[part 16 of 22: packages /Cluster to /NmConfig]
AUTOSAR XML (schema 4-3-0)
package /Cluster  (continued)
  9 x lin cluster, all with baudrate=19200, protocol-name=LIN, protocol-version=2.0:  (continued)
    E3V_SAM_LIN4
      lin physical channel CHNL: comm-connectors=CN_E3V_SAM_LIN4
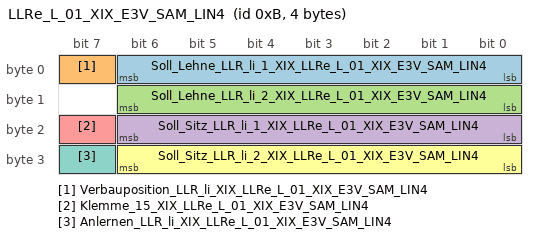
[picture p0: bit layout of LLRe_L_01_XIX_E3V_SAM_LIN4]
        frame LLRe_L_01_XIX_E3V_SAM_LIN4: id 0xB, from SAM, frame-length=4, lin-checksum=ENHANCED
          pdu LLRe_L_01_XIX_E3V_SAM_LIN4: length=4, unused-bit-pattern=0
            signal Soll_Lehne_LLR_li_1_XIX_LLRe_L_01_XIX_E3V_SAM_LIN4: start 0, 7 bit, little-endian, data-type-policy=OVERRIDE, i-signal-type=PRIMITIVE, init-value=0, base-type=BT_Soll_Lehne_LLR_li_1, compu {phys=raw for raw 0..100; unit Unit_PerCent}, range phys 0..100 Unit_PerCent, raw 0..100, unit=Unit_PerCent, transfer-property=PENDING  # Ansteuerung Sitzluefter PWM in %
            signal Verbauposition_LLR_li_XIX_LLRe_L_01_XIX_E3V_SAM_LIN4: start 7, 1 bit, little-endian, data-type-policy=OVERRIDE, i-signal-type=PRIMITIVE, base-type=BT_Verbauposition_LLR_li, compu {0=Cx0_vorne (CM_Verbauposition_LLR_li_Cx0_vorne), 1=Cx1_hinten (CM_Verbauposition_LLR_li_Cx1_hinten)}, range raw 0..1, transfer-property=PENDING  # Verbauposition vorne/hinten für eindeutige Diagnose/Identifikation. Signal für hinten ist immer 0x1, Signal für vorne ist immer 0x0.
            signal Soll_Lehne_LLR_li_2_XIX_LLRe_L_01_XIX_E3V_SAM_LIN4: start 8, 7 bit, little-endian, data-type-policy=OVERRIDE, i-signal-type=PRIMITIVE, init-value=0, base-type=BT_Soll_Lehne_LLR_li_2, compu {phys=raw for raw 0..100; unit Unit_PerCent}, range phys 0..100 Unit_PerCent, raw 0..100, unit=Unit_PerCent, transfer-property=PENDING  # Ansteuerung Sitzluefter PWM in %
            signal Soll_Sitz_LLR_li_1_XIX_LLRe_L_01_XIX_E3V_SAM_LIN4: start 16, 7 bit, little-endian, data-type-policy=OVERRIDE, i-signal-type=PRIMITIVE, init-value=0, base-type=BT_Soll_Sitz_LLR_li_1, compu {phys=raw for raw 0..100; unit Unit_PerCent}, range phys 0..100 Unit_PerCent, raw 0..100, unit=Unit_PerCent, transfer-property=PENDING  # Ansteuerung Sitzluefter PWM in %
            signal Klemme_15_XIX_LLRe_L_01_XIX_E3V_SAM_LIN4: start 23, 1 bit, little-endian, data-type-policy=OVERRIDE, i-signal-type=PRIMITIVE, init-value=0, base-type=BT_Klemme_15, compu {0=Cx0_Aus (CM_Klemme_15_Cx0_Aus), 1=Cx1_Ein (CM_Klemme_15_Cx1_Ein)}, range raw 0..1, transfer-property=PENDING
            signal Soll_Sitz_LLR_li_2_XIX_LLRe_L_01_XIX_E3V_SAM_LIN4: start 24, 7 bit, little-endian, data-type-policy=OVERRIDE, i-signal-type=PRIMITIVE, init-value=0, base-type=BT_Soll_Sitz_LLR_li_2, compu {phys=raw for raw 0..100; unit Unit_PerCent}, range phys 0..100 Unit_PerCent, raw 0..100, unit=Unit_PerCent, transfer-property=PENDING  # Ansteuerung Sitzluefter PWM in %
            signal Anlernen_LLR_li_XIX_LLRe_L_01_XIX_E3V_SAM_LIN4: start 31, 1 bit, little-endian, data-type-policy=OVERRIDE, i-signal-type=PRIMITIVE, init-value=0, base-type=BT_Anlernen_LLR_li, compu {0=Cx0_Init (CM_Anlernen_LLR_li_Cx0_Init), 1=Cx1_Adresse_lernen (CM_Anlernen_LLR_li_Cx1_Adresse_lernen)}, range raw 0..1, transfer-property=PENDING  # Triggersignale zum Anlernen der Slave SG abhängig vom CodierPin
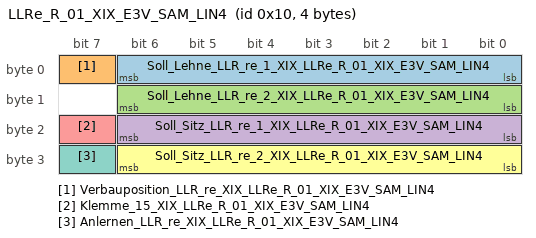
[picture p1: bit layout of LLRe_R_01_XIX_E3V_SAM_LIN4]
        frame LLRe_R_01_XIX_E3V_SAM_LIN4: id 0x10, from SAM, frame-length=4, lin-checksum=ENHANCED
          pdu LLRe_R_01_XIX_E3V_SAM_LIN4: length=4, unused-bit-pattern=0
            signal Soll_Lehne_LLR_re_1_XIX_LLRe_R_01_XIX_E3V_SAM_LIN4: start 0, 7 bit, little-endian, data-type-policy=OVERRIDE, i-signal-type=PRIMITIVE, init-value=0, base-type=BT_Soll_Lehne_LLR_re_1, compu {phys=raw for raw 0..100; unit Unit_PerCent}, range phys 0..100 Unit_PerCent, raw 0..100, unit=Unit_PerCent, transfer-property=PENDING  # Ansteuerung Sitzluefter PWM in %
            signal Verbauposition_LLR_re_XIX_LLRe_R_01_XIX_E3V_SAM_LIN4: start 7, 1 bit, little-endian, data-type-policy=OVERRIDE, i-signal-type=PRIMITIVE, base-type=BT_Verbauposition_LLR_re, compu {0=Cx0_vorne (CM_Verbauposition_LLR_re_Cx0_vorne), 1=Cx1_hinten (CM_Verbauposition_LLR_re_Cx1_hinten)}, range raw 0..1, transfer-property=PENDING  # Verbauposition vorne/hinten für eindeutige Diagnose/Identifikation. Signal für hinten ist immer 0x1, Signal für vorne ist immer 0x0.
            signal Soll_Lehne_LLR_re_2_XIX_LLRe_R_01_XIX_E3V_SAM_LIN4: start 8, 7 bit, little-endian, data-type-policy=OVERRIDE, i-signal-type=PRIMITIVE, init-value=0, base-type=BT_Soll_Lehne_LLR_re_2, compu {phys=raw for raw 0..100; unit Unit_PerCent}, range phys 0..100 Unit_PerCent, raw 0..100, unit=Unit_PerCent, transfer-property=PENDING  # Ansteuerung Sitzluefter PWM in %
            signal Soll_Sitz_LLR_re_1_XIX_LLRe_R_01_XIX_E3V_SAM_LIN4: start 16, 7 bit, little-endian, data-type-policy=OVERRIDE, i-signal-type=PRIMITIVE, init-value=0, base-type=BT_Soll_Sitz_LLR_re_1, compu {phys=raw for raw 0..100; unit Unit_PerCent}, range phys 0..100 Unit_PerCent, raw 0..100, unit=Unit_PerCent, transfer-property=PENDING  # Ansteuerung Sitzluefter PWM in %
            signal Klemme_15_XIX_LLRe_R_01_XIX_E3V_SAM_LIN4: start 23, 1 bit, little-endian, data-type-policy=OVERRIDE, i-signal-type=PRIMITIVE, init-value=0, base-type=BT_Klemme_15, compu {0=Cx0_Aus (CM_Klemme_15_Cx0_Aus), 1=Cx1_Ein (CM_Klemme_15_Cx1_Ein)}, range raw 0..1, transfer-property=PENDING
            signal Soll_Sitz_LLR_re_2_XIX_LLRe_R_01_XIX_E3V_SAM_LIN4: start 24, 7 bit, little-endian, data-type-policy=OVERRIDE, i-signal-type=PRIMITIVE, init-value=0, base-type=BT_Soll_Sitz_LLR_re_2, compu {phys=raw for raw 0..100; unit Unit_PerCent}, range phys 0..100 Unit_PerCent, raw 0..100, unit=Unit_PerCent, transfer-property=PENDING  # Ansteuerung Sitzluefter PWM in %
            signal Anlernen_LLR_re_XIX_LLRe_R_01_XIX_E3V_SAM_LIN4: start 31, 1 bit, little-endian, data-type-policy=OVERRIDE, i-signal-type=PRIMITIVE, init-value=0, base-type=BT_Anlernen_LLR_re, compu {0=Cx0_Init (CM_Anlernen_LLR_re_Cx0_Init), 1=Cx1_Adresse_lernen (CM_Anlernen_LLR_re_Cx1_Adresse_lernen)}, range raw 0..1, transfer-property=PENDING  # Triggersignale zum Anlernen der Slave SG abhängig vom CodierPin
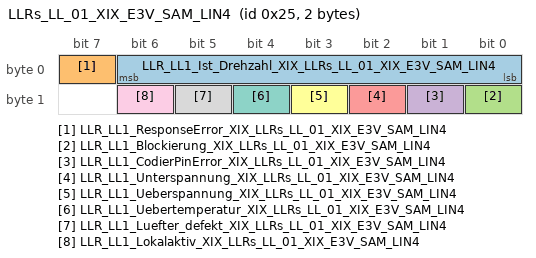
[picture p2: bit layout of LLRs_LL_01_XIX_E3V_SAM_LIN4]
        frame LLRs_LL_01_XIX_E3V_SAM_LIN4: id 0x25, to SAM, frame-length=2, lin-checksum=ENHANCED
          pdu LLRs_LL_01_XIX_E3V_SAM_LIN4: length=2, unused-bit-pattern=0
            signal LLR_LL1_Ist_Drehzahl_XIX_LLRs_LL_01_XIX_E3V_SAM_LIN4: start 0, 7 bit, little-endian, data-type-policy=OVERRIDE, i-signal-type=PRIMITIVE, init-value=0, base-type=BT_LLR_LL1_Ist_Drehzahl, compu {phys=raw for raw 0..100; unit Unit_PerCent}, range phys 0..100 Unit_PerCent, raw 0..100, unit=Unit_PerCent, transfer-property=PENDING, to SAM(timeout 3.5 s)  # Fehlende Beschreibung (Import)
            signal LLR_LL1_ResponseError_XIX_LLRs_LL_01_XIX_E3V_SAM_LIN4: start 7, 1 bit, little-endian, data-type-policy=OVERRIDE, i-signal-type=PRIMITIVE, init-value=0, base-type=BT_LLR_LL1_ResponseError, invalid-value=Invalid_LLR_LL1_ResponseError_XIX_LLRs_LL_01_XIX_E3V_SAM_LIN4:1, compu {0=Cx0_normal (CM_LLR_LL1_ResponseError_Cx0_normal), 1=Cx1_Fehler (CM_LLR_LL1_ResponseError_Cx1_Fehler)}, range raw 0..1, transfer-property=PENDING, to SAM(timeout 3.5 s)  # siehe LIN2.0-Specification (Darf nicht über ein Fehlergueltigkeitsbit abgesichtert werden!)
            signal LLR_LL1_Blockierung_XIX_LLRs_LL_01_XIX_E3V_SAM_LIN4: start 8, 1 bit, little-endian, data-type-policy=OVERRIDE, i-signal-type=PRIMITIVE, init-value=0, base-type=BT_LLR_LL1_Blockierung, compu {0=Cx0_kein_Fehler (CM_LLR_LL1_Blockierung_Cx0_kein_Fehler), 1=Cx1_Blockierung_Kompressor_Fehler (CM_LLR_LL1_Blockierung_Cx1_Blockierung_Kompressor_Fehler)}, range raw 0..1, transfer-property=PENDING, to SAM(timeout 3.5 s)  # Blockierung des Lüfters erkannt Geforderte Solldrehzahl kann nicht erreicht werden
            signal LLR_LL1_CodierPinError_XIX_LLRs_LL_01_XIX_E3V_SAM_LIN4: start 9, 1 bit, little-endian, data-type-policy=OVERRIDE, i-signal-type=PRIMITIVE, init-value=0, base-type=BT_LLR_LL1_CodierPinError, compu {0=Cx0_kein_Fehler (CM_LLR_LL1_CodierPinError_Cx0_kein_Fehler), 1=Cx1_HW_Codierung_Fehler (CM_LLR_LL1_CodierPinError_Cx1_HW_Codierung_Fehler)}, range raw 0..1, transfer-property=PENDING, to SAM(timeout 3.5 s)  # Fehlende Beschreibung (Import)
            signal LLR_LL1_Unterspannung_XIX_LLRs_LL_01_XIX_E3V_SAM_LIN4: start 10, 1 bit, little-endian, data-type-policy=OVERRIDE, i-signal-type=PRIMITIVE, init-value=0, base-type=BT_LLR_LL1_Unterspannung, invalid-value=Invalid_LLR_LL1_Unterspannung_XIX_LLRs_LL_01_XIX_E3V_SAM_LIN4:1, compu {0=Cx0_normal (CM_LLR_LL1_Unterspannung_Cx0_normal), 1=Cx1_Fehler (CM_LLR_LL1_Unterspannung_Cx1_Fehler)}, range raw 0..1, transfer-property=PENDING, to SAM(timeout 3.5 s)  # Fehlende Beschreibung (Import)
            signal LLR_LL1_Ueberspannung_XIX_LLRs_LL_01_XIX_E3V_SAM_LIN4: start 11, 1 bit, little-endian, data-type-policy=OVERRIDE, i-signal-type=PRIMITIVE, init-value=0, base-type=BT_LLR_LL1_Ueberspannung, invalid-value=Invalid_LLR_LL1_Ueberspannung_XIX_LLRs_LL_01_XIX_E3V_SAM_LIN4:1, compu {0=Cx0_normal (CM_LLR_LL1_Ueberspannung_Cx0_normal), 1=Cx1_Fehler (CM_LLR_LL1_Ueberspannung_Cx1_Fehler)}, range raw 0..1, transfer-property=PENDING, to SAM(timeout 3.5 s)  # Fehlende Beschreibung (Import)
            signal LLR_LL1_Uebertemperatur_XIX_LLRs_LL_01_XIX_E3V_SAM_LIN4: start 12, 1 bit, little-endian, data-type-policy=OVERRIDE, i-signal-type=PRIMITIVE, init-value=0, base-type=BT_LLR_LL1_Uebertemperatur, invalid-value=Invalid_LLR_LL1_Uebertemperatur_XIX_LLRs_LL_01_XIX_E3V_SAM_LIN4:1, compu {0=Cx0_normal (CM_LLR_LL1_Uebertemperatur_Cx0_normal), 1=Cx1_Fehler (CM_LLR_LL1_Uebertemperatur_Cx1_Fehler)}, range raw 0..1, transfer-property=PENDING, to SAM(timeout 3.5 s)  # Fehlende Beschreibung (Import)
            signal LLR_LL1_Luefter_defekt_XIX_LLRs_LL_01_XIX_E3V_SAM_LIN4: start 13, 1 bit, little-endian, data-type-policy=OVERRIDE, i-signal-type=PRIMITIVE, init-value=0, base-type=BT_LLR_LL1_Luefter_defekt, compu {0=Cx0_Luefter_iO (CM_LLR_LL1_Luefter_defekt_Cx0_Luefter_iO), 1=Cx1_Luefter_defekt (CM_LLR_LL1_Luefter_defekt_Cx1_Luefter_defekt)}, range raw 0..1, transfer-property=PENDING, to SAM(timeout 3.5 s)  # interner Lüfterdefekt erkannt der zu einem Tausch der BG swingt
            signal LLR_LL1_Lokalaktiv_XIX_LLRs_LL_01_XIX_E3V_SAM_LIN4: start 14, 1 bit, little-endian, data-type-policy=OVERRIDE, i-signal-type=PRIMITIVE, init-value=0, base-type=BT_LLR_LL1_Lokalaktiv, compu {0=Cx0_war_nicht_lokal_aktiv (CM_LLR_LL1_Lokalaktiv_Cx0_war_nicht_lokal_aktiv), 1=Cx1_war_lokal_aktiv (CM_LLR_LL1_Lokalaktiv_Cx1_war_lokal_aktiv)}, range raw 0..1, transfer-property=PENDING, to SAM(timeout 3.5 s)  # Lüfter war im letzten Sleepmodus lokal aktiv (Nachtlauffunktion)
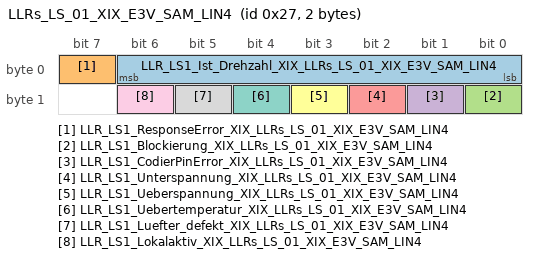
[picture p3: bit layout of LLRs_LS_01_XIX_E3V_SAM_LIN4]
        frame LLRs_LS_01_XIX_E3V_SAM_LIN4: id 0x27, to SAM, frame-length=2, lin-checksum=ENHANCED
          pdu LLRs_LS_01_XIX_E3V_SAM_LIN4: length=2, unused-bit-pattern=0
            signal LLR_LS1_Ist_Drehzahl_XIX_LLRs_LS_01_XIX_E3V_SAM_LIN4: start 0, 7 bit, little-endian, data-type-policy=OVERRIDE, i-signal-type=PRIMITIVE, init-value=0, base-type=BT_LLR_LS1_Ist_Drehzahl, compu {phys=raw for raw 0..100; unit Unit_PerCent}, range phys 0..100 Unit_PerCent, raw 0..100, unit=Unit_PerCent, transfer-property=PENDING, to SAM(timeout 3.5 s)  # Aktuelle Istdrehzahl [%] in Bezug auf Maximalwert
            signal LLR_LS1_ResponseError_XIX_LLRs_LS_01_XIX_E3V_SAM_LIN4: start 7, 1 bit, little-endian, data-type-policy=OVERRIDE, i-signal-type=PRIMITIVE, init-value=0, base-type=BT_LLR_LS1_ResponseError, invalid-value=Invalid_LLR_LS1_ResponseError_XIX_LLRs_LS_01_XIX_E3V_SAM_LIN4:1, compu {0=Cx0_normal (CM_LLR_LS1_ResponseError_Cx0_normal), 1=Cx1_Fehler (CM_LLR_LS1_ResponseError_Cx1_Fehler)}, range raw 0..1, transfer-property=PENDING, to SAM(timeout 3.5 s)  # siehe LIN2.0-Specification (Darf nicht über ein Fehlergueltigkeitsbit abgesichtert werden!)
            signal LLR_LS1_Blockierung_XIX_LLRs_LS_01_XIX_E3V_SAM_LIN4: start 8, 1 bit, little-endian, data-type-policy=OVERRIDE, i-signal-type=PRIMITIVE, init-value=0, base-type=BT_LLR_LS1_Blockierung, compu {0=Cx0_kein_Fehler (CM_LLR_LS1_Blockierung_Cx0_kein_Fehler), 1=Cx1_Blockierung_Kompressor_Fehler (CM_LLR_LS1_Blockierung_Cx1_Blockierung_Kompressor_Fehler)}, range raw 0..1, transfer-property=PENDING, to SAM(timeout 3.5 s)  # Fehlende Beschreibung (Import)
            signal LLR_LS1_CodierPinError_XIX_LLRs_LS_01_XIX_E3V_SAM_LIN4: start 9, 1 bit, little-endian, data-type-policy=OVERRIDE, i-signal-type=PRIMITIVE, init-value=0, base-type=BT_LLR_LS1_CodierPinError, compu {0=Cx0_kein_Fehler (CM_LLR_LS1_CodierPinError_Cx0_kein_Fehler), 1=Cx1_HW_Codierung_Fehler (CM_LLR_LS1_CodierPinError_Cx1_HW_Codierung_Fehler)}, range raw 0..1, transfer-property=PENDING, to SAM(timeout 3.5 s)  # Fehlende Beschreibung (Import)
            signal LLR_LS1_Unterspannung_XIX_LLRs_LS_01_XIX_E3V_SAM_LIN4: start 10, 1 bit, little-endian, data-type-policy=OVERRIDE, i-signal-type=PRIMITIVE, init-value=0, base-type=BT_LLR_LS1_Unterspannung, invalid-value=Invalid_LLR_LS1_Unterspannung_XIX_LLRs_LS_01_XIX_E3V_SAM_LIN4:1, compu {0=Cx0_normal (CM_LLR_LS1_Unterspannung_Cx0_normal), 1=Cx1_Fehler (CM_LLR_LS1_Unterspannung_Cx1_Fehler)}, range raw 0..1, transfer-property=PENDING, to SAM(timeout 3.5 s)  # lokal Unterspannung erkannt
            signal LLR_LS1_Ueberspannung_XIX_LLRs_LS_01_XIX_E3V_SAM_LIN4: start 11, 1 bit, little-endian, data-type-policy=OVERRIDE, i-signal-type=PRIMITIVE, init-value=0, base-type=BT_LLR_LS1_Ueberspannung, invalid-value=Invalid_LLR_LS1_Ueberspannung_XIX_LLRs_LS_01_XIX_E3V_SAM_LIN4:1, compu {0=Cx0_normal (CM_LLR_LS1_Ueberspannung_Cx0_normal), 1=Cx1_Fehler (CM_LLR_LS1_Ueberspannung_Cx1_Fehler)}, range raw 0..1, transfer-property=PENDING, to SAM(timeout 3.5 s)  # Fehlende Beschreibung (Import)
            signal LLR_LS1_Uebertemperatur_XIX_LLRs_LS_01_XIX_E3V_SAM_LIN4: start 12, 1 bit, little-endian, data-type-policy=OVERRIDE, i-signal-type=PRIMITIVE, init-value=0, base-type=BT_LLR_LS1_Uebertemperatur, invalid-value=Invalid_LLR_LS1_Uebertemperatur_XIX_LLRs_LS_01_XIX_E3V_SAM_LIN4:1, compu {0=Cx0_normal (CM_LLR_LS1_Uebertemperatur_Cx0_normal), 1=Cx1_Fehler (CM_LLR_LS1_Uebertemperatur_Cx1_Fehler)}, range raw 0..1, transfer-property=PENDING, to SAM(timeout 3.5 s)  # intern gemessene Baugruppentemperatur liegt ausserhalb des zulässigen Bereichs
            signal LLR_LS1_Luefter_defekt_XIX_LLRs_LS_01_XIX_E3V_SAM_LIN4: start 13, 1 bit, little-endian, data-type-policy=OVERRIDE, i-signal-type=PRIMITIVE, init-value=0, base-type=BT_LLR_LS1_Luefter_defekt, compu {0=Cx0_Luefter_iO (CM_LLR_LS1_Luefter_defekt_Cx0_Luefter_iO), 1=Cx1_Luefter_defekt (CM_LLR_LS1_Luefter_defekt_Cx1_Luefter_defekt)}, range raw 0..1, transfer-property=PENDING, to SAM(timeout 3.5 s)  # interner Lüfterdefekt erkannt der zu einem Tausch der BG swingt
            signal LLR_LS1_Lokalaktiv_XIX_LLRs_LS_01_XIX_E3V_SAM_LIN4: start 14, 1 bit, little-endian, data-type-policy=OVERRIDE, i-signal-type=PRIMITIVE, init-value=0, base-type=BT_LLR_LS1_Lokalaktiv, compu {0=Cx0_war_nicht_lokal_aktiv (CM_LLR_LS1_Lokalaktiv_Cx0_war_nicht_lokal_aktiv), 1=Cx1_war_lokal_aktiv (CM_LLR_LS1_Lokalaktiv_Cx1_war_lokal_aktiv)}, range raw 0..1, transfer-property=PENDING, to SAM(timeout 3.5 s)  # Lüfter war im letzten Sleepmodus lokal aktiv (Nachtlauffunktion)
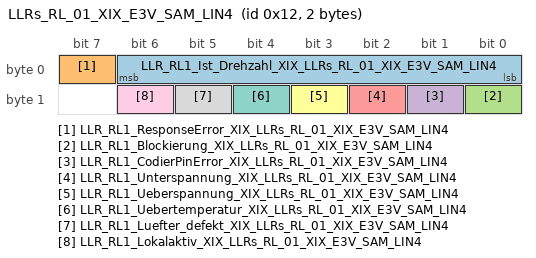
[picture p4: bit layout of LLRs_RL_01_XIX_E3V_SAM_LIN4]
        frame LLRs_RL_01_XIX_E3V_SAM_LIN4: id 0x12, to SAM, frame-length=2, lin-checksum=ENHANCED
          pdu LLRs_RL_01_XIX_E3V_SAM_LIN4: length=2, unused-bit-pattern=0
            signal LLR_RL1_Ist_Drehzahl_XIX_LLRs_RL_01_XIX_E3V_SAM_LIN4: start 0, 7 bit, little-endian, data-type-policy=OVERRIDE, i-signal-type=PRIMITIVE, init-value=0, base-type=BT_LLR_RL1_Ist_Drehzahl, compu {phys=raw for raw 0..100; unit Unit_PerCent}, range phys 0..100 Unit_PerCent, raw 0..100, unit=Unit_PerCent, transfer-property=PENDING, to SAM(timeout 3.5 s)  # Aktuelle Istdrehzahl [%] in Bezug auf Maximalwert
            signal LLR_RL1_ResponseError_XIX_LLRs_RL_01_XIX_E3V_SAM_LIN4: start 7, 1 bit, little-endian, data-type-policy=OVERRIDE, i-signal-type=PRIMITIVE, init-value=0, base-type=BT_LLR_RL1_ResponseError, invalid-value=Invalid_LLR_RL1_ResponseError_XIX_LLRs_RL_01_XIX_E3V_SAM_LIN4:1, compu {0=Cx0_normal (CM_LLR_RL1_ResponseError_Cx0_normal), 1=Cx1_Fehler (CM_LLR_RL1_ResponseError_Cx1_Fehler)}, range raw 0..1, transfer-property=PENDING, to SAM(timeout 3.5 s)  # siehe LIN2.0-Specification (Darf nicht über ein Fehlergueltigkeitsbit abgesichtert werden!)
            signal LLR_RL1_Blockierung_XIX_LLRs_RL_01_XIX_E3V_SAM_LIN4: start 8, 1 bit, little-endian, data-type-policy=OVERRIDE, i-signal-type=PRIMITIVE, init-value=0, base-type=BT_LLR_RL1_Blockierung, compu {0=Cx0_kein_Fehler (CM_LLR_RL1_Blockierung_Cx0_kein_Fehler), 1=Cx1_Blockierung_Kompressor_Fehler (CM_LLR_RL1_Blockierung_Cx1_Blockierung_Kompressor_Fehler)}, range raw 0..1, transfer-property=PENDING, to SAM(timeout 3.5 s)  # Blockierung des Lüfters erkannt Geforderte Solldrehzahl kann nicht erreicht werden
            signal LLR_RL1_CodierPinError_XIX_LLRs_RL_01_XIX_E3V_SAM_LIN4: start 9, 1 bit, little-endian, data-type-policy=OVERRIDE, i-signal-type=PRIMITIVE, init-value=0, base-type=BT_LLR_RL1_CodierPinError, compu {0=Cx0_kein_Fehler (CM_LLR_RL1_CodierPinError_Cx0_kein_Fehler), 1=Cx1_HW_Codierung_Fehler (CM_LLR_RL1_CodierPinError_Cx1_HW_Codierung_Fehler)}, range raw 0..1, transfer-property=PENDING, to SAM(timeout 3.5 s)  # Die eingelesene Leitungssatzkodierung entspricht nicht dem abgespeicherten Sollwert
            signal LLR_RL1_Unterspannung_XIX_LLRs_RL_01_XIX_E3V_SAM_LIN4: start 10, 1 bit, little-endian, data-type-policy=OVERRIDE, i-signal-type=PRIMITIVE, init-value=0, base-type=BT_LLR_RL1_Unterspannung, invalid-value=Invalid_LLR_RL1_Unterspannung_XIX_LLRs_RL_01_XIX_E3V_SAM_LIN4:1, compu {0=Cx0_normal (CM_LLR_RL1_Unterspannung_Cx0_normal), 1=Cx1_Fehler (CM_LLR_RL1_Unterspannung_Cx1_Fehler)}, range raw 0..1, transfer-property=PENDING, to SAM(timeout 3.5 s)  # Fehlende Beschreibung (Import)
            signal LLR_RL1_Ueberspannung_XIX_LLRs_RL_01_XIX_E3V_SAM_LIN4: start 11, 1 bit, little-endian, data-type-policy=OVERRIDE, i-signal-type=PRIMITIVE, init-value=0, base-type=BT_LLR_RL1_Ueberspannung, invalid-value=Invalid_LLR_RL1_Ueberspannung_XIX_LLRs_RL_01_XIX_E3V_SAM_LIN4:1, compu {0=Cx0_normal (CM_LLR_RL1_Ueberspannung_Cx0_normal), 1=Cx1_Fehler (CM_LLR_RL1_Ueberspannung_Cx1_Fehler)}, range raw 0..1, transfer-property=PENDING, to SAM(timeout 3.5 s)  # lokal Überspannung erkannt
            signal LLR_RL1_Uebertemperatur_XIX_LLRs_RL_01_XIX_E3V_SAM_LIN4: start 12, 1 bit, little-endian, data-type-policy=OVERRIDE, i-signal-type=PRIMITIVE, init-value=0, base-type=BT_LLR_RL1_Uebertemperatur, invalid-value=Invalid_LLR_RL1_Uebertemperatur_XIX_LLRs_RL_01_XIX_E3V_SAM_LIN4:1, compu {0=Cx0_normal (CM_LLR_RL1_Uebertemperatur_Cx0_normal), 1=Cx1_Fehler (CM_LLR_RL1_Uebertemperatur_Cx1_Fehler)}, range raw 0..1, transfer-property=PENDING, to SAM(timeout 3.5 s)  # intern gemessene Baugruppentemperatur liegt ausserhalb des zulässigen Bereichs
            signal LLR_RL1_Luefter_defekt_XIX_LLRs_RL_01_XIX_E3V_SAM_LIN4: start 13, 1 bit, little-endian, data-type-policy=OVERRIDE, i-signal-type=PRIMITIVE, init-value=0, base-type=BT_LLR_RL1_Luefter_defekt, compu {0=Cx0_Luefter_iO (CM_LLR_RL1_Luefter_defekt_Cx0_Luefter_iO), 1=Cx1_Luefter_defekt (CM_LLR_RL1_Luefter_defekt_Cx1_Luefter_defekt)}, range raw 0..1, transfer-property=PENDING, to SAM(timeout 3.5 s)  # interner Lüfterdefekt erkannt der zu einem Tausch der BG swingt
            signal LLR_RL1_Lokalaktiv_XIX_LLRs_RL_01_XIX_E3V_SAM_LIN4: start 14, 1 bit, little-endian, data-type-policy=OVERRIDE, i-signal-type=PRIMITIVE, init-value=0, base-type=BT_LLR_RL1_Lokalaktiv, compu {0=Cx0_war_nicht_lokal_aktiv (CM_LLR_RL1_Lokalaktiv_Cx0_war_nicht_lokal_aktiv), 1=Cx1_war_lokal_aktiv (CM_LLR_RL1_Lokalaktiv_Cx1_war_lokal_aktiv)}, range raw 0..1, transfer-property=PENDING, to SAM(timeout 3.5 s)  # Lüfter war im letzten Sleepmodus lokal aktiv (Nachtlauffunktion)
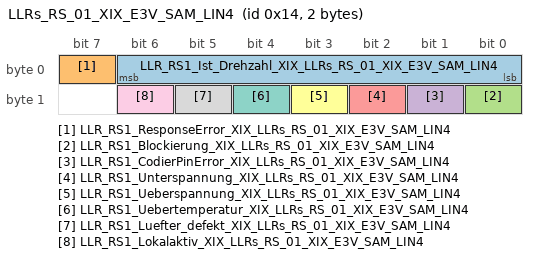
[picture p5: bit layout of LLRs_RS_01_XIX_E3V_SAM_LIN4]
        frame LLRs_RS_01_XIX_E3V_SAM_LIN4: id 0x14, to SAM, frame-length=2, lin-checksum=ENHANCED
          pdu LLRs_RS_01_XIX_E3V_SAM_LIN4: length=2, unused-bit-pattern=0
            signal LLR_RS1_Ist_Drehzahl_XIX_LLRs_RS_01_XIX_E3V_SAM_LIN4: start 0, 7 bit, little-endian, data-type-policy=OVERRIDE, i-signal-type=PRIMITIVE, init-value=0, base-type=BT_LLR_RS1_Ist_Drehzahl, compu {phys=raw for raw 0..100; unit Unit_PerCent}, range phys 0..100 Unit_PerCent, raw 0..100, unit=Unit_PerCent, transfer-property=PENDING, to SAM(timeout 3.5 s)  # Aktuelle Istdrehzahl [%] in Bezug auf Maximalwert
            signal LLR_RS1_ResponseError_XIX_LLRs_RS_01_XIX_E3V_SAM_LIN4: start 7, 1 bit, little-endian, data-type-policy=OVERRIDE, i-signal-type=PRIMITIVE, init-value=0, base-type=BT_LLR_RS1_ResponseError, invalid-value=Invalid_LLR_RS1_ResponseError_XIX_LLRs_RS_01_XIX_E3V_SAM_LIN4:1, compu {0=Cx0_normal (CM_LLR_RS1_ResponseError_Cx0_normal), 1=Cx1_Fehler (CM_LLR_RS1_ResponseError_Cx1_Fehler)}, range raw 0..1, transfer-property=PENDING, to SAM(timeout 3.5 s)  # siehe LIN2.0-Specification (Darf nicht über ein Fehlergueltigkeitsbit abgesichtert werden!)
            signal LLR_RS1_Blockierung_XIX_LLRs_RS_01_XIX_E3V_SAM_LIN4: start 8, 1 bit, little-endian, data-type-policy=OVERRIDE, i-signal-type=PRIMITIVE, init-value=0, base-type=BT_LLR_RS1_Blockierung, compu {0=Cx0_kein_Fehler (CM_LLR_RS1_Blockierung_Cx0_kein_Fehler), 1=Cx1_Blockierung_Kompressor_Fehler (CM_LLR_RS1_Blockierung_Cx1_Blockierung_Kompressor_Fehler)}, range raw 0..1, transfer-property=PENDING, to SAM(timeout 3.5 s)  # Blockierung des Lüfters erkannt Geforderte Solldrehzahl kann nicht erreicht werden
            signal LLR_RS1_CodierPinError_XIX_LLRs_RS_01_XIX_E3V_SAM_LIN4: start 9, 1 bit, little-endian, data-type-policy=OVERRIDE, i-signal-type=PRIMITIVE, init-value=0, base-type=BT_LLR_RS1_CodierPinError, compu {0=Cx0_kein_Fehler (CM_LLR_RS1_CodierPinError_Cx0_kein_Fehler), 1=Cx1_HW_Codierung_Fehler (CM_LLR_RS1_CodierPinError_Cx1_HW_Codierung_Fehler)}, range raw 0..1, transfer-property=PENDING, to SAM(timeout 3.5 s)  # Die eingelesene Leitungssatzkodierung entspricht nicht dem abgespeicherten Sollwert
            signal LLR_RS1_Unterspannung_XIX_LLRs_RS_01_XIX_E3V_SAM_LIN4: start 10, 1 bit, little-endian, data-type-policy=OVERRIDE, i-signal-type=PRIMITIVE, init-value=0, base-type=BT_LLR_RS1_Unterspannung, invalid-value=Invalid_LLR_RS1_Unterspannung_XIX_LLRs_RS_01_XIX_E3V_SAM_LIN4:1, compu {0=Cx0_normal (CM_LLR_RS1_Unterspannung_Cx0_normal), 1=Cx1_Fehler (CM_LLR_RS1_Unterspannung_Cx1_Fehler)}, range raw 0..1, transfer-property=PENDING, to SAM(timeout 3.5 s)  # lokal Unterspannung erkannt
            signal LLR_RS1_Ueberspannung_XIX_LLRs_RS_01_XIX_E3V_SAM_LIN4: start 11, 1 bit, little-endian, data-type-policy=OVERRIDE, i-signal-type=PRIMITIVE, init-value=0, base-type=BT_LLR_RS1_Ueberspannung, invalid-value=Invalid_LLR_RS1_Ueberspannung_XIX_LLRs_RS_01_XIX_E3V_SAM_LIN4:1, compu {0=Cx0_normal (CM_LLR_RS1_Ueberspannung_Cx0_normal), 1=Cx1_Fehler (CM_LLR_RS1_Ueberspannung_Cx1_Fehler)}, range raw 0..1, transfer-property=PENDING, to SAM(timeout 3.5 s)  # lokal Überspannung erkannt
            signal LLR_RS1_Uebertemperatur_XIX_LLRs_RS_01_XIX_E3V_SAM_LIN4: start 12, 1 bit, little-endian, data-type-policy=OVERRIDE, i-signal-type=PRIMITIVE, init-value=0, base-type=BT_LLR_RS1_Uebertemperatur, invalid-value=Invalid_LLR_RS1_Uebertemperatur_XIX_LLRs_RS_01_XIX_E3V_SAM_LIN4:1, compu {0=Cx0_normal (CM_LLR_RS1_Uebertemperatur_Cx0_normal), 1=Cx1_Fehler (CM_LLR_RS1_Uebertemperatur_Cx1_Fehler)}, range raw 0..1, transfer-property=PENDING, to SAM(timeout 3.5 s)  # intern gemessene Baugruppentemperatur liegt ausserhalb des zulässigen Bereichs
            signal LLR_RS1_Luefter_defekt_XIX_LLRs_RS_01_XIX_E3V_SAM_LIN4: start 13, 1 bit, little-endian, data-type-policy=OVERRIDE, i-signal-type=PRIMITIVE, init-value=0, base-type=BT_LLR_RS1_Luefter_defekt, compu {0=Cx0_Luefter_iO (CM_LLR_RS1_Luefter_defekt_Cx0_Luefter_iO), 1=Cx1_Luefter_defekt (CM_LLR_RS1_Luefter_defekt_Cx1_Luefter_defekt)}, range raw 0..1, transfer-property=PENDING, to SAM(timeout 3.5 s)  # interner Lüfterdefekt erkannt der zu einem Tausch der BG swingt
            signal LLR_RS1_Lokalaktiv_XIX_LLRs_RS_01_XIX_E3V_SAM_LIN4: start 14, 1 bit, little-endian, data-type-policy=OVERRIDE, i-signal-type=PRIMITIVE, init-value=0, base-type=BT_LLR_RS1_Lokalaktiv, compu {0=Cx0_war_nicht_lokal_aktiv (CM_LLR_RS1_Lokalaktiv_Cx0_war_nicht_lokal_aktiv), 1=Cx1_war_lokal_aktiv (CM_LLR_RS1_Lokalaktiv_Cx1_war_lokal_aktiv)}, range raw 0..1, transfer-property=PENDING, to SAM(timeout 3.5 s)  # Lüfter war im letzten Sleepmodus lokal aktiv (Nachtlauffunktion)
        frame MasterReq_XIX_E3V_SAM_LIN4: id 0x3C, from SAM, frame-length=8, lin-checksum=CLASSIC
          n pdu MasterReq_XIX_E3V_SAM_LIN4: length=8
        frame SlaveResp_XIX_E3V_SAM_LIN4: id 0x3D, to SAM, frame-length=8, lin-checksum=CLASSIC
          n pdu SlaveResp_XIX_E3V_SAM_LIN4: length=8
        frame SPRe_01_XIX_E3V_SAM_LIN4: id 0x2A, from SAM, frame-length=8, lin-checksum=ENHANCED
          pdu SPRe_01_XIX_E3V_SAM_LIN4: length=8, unused-bit-pattern=0
            signal BCM_FS_aktive_MuFu_Fkt_XIX_SPRe_01_XIX_E3V_SAM_LIN4: start 0, 2 bit, little-endian, data-type-policy=OVERRIDE, i-signal-type=PRIMITIVE, init-value=0, base-type=BT_BCM_FS_aktive_MuFu_Fkt, compu {0=Cx0_Menue_inaktiv (CM_BCM_FS_aktive_MuFu_Fkt_Cx0_Menue_inaktiv), 1=Cx1_Seitenwangen (CM_BCM_FS_aktive_MuFu_Fkt_Cx1_Seitenwangen), 2=Cx2_Lordose (CM_BCM_FS_aktive_MuFu_Fkt_Cx2_Lordose), 3=Cx3_Massage (CM_BCM_FS_aktive_MuFu_Fkt_Cx3_Massage)}, range raw 0..3, transfer-property=PENDING  # Info aktive MuFu Fkt
            signal BCM_FS_Massage_Intensitaet_XIX_SPRe_01_XIX_E3V_SAM_LIN4: start 2, 2 bit, little-endian, data-type-policy=OVERRIDE, i-signal-type=PRIMITIVE, init-value=0, base-type=BT_BCM_FS_Massage_Intensitaet, compu {0=Cx0_Aus (CM_BCM_FS_Massage_Intensitaet_Cx0_Aus), 1=Cx1_Stufe_1 (CM_BCM_FS_Massage_Intensitaet_Cx1_Stufe_1), 2=Cx2_Stufe_2 (CM_BCM_FS_Massage_Intensitaet_Cx2_Stufe_2), 3=Cx3_Stufe_3 (CM_BCM_FS_Massage_Intensitaet_Cx3_Stufe_3)}, range raw 0..3, transfer-property=PENDING  # Info Massage Intensität
            signal BCM_FS_Massage_Prg_XIX_SPRe_01_XIX_E3V_SAM_LIN4: start 4, 2 bit, little-endian, data-type-policy=OVERRIDE, i-signal-type=PRIMITIVE, init-value=0, base-type=BT_BCM_FS_Massage_Prg, compu {0=Cx0_Aus (CM_BCM_FS_Massage_Prg_Cx0_Aus), 1=Cx1_Programm1 (CM_BCM_FS_Massage_Prg_Cx1_Programm1), 2=Cx2_Programm2 (CM_BCM_FS_Massage_Prg_Cx2_Programm2), 3=Cx3_Programm3 (CM_BCM_FS_Massage_Prg_Cx3_Programm3)}, range raw 0..3, transfer-property=PENDING  # Info Massage Programm
            signal BCM_FS_Memory_Pos_XIX_SPRe_01_XIX_E3V_SAM_LIN4: start 6, 2 bit, little-endian, data-type-policy=OVERRIDE, i-signal-type=PRIMITIVE, init-value=0, base-type=BT_BCM_FS_Memory_Pos, compu {0=Cx0_Keine_Zuweisung (CM_BCM_FS_Memory_Pos_Cx0_Keine_Zuweisung), 1=Cx1_P1_Pos_Zuweisung (CM_BCM_FS_Memory_Pos_Cx1_P1_Pos_Zuweisung), 2=Cx2_P2_Pos_Zuweisung (CM_BCM_FS_Memory_Pos_Cx2_P2_Pos_Zuweisung), 3=Cx3_P3_Pos_Zuweisung (CM_BCM_FS_Memory_Pos_Cx3_P3_Pos_Zuweisung)}, range raw 0..3, transfer-property=PENDING  # Info Memory Position
            signal BCM_FS_Memory_Abbruch_XIX_SPRe_01_XIX_E3V_SAM_LIN4: start 8, 1 bit, little-endian, data-type-policy=OVERRIDE, i-signal-type=PRIMITIVE, init-value=0, base-type=BT_BCM_FS_Memory_Abbruch, compu {0=Cx0_inaktiv (CM_BCM_FS_Memory_Abbruch_Cx0_inaktiv), 1=Cx1_aktiv (CM_BCM_FS_Memory_Abbruch_Cx1_aktiv)}, range raw 0..1, transfer-property=PENDING  # Info Memory Abbruch
            signal BCM_FS_Memory_Save_Recall_XIX_SPRe_01_XIX_E3V_SAM_LIN4: start 9, 1 bit, little-endian, data-type-policy=OVERRIDE, i-signal-type=PRIMITIVE, init-value=0, base-type=BT_BCM_FS_Memory_Save_Recall, compu {0=Cx0_save (CM_BCM_FS_Memory_Save_Recall_Cx0_save), 1=Cx1_recall (CM_BCM_FS_Memory_Save_Recall_Cx1_recall)}, range raw 0..1, transfer-property=PENDING  # Info Memory Save Recall
            signal BCM_FT_geoeffnet_plaus_XIX_SPRe_01_XIX_E3V_SAM_LIN4: start 10, 1 bit, little-endian, data-type-policy=OVERRIDE, i-signal-type=PRIMITIVE, init-value=0, base-type=BT_BCM_FT_geoeffnet_plaus, compu {0=Cx0_geschlossen (CM_BCM_FT_geoeffnet_plaus_Cx0_geschlossen), 1=Cx1_offen (CM_BCM_FT_geoeffnet_plaus_Cx1_offen)}, range raw 0..1, transfer-property=PENDING  # mit Geschw. plausibilisierte Türinfo
            signal BCM_Fehlerspeicher_loeschen_XIX_SPRe_01_XIX_E3V_SAM_LIN4: start 11, 1 bit, little-endian, data-type-policy=OVERRIDE, i-signal-type=PRIMITIVE, init-value=0, base-type=BT_BCM_Fehlerspeicher_loeschen, compu {0=Cx0_inaktiv (CM_BCM_Fehlerspeicher_loeschen_Cx0_inaktiv), 1=Cx1_aktiv (CM_BCM_Fehlerspeicher_loeschen_Cx1_aktiv)}, range raw 0..1, transfer-property=PENDING  # Trigger für Fehlerspeicher löschen im SPR links und rechts
            signal BCM_Kennung_RL_Fzg_XIX_SPRe_01_XIX_E3V_SAM_LIN4: start 12, 1 bit, little-endian, data-type-policy=OVERRIDE, i-signal-type=PRIMITIVE, init-value=0, base-type=BT_BCM_Kennung_RL_Fzg, compu {0=Cx0_links (CM_BCM_Kennung_RL_Fzg_Cx0_links), 1=Cx1_rechts (CM_BCM_Kennung_RL_Fzg_Cx1_rechts)}, range raw 0..1, transfer-property=PENDING  # Information über Rechts-/Linkslenker Fzg.
            signal BCM_P_Mode_aktiv_XIX_SPRe_01_XIX_E3V_SAM_LIN4: start 13, 1 bit, little-endian, data-type-policy=OVERRIDE, i-signal-type=PRIMITIVE, init-value=0, base-type=BT_BCM_P_Mode_aktiv, compu {0=Cx0_inaktiv (CM_BCM_P_Mode_aktiv_Cx0_inaktiv), 1=Cx1_aktiv (CM_BCM_P_Mode_aktiv_Cx1_aktiv)}, range raw 0..1, transfer-property=PENDING  # Produkions Modus über Diagnose aktiviert
            signal BCM_SBE_XIX_SPRe_01_XIX_E3V_SAM_LIN4: start 14, 2 bit, little-endian, data-type-policy=OVERRIDE, i-signal-type=PRIMITIVE, base-type=BT_BCM_SBE, invalid-value=Invalid_BCM_SBE_XIX_SPRe_01_XIX_E3V_SAM_LIN4:1, compu {0=Cx0_nicht_verfuegbar (CM_BCM_SBE_Cx0_nicht_verfuegbar), 1=Cx1_Fehler (CM_BCM_SBE_Cx1_Fehler), 2=Cx2_nicht_belegt (CM_BCM_SBE_Cx2_nicht_belegt), 3=Cx3_belegt (CM_BCM_SBE_Cx3_belegt)}, range raw 0..3, transfer-property=PENDING  # Info der Beifahrer Sitzbelegung
            signal BCM_SGT_Pumpe_FS_XIX_SPRe_01_XIX_E3V_SAM_LIN4: start 16, 1 bit, little-endian, data-type-policy=OVERRIDE, i-signal-type=PRIMITIVE, init-value=0, base-type=BT_BCM_SGT_Pumpe_FS, compu {0=Cx0_inaktiv (CM_BCM_SGT_Pumpe_FS_Cx0_inaktiv), 1=Cx1_aktiv (CM_BCM_SGT_Pumpe_FS_Cx1_aktiv)}, range raw 0..1, transfer-property=PENDING  # Stellgliedtest Pumpe Fahrerseite
            signal BCM_Systemfunkionstest_FS_XIX_SPRe_01_XIX_E3V_SAM_LIN4: start 17, 1 bit, little-endian, data-type-policy=OVERRIDE, i-signal-type=PRIMITIVE, init-value=0, base-type=BT_BCM_Systemfunkionstest_FS, compu {0=Cx0_inaktiv (CM_BCM_Systemfunkionstest_FS_Cx0_inaktiv), 1=Cx1_aktiv (CM_BCM_Systemfunkionstest_FS_Cx1_aktiv)}, range raw 0..1, transfer-property=PENDING  # Systemfunktionstest SPR Fahrerseite
            signal BCM_BFS_aktive_MuFu_Fkt_XIX_SPRe_01_XIX_E3V_SAM_LIN4: start 18, 2 bit, little-endian, data-type-policy=OVERRIDE, i-signal-type=PRIMITIVE, init-value=0, base-type=BT_BCM_BFS_aktive_MuFu_Fkt, compu {0=Cx0_Menue_inaktiv (CM_BCM_BFS_aktive_MuFu_Fkt_Cx0_Menue_inaktiv), 1=Cx1_Seitenwangen (CM_BCM_BFS_aktive_MuFu_Fkt_Cx1_Seitenwangen), 2=Cx2_Lordose (CM_BCM_BFS_aktive_MuFu_Fkt_Cx2_Lordose), 3=Cx3_Massage (CM_BCM_BFS_aktive_MuFu_Fkt_Cx3_Massage)}, range raw 0..3, transfer-property=PENDING  # Info aktive MuFu Fkt
            signal BCM_BFS_Lordose_ab_XIX_SPRe_01_XIX_E3V_SAM_LIN4: start 20, 1 bit, little-endian, data-type-policy=OVERRIDE, i-signal-type=PRIMITIVE, init-value=0, base-type=BT_BCM_BFS_Lordose_ab, compu {0=Cx0_inaktiv (CM_BCM_BFS_Lordose_ab_Cx0_inaktiv), 1=Cx1_aktiv (CM_BCM_BFS_Lordose_ab_Cx1_aktiv)}, range raw 0..1, transfer-property=PENDING  # Fernsteuerung BFS Lordose ab
            signal BCM_BFS_Lordose_auf_XIX_SPRe_01_XIX_E3V_SAM_LIN4: start 21, 1 bit, little-endian, data-type-policy=OVERRIDE, i-signal-type=PRIMITIVE, init-value=0, base-type=BT_BCM_BFS_Lordose_auf, compu {0=Cx0_inaktiv (CM_BCM_BFS_Lordose_auf_Cx0_inaktiv), 1=Cx1_aktiv (CM_BCM_BFS_Lordose_auf_Cx1_aktiv)}, range raw 0..1, transfer-property=PENDING  # Fernsteuerung BFS Lordose auf
            signal BCM_BFS_Lordose_vor_XIX_SPRe_01_XIX_E3V_SAM_LIN4: start 22, 1 bit, little-endian, data-type-policy=OVERRIDE, i-signal-type=PRIMITIVE, init-value=0, base-type=BT_BCM_BFS_Lordose_vor, compu {0=Cx0_inaktiv (CM_BCM_BFS_Lordose_vor_Cx0_inaktiv), 1=Cx1_aktiv (CM_BCM_BFS_Lordose_vor_Cx1_aktiv)}, range raw 0..1, transfer-property=PENDING  # Fernsteuerung BFS Lordose vor
            signal BCM_BFS_Lordose_zurueck_XIX_SPRe_01_XIX_E3V_SAM_LIN4: start 23, 1 bit, little-endian, data-type-policy=OVERRIDE, i-signal-type=PRIMITIVE, init-value=0, base-type=BT_BCM_BFS_Lordose_zurueck, compu {0=Cx0_inaktiv (CM_BCM_BFS_Lordose_zurueck_Cx0_inaktiv), 1=Cx1_aktiv (CM_BCM_BFS_Lordose_zurueck_Cx1_aktiv)}, range raw 0..1, transfer-property=PENDING  # Fernsteuerung BFS Lordose zurück
            signal BCM_BFS_Massage_Intensitaet_XIX_SPRe_01_XIX_E3V_SAM_LIN4: start 24, 2 bit, little-endian, data-type-policy=OVERRIDE, i-signal-type=PRIMITIVE, init-value=0, base-type=BT_BCM_BFS_Massage_Intensitaet, compu {0=Cx0_Aus (CM_BCM_BFS_Massage_Intensitaet_Cx0_Aus), 1=Cx1_Stufe_1 (CM_BCM_BFS_Massage_Intensitaet_Cx1_Stufe_1), 2=Cx2_Stufe_2 (CM_BCM_BFS_Massage_Intensitaet_Cx2_Stufe_2), 3=Cx3_Stufe_3 (CM_BCM_BFS_Massage_Intensitaet_Cx3_Stufe_3)}, range raw 0..3, transfer-property=PENDING  # Info Massage Intensität
            signal BCM_BFS_Massage_Prg_XIX_SPRe_01_XIX_E3V_SAM_LIN4: start 26, 2 bit, little-endian, data-type-policy=OVERRIDE, i-signal-type=PRIMITIVE, init-value=0, base-type=BT_BCM_BFS_Massage_Prg, compu {0=Cx0_Aus (CM_BCM_BFS_Massage_Prg_Cx0_Aus), 1=Cx1_Programm1 (CM_BCM_BFS_Massage_Prg_Cx1_Programm1), 2=Cx2_Programm2 (CM_BCM_BFS_Massage_Prg_Cx2_Programm2), 3=Cx3_Programm3 (CM_BCM_BFS_Massage_Prg_Cx3_Programm3)}, range raw 0..3, transfer-property=PENDING  # Info Massage Programm
            signal BCM_BFS_Memory_Abbruch_XIX_SPRe_01_XIX_E3V_SAM_LIN4: start 28, 1 bit, little-endian, data-type-policy=OVERRIDE, i-signal-type=PRIMITIVE, init-value=0, base-type=BT_BCM_BFS_Memory_Abbruch, compu {0=Cx0_inaktiv (CM_BCM_BFS_Memory_Abbruch_Cx0_inaktiv), 1=Cx1_aktiv (CM_BCM_BFS_Memory_Abbruch_Cx1_aktiv)}, range raw 0..1, transfer-property=PENDING  # Info Memory Abbruch
            signal BCM_BFS_Memory_Pos_XIX_SPRe_01_XIX_E3V_SAM_LIN4: start 29, 2 bit, little-endian, data-type-policy=OVERRIDE, i-signal-type=PRIMITIVE, init-value=0, base-type=BT_BCM_BFS_Memory_Pos, compu {0=Cx0_Keine_Zuweisung (CM_BCM_BFS_Memory_Pos_Cx0_Keine_Zuweisung), 1=Cx1_P1_Pos_Zuweisung (CM_BCM_BFS_Memory_Pos_Cx1_P1_Pos_Zuweisung), 2=Cx2_P2_Pos_Zuweisung (CM_BCM_BFS_Memory_Pos_Cx2_P2_Pos_Zuweisung), 3=Cx3_P3_Pos_Zuweisung (CM_BCM_BFS_Memory_Pos_Cx3_P3_Pos_Zuweisung)}, range raw 0..3, transfer-property=PENDING  # Info Memory Position
            signal BCM_BFS_Memory_Save_Recall_XIX_SPRe_01_XIX_E3V_SAM_LIN4: start 31, 1 bit, little-endian, data-type-policy=OVERRIDE, i-signal-type=PRIMITIVE, init-value=0, base-type=BT_BCM_BFS_Memory_Save_Recall, compu {0=Cx0_save (CM_BCM_BFS_Memory_Save_Recall_Cx0_save), 1=Cx1_recall (CM_BCM_BFS_Memory_Save_Recall_Cx1_recall)}, range raw 0..1, transfer-property=PENDING  # Info Memory Save Recall
            signal BCM_BFS_SW_eng_XIX_SPRe_01_XIX_E3V_SAM_LIN4: start 32, 1 bit, little-endian, data-type-policy=OVERRIDE, i-signal-type=PRIMITIVE, init-value=0, base-type=BT_BCM_BFS_SW_eng, compu {0=Cx0_inaktiv (CM_BCM_BFS_SW_eng_Cx0_inaktiv), 1=Cx1_aktiv (CM_BCM_BFS_SW_eng_Cx1_aktiv)}, range raw 0..1, transfer-property=PENDING  # Fernsteuerung BFS Seitenwangen eng
            signal BCM_BFS_SW_weit_XIX_SPRe_01_XIX_E3V_SAM_LIN4: start 33, 1 bit, little-endian, data-type-policy=OVERRIDE, i-signal-type=PRIMITIVE, init-value=0, base-type=BT_BCM_BFS_SW_weit, compu {0=Cx0_inaktiv (CM_BCM_BFS_SW_weit_Cx0_inaktiv), 1=Cx1_aktiv (CM_BCM_BFS_SW_weit_Cx1_aktiv)}, range raw 0..1, transfer-property=PENDING  # Fernsteuerung BFS Seitenwangen weit
            signal BCM_BFT_geoeffnet_plaus_XIX_SPRe_01_XIX_E3V_SAM_LIN4: start 34, 1 bit, little-endian, data-type-policy=OVERRIDE, i-signal-type=PRIMITIVE, init-value=0, base-type=BT_BCM_BFT_geoeffnet_plaus, compu {0=Cx0_geschlossen (CM_BCM_BFT_geoeffnet_plaus_Cx0_geschlossen), 1=Cx1_offen (CM_BCM_BFT_geoeffnet_plaus_Cx1_offen)}, range raw 0..1, transfer-property=PENDING  # mit Geschw. plausibilisierte Türinfo
            signal BCM_SGT_Pumpe_BFS_XIX_SPRe_01_XIX_E3V_SAM_LIN4: start 35, 1 bit, little-endian, data-type-policy=OVERRIDE, i-signal-type=PRIMITIVE, init-value=0, base-type=BT_BCM_SGT_Pumpe_BFS, compu {0=Cx0_inaktiv (CM_BCM_SGT_Pumpe_BFS_Cx0_inaktiv), 1=Cx1_aktiv (CM_BCM_SGT_Pumpe_BFS_Cx1_aktiv)}, range raw 0..1, transfer-property=PENDING  # Info Memory Abbruch
            signal BCM_Systemfunkionstest_BFS_XIX_SPRe_01_XIX_E3V_SAM_LIN4: start 36, 1 bit, little-endian, data-type-policy=OVERRIDE, i-signal-type=PRIMITIVE, init-value=0, base-type=BT_BCM_Systemfunkionstest_BFS, compu {0=Cx0_inaktiv (CM_BCM_Systemfunkionstest_BFS_Cx0_inaktiv), 1=Cx1_aktiv (CM_BCM_Systemfunkionstest_BFS_Cx1_aktiv)}, range raw 0..1, transfer-property=PENDING  # Systemfunktionstest SPR Beifahrerseite
            signal BCM_BFS_Fernsteuerung_aktiv_XIX_SPRe_01_XIX_E3V_SAM_LIN4: start 37, 1 bit, little-endian, data-type-policy=OVERRIDE, i-signal-type=PRIMITIVE, init-value=0, base-type=BT_BCM_BFS_Fernsteuerung_aktiv, compu {0=Cx0_inaktiv (CM_BCM_BFS_Fernsteuerung_aktiv_Cx0_inaktiv), 1=Cx1_aktiv (CM_BCM_BFS_Fernsteuerung_aktiv_Cx1_aktiv)}, range raw 0..1, transfer-property=PENDING  # Fernsteuerung BFS aktiv
            signal BCM1_EasyEntry_Status_XIX_SPRe_01_XIX_E3V_SAM_LIN4: start 38, 1 bit, little-endian, data-type-policy=OVERRIDE, i-signal-type=PRIMITIVE, init-value=0, base-type=BT_BCM1_EasyEntry_Status, compu {0=Cx0_Aus (CM_BCM1_EasyEntry_Status_Cx0_Aus), 1=Cx1_Ein (CM_BCM1_EasyEntry_Status_Cx1_Ein)}, range raw 0..1, transfer-property=PENDING  # Status EasyEntry für Lenksäule (wird auch von IVB verwendet)
            signal BCM_RACE_Mode_aktiv_XIX_SPRe_01_XIX_E3V_SAM_LIN4: start 39, 1 bit, little-endian, data-type-policy=OVERRIDE, i-signal-type=PRIMITIVE, init-value=0, base-type=BT_BCM_RACE_Mode_aktiv, compu {0=Cx0_inaktiv (CM_BCM_RACE_Mode_aktiv_Cx0_inaktiv), 1=Cx1_aktiv (CM_BCM_RACE_Mode_aktiv_Cx1_aktiv)}, range raw 0..1, transfer-property=PENDING  # Race-Modus aktiviert
            signal Schluesselnr_Personalisierung_XIX_SPRe_01_XIX_E3V_SAM_LIN4: start 40, 4 bit, little-endian, data-type-policy=OVERRIDE, i-signal-type=PRIMITIVE, init-value=14, base-type=BT_Schluesselnr_Personalisierung, invalid-value=Invalid_Schluesselnr_Personalisierung_XIX_SPRe_01_XIX_E3V_SAM_LIN4:15, compu {1=Cx1_Schluesselnummer_eins_aktiv (CM_Schluesselnr_Personalisierung_Cx1_Schluesselnummer_eins_aktiv), 2=Cx2_Schluesselnummer_zwei_aktiv (CM_Schluesselnr_Personalisierung_Cx2_Schluesselnummer_zwei_aktiv), 3=Cx3_Schluesselnummer_drei_aktiv (CM_Schluesselnr_Personalisierung_Cx3_Schluesselnummer_drei_aktiv), 4=Cx4_Schluesselnummer_vier_aktiv (CM_Schluesselnr_Personalisierung_Cx4_Schluesselnummer_vier_aktiv), 5=Cx5_Schluesselnummer_fuenf_aktiv (CM_Schluesselnr_Personalisierung_Cx5_Schluesselnummer_fuenf_aktiv), 6=Cx6_Schluesselnummer_sechs_aktiv (CM_Schluesselnr_Personalisierung_Cx6_Schluesselnummer_sechs_aktiv), 7=Cx7_Schluesselnummer_sieben_aktiv (CM_Schluesselnr_Personalisierung_Cx7_Schluesselnummer_sieben_aktiv), 8=Cx8_Schluesselnummer_acht_aktiv (CM_Schluesselnr_Personalisierung_Cx8_Schluesselnummer_acht_aktiv), 14=Cxe_Init (CM_Schluesselnr_Personalisierung_Cxe_Init), 15=Cxf_Fehler (CM_Schluesselnr_Personalisierung_Cxf_Fehler)}, range raw 1..15, transfer-property=PENDING  # Signal gibt die jewels aktuelle Schlüsselnummer für die Personalisierung wieder
            signal SPR_Abschaltstufe_XIX_SPRe_01_XIX_E3V_SAM_LIN4: start 44, 3 bit, little-endian, data-type-policy=OVERRIDE, i-signal-type=PRIMITIVE, init-value=0, base-type=BT_SPR_Abschaltstufe, compu {0=Cx0_Stufe_0_keine_Einschraenkung (CM_SPR_Abschaltstufe_Cx0_Stufe_0_keine_Einschraenkung), 1=Cx1_Stufe_1 (CM_SPR_Abschaltstufe_Cx1_Stufe_1), 2=Cx2_Stufe_2 (CM_SPR_Abschaltstufe_Cx2_Stufe_2), 3=Cx3_Stufe_3 (CM_SPR_Abschaltstufe_Cx3_Stufe_3), 4=Cx4_Transportmodus (CM_SPR_Abschaltstufe_Cx4_Transportmodus), 7=Cx7_Ruhestrommessmodus (CM_SPR_Abschaltstufe_Cx7_Ruhestrommessmodus)}, range raw 0..7, transfer-property=PENDING  # Stufe 0 (keine Einschraenkungen) Stufe 1 Stufe 2 Stufe 3 Für den Transport- und Ruhestrommessmodus sind die Werte aus der Systeminfo-Botschaft zu verwenden.
            signal ZV_verriegelt_extern_soll_XIX_SPRe_01_XIX_E3V_SAM_LIN4: start 47, 1 bit, little-endian, data-type-policy=OVERRIDE, i-signal-type=PRIMITIVE, init-value=0, base-type=BT_ZV_verriegelt_extern_soll, compu {1=Cx1_Fahrzeug_verriegelt_extern_Sollzusstand (CM_ZV_verriegelt_extern_soll_Cx1_Fahrzeug_verriegelt_extern_Sollzusstand) (Fahrzeug verriegelt extern; Sollzusstand)}, range raw 1, transfer-property=PENDING  # Sollzustand: Verriegelung Fahrzeug aussen
            signal ZAS_Kl_15_XIX_SPRe_01_XIX_E3V_SAM_LIN4: start 48, 1 bit, little-endian, data-type-policy=OVERRIDE, i-signal-type=PRIMITIVE, init-value=0, base-type=BT_ZAS_Kl_15, compu {0=Cx0_aus (CM_ZAS_Kl_15_Cx0_aus), 1=Cx1_ein (CM_ZAS_Kl_15_Cx1_ein)}, range raw 0..1, transfer-property=PENDING  # Klemme 15: Zuendung (SW-Kl.15)
            signal ZAS_Kl_S_XIX_SPRe_01_XIX_E3V_SAM_LIN4: start 49, 1 bit, little-endian, data-type-policy=OVERRIDE, i-signal-type=PRIMITIVE, init-value=0, base-type=BT_ZAS_Kl_S, compu {0=Cx0_aus (CM_ZAS_Kl_S_Cx0_aus), 1=Cx1_S_Kontakt_ein (CM_ZAS_Kl_S_Cx1_S_Kontakt_ein)}, range raw 0..1, transfer-property=PENDING  # Klemme S: S-Kontakt (Schluessel steckt)
            signal ZAS_Kl_X_XIX_SPRe_01_XIX_E3V_SAM_LIN4: start 50, 1 bit, little-endian, data-type-policy=OVERRIDE, i-signal-type=PRIMITIVE, init-value=0, base-type=BT_ZAS_Kl_X, compu {0=Cx0_aus (CM_ZAS_Kl_X_Cx0_aus), 1=Cx1_ein (CM_ZAS_Kl_X_Cx1_ein)}, range raw 0..1, transfer-property=PENDING  # Klemme 75
            signal BCM_FS_PreCrash_XIX_SPRe_01_XIX_E3V_SAM_LIN4: start 51, 1 bit, little-endian, data-type-policy=OVERRIDE, i-signal-type=PRIMITIVE, base-type=BT_BCM_FS_PreCrash, compu {0=Cx0_inaktiv (CM_BCM_FS_PreCrash_Cx0_inaktiv), 1=Cx1_aktiv (CM_BCM_FS_PreCrash_Cx1_aktiv)}, range raw 0..1, transfer-property=PENDING  # Crash Vorwarnung an den SPR FS auf LIN
            signal BCM_BFS_PreCrash_XIX_SPRe_01_XIX_E3V_SAM_LIN4: start 52, 1 bit, little-endian, data-type-policy=OVERRIDE, i-signal-type=PRIMITIVE, base-type=BT_BCM_BFS_PreCrash, compu {0=Cx0_inaktiv (CM_BCM_BFS_PreCrash_Cx0_inaktiv), 1=Cx1_aktiv (CM_BCM_BFS_PreCrash_Cx1_aktiv)}, range raw 0..1, transfer-property=PENDING  # Crash Vorwarnung an den SPR BFS auf LIN
            signal BCM_SPR_Nachregelung_Freigabe_XIX_SPRe_01_XIX_E3V_SAM_LIN4: start 53, 1 bit, little-endian, data-type-policy=OVERRIDE, i-signal-type=PRIMITIVE, init-value=1, base-type=BT_BCM_SPR_Nachregelung_Freigabe, compu {0=Cx0_Nachregelung_gesperrt (CM_BCM_SPR_Nachregelung_Freigabe_Cx0_Nachregelung_gesperrt), 1=Cx1_Nachregelung_freigegeben (CM_BCM_SPR_Nachregelung_Freigabe_Cx1_Nachregelung_freigegeben)}, range raw 0..1, transfer-property=PENDING  # Freigabesignal für den Sitzpneumatikregler zur Nachregelung der Drücke ab einer bestimmten Geschwindigkeitsschwelle (Akkustikverbesserung im Stand/bei sehr niedrigen Geschwindigkeiten). Über 10km/h darf erst eine Regelung erfolgen.
            signal BCM_FS_Lordose_ab_XIX_SPRe_01_XIX_E3V_SAM_LIN4: start 54, 1 bit, little-endian, data-type-policy=OVERRIDE, i-signal-type=PRIMITIVE, init-value=0, base-type=BT_BCM_FS_Lordose_ab, compu {0=Cx0_inaktiv (CM_BCM_FS_Lordose_ab_Cx0_inaktiv), 1=Cx1_aktiv (CM_BCM_FS_Lordose_ab_Cx1_aktiv)}, range raw 0..1, transfer-property=PENDING  # MMI Touch-Bedienung FS Lordose ab
            signal BCM_FS_Lordose_auf_XIX_SPRe_01_XIX_E3V_SAM_LIN4: start 55, 1 bit, little-endian, data-type-policy=OVERRIDE, i-signal-type=PRIMITIVE, init-value=0, base-type=BT_BCM_FS_Lordose_auf, compu {0=Cx0_inaktiv (CM_BCM_FS_Lordose_auf_Cx0_inaktiv), 1=Cx1_aktiv (CM_BCM_FS_Lordose_auf_Cx1_aktiv)}, range raw 0..1, transfer-property=PENDING  # MMI Touch-Bedienung FS Lordose auf
            signal BCM_FS_Lordose_vor_XIX_SPRe_01_XIX_E3V_SAM_LIN4: start 56, 1 bit, little-endian, data-type-policy=OVERRIDE, i-signal-type=PRIMITIVE, init-value=0, base-type=BT_BCM_FS_Lordose_vor, compu {0=Cx0_inaktiv (CM_BCM_FS_Lordose_vor_Cx0_inaktiv), 1=Cx1_aktiv (CM_BCM_FS_Lordose_vor_Cx1_aktiv)}, range raw 0..1, transfer-property=PENDING  # MMI Touch-Bedienung FS Lordose vor
            signal BCM_FS_Lordose_zurueck_XIX_SPRe_01_XIX_E3V_SAM_LIN4: start 57, 1 bit, little-endian, data-type-policy=OVERRIDE, i-signal-type=PRIMITIVE, init-value=0, base-type=BT_BCM_FS_Lordose_zurueck, compu {0=Cx0_inaktiv (CM_BCM_FS_Lordose_zurueck_Cx0_inaktiv), 1=Cx1_aktiv (CM_BCM_FS_Lordose_zurueck_Cx1_aktiv)}, range raw 0..1, transfer-property=PENDING  # MMI Touch-Bedienung FS Lordose zurück
            signal BCM_FS_SW_eng_XIX_SPRe_01_XIX_E3V_SAM_LIN4: start 58, 1 bit, little-endian, data-type-policy=OVERRIDE, i-signal-type=PRIMITIVE, init-value=0, base-type=BT_BCM_FS_SW_eng, compu {0=Cx0_inaktiv (CM_BCM_FS_SW_eng_Cx0_inaktiv), 1=Cx1_aktiv (CM_BCM_FS_SW_eng_Cx1_aktiv)}, range raw 0..1, transfer-property=PENDING  # MMI Touch-Bedienung FS Seitenwangen eng
            signal BCM_FS_SW_weit_XIX_SPRe_01_XIX_E3V_SAM_LIN4: start 59, 1 bit, little-endian, data-type-policy=OVERRIDE, i-signal-type=PRIMITIVE, init-value=0, base-type=BT_BCM_FS_SW_weit, compu {0=Cx0_inaktiv (CM_BCM_FS_SW_weit_Cx0_inaktiv), 1=Cx1_aktiv (CM_BCM_FS_SW_weit_Cx1_aktiv)}, range raw 0..1, transfer-property=PENDING  # MMI Touch-Bedienung FS Seitenwangen weit
            signal BCM_BFS_MSG_Status_XIX_SPRe_01_XIX_E3V_SAM_LIN4: start 60, 1 bit, little-endian, data-type-policy=OVERRIDE, i-signal-type=PRIMITIVE, init-value=0, base-type=BT_BCM_BFS_MSG_Status, compu {0=Cx0_inaktiv (CM_BCM_BFS_MSG_Status_Cx0_inaktiv), 1=Cx1_aktiv (CM_BCM_BFS_MSG_Status_Cx1_aktiv)}, range raw 0..1, transfer-property=PENDING  # MMI Touch-Bedienung BFS Massagefunktion (Ein/Aus)
            signal BCM_FS_MSG_Status_XIX_SPRe_01_XIX_E3V_SAM_LIN4: start 61, 1 bit, little-endian, data-type-policy=OVERRIDE, i-signal-type=PRIMITIVE, init-value=0, base-type=BT_BCM_FS_MSG_Status, compu {0=Cx0_inaktiv (CM_BCM_FS_MSG_Status_Cx0_inaktiv), 1=Cx1_aktiv (CM_BCM_FS_MSG_Status_Cx1_aktiv)}, range raw 0..1, transfer-property=PENDING  # MMI Touch-Bedienung FS Massagefunktion (Ein/Aus)
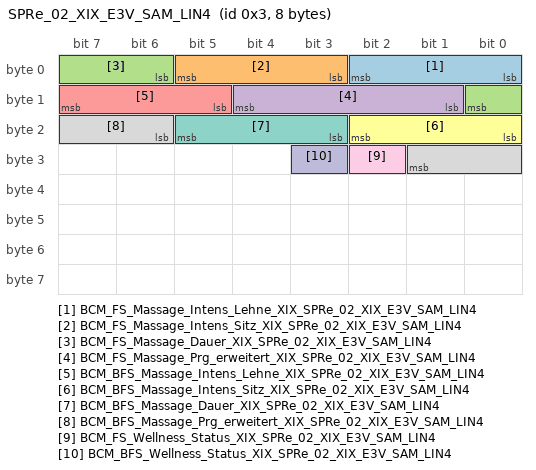
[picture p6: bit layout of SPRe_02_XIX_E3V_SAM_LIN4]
        frame SPRe_02_XIX_E3V_SAM_LIN4: id 0x3, from SAM, frame-length=8, lin-checksum=ENHANCED
          pdu SPRe_02_XIX_E3V_SAM_LIN4: length=8, unused-bit-pattern=0
            signal BCM_FS_Massage_Intens_Lehne_XIX_SPRe_02_XIX_E3V_SAM_LIN4: start 0, 3 bit, little-endian, data-type-policy=OVERRIDE, i-signal-type=PRIMITIVE, init-value=0, base-type=BT_BCM_FS_Massage_Intens_Lehne, compu {0=Cx0_Aus (CM_BCM_FS_Massage_Intens_Lehne_Cx0_Aus), 1=Cx1_Stufe_1 (CM_BCM_FS_Massage_Intens_Lehne_Cx1_Stufe_1), 2=Cx2_Stufe_2 (CM_BCM_FS_Massage_Intens_Lehne_Cx2_Stufe_2), 3=Cx3_Stufe_3 (CM_BCM_FS_Massage_Intens_Lehne_Cx3_Stufe_3), 4=Cx4_Stufe_4 (CM_BCM_FS_Massage_Intens_Lehne_Cx4_Stufe_4), 5=Cx5_Stufe_5 (CM_BCM_FS_Massage_Intens_Lehne_Cx5_Stufe_5), 6=Cx6_reserve (CM_BCM_FS_Massage_Intens_Lehne_Cx6_reserve), 7=Cx7_reserve (CM_BCM_FS_Massage_Intens_Lehne_Cx7_reserve)}, range raw 0..7, transfer-property=PENDING  # Info Massage Intensität Sitzlehne
            signal BCM_FS_Massage_Intens_Sitz_XIX_SPRe_02_XIX_E3V_SAM_LIN4: start 3, 3 bit, little-endian, data-type-policy=OVERRIDE, i-signal-type=PRIMITIVE, init-value=0, base-type=BT_BCM_FS_Massage_Intens_Sitz, compu {0=Cx0_Aus (CM_BCM_FS_Massage_Intens_Sitz_Cx0_Aus), 1=Cx1_Stufe_1 (CM_BCM_FS_Massage_Intens_Sitz_Cx1_Stufe_1), 2=Cx2_Stufe_2 (CM_BCM_FS_Massage_Intens_Sitz_Cx2_Stufe_2), 3=Cx3_Stufe_3 (CM_BCM_FS_Massage_Intens_Sitz_Cx3_Stufe_3), 4=Cx4_Stufe_4 (CM_BCM_FS_Massage_Intens_Sitz_Cx4_Stufe_4), 5=Cx5_Stufe_5 (CM_BCM_FS_Massage_Intens_Sitz_Cx5_Stufe_5), 6=Cx6_reserve (CM_BCM_FS_Massage_Intens_Sitz_Cx6_reserve), 7=Cx7_reserve (CM_BCM_FS_Massage_Intens_Sitz_Cx7_reserve)}, range raw 0..7, transfer-property=PENDING  # Info Massage Intensität Sitzkissen
            signal BCM_FS_Massage_Dauer_XIX_SPRe_02_XIX_E3V_SAM_LIN4: start 6, 3 bit, little-endian, data-type-policy=OVERRIDE, i-signal-type=PRIMITIVE, init-value=0, base-type=BT_BCM_FS_Massage_Dauer, compu {0=Cx0_Aus (CM_BCM_FS_Massage_Dauer_Cx0_Aus), 1=Cx1_Dauer_1 (CM_BCM_FS_Massage_Dauer_Cx1_Dauer_1), 2=Cx2_Dauer_2 (CM_BCM_FS_Massage_Dauer_Cx2_Dauer_2), 3=Cx3_Dauer_3 (CM_BCM_FS_Massage_Dauer_Cx3_Dauer_3), 4=Cx4_Dauer_4 (CM_BCM_FS_Massage_Dauer_Cx4_Dauer_4), 5=Cx5_Dauer_5 (CM_BCM_FS_Massage_Dauer_Cx5_Dauer_5), 6=Cx6_reserve (CM_BCM_FS_Massage_Dauer_Cx6_reserve), 7=Cx7_reserve (CM_BCM_FS_Massage_Dauer_Cx7_reserve)}, range raw 0..7, transfer-property=PENDING  # Info Massage Dauer
            signal BCM_FS_Massage_Prg_erweitert_XIX_SPRe_02_XIX_E3V_SAM_LIN4: start 9, 4 bit, little-endian, data-type-policy=OVERRIDE, i-signal-type=PRIMITIVE, init-value=0, base-type=BT_BCM_FS_Massage_Prg_erweitert, compu {0=Cx0_Aus (CM_BCM_FS_Massage_Prg_erweitert_Cx0_Aus), 1=Cx1_Programm_1 (CM_BCM_FS_Massage_Prg_erweitert_Cx1_Programm_1), 2=Cx2_Programm_2 (CM_BCM_FS_Massage_Prg_erweitert_Cx2_Programm_2), 3=Cx3_Programm_3 (CM_BCM_FS_Massage_Prg_erweitert_Cx3_Programm_3), 4=Cx4_Programm_4 (CM_BCM_FS_Massage_Prg_erweitert_Cx4_Programm_4), 5=Cx5_Programm_5 (CM_BCM_FS_Massage_Prg_erweitert_Cx5_Programm_5), 6=Cx6_Programm_6 (CM_BCM_FS_Massage_Prg_erweitert_Cx6_Programm_6), 7=Cx7_Programm_7 (CM_BCM_FS_Massage_Prg_erweitert_Cx7_Programm_7), 8=Cx8_Programm_8 (CM_BCM_FS_Massage_Prg_erweitert_Cx8_Programm_8), 9=Cx9_Programm_9 (CM_BCM_FS_Massage_Prg_erweitert_Cx9_Programm_9), 10=Cxa_Programm_10 (CM_BCM_FS_Massage_Prg_erweitert_Cxa_Programm_10), 11=Cxb_Programm_11 (CM_BCM_FS_Massage_Prg_erweitert_Cxb_Programm_11), 12=Cxc_Programm_12 (CM_BCM_FS_Massage_Prg_erweitert_Cxc_Programm_12), 13=Cxd_Programm_13 (CM_BCM_FS_Massage_Prg_erweitert_Cxd_Programm_13), 14=Cxe_Programm_14 (CM_BCM_FS_Massage_Prg_erweitert_Cxe_Programm_14), 15=Cxf_Programm_15 (CM_BCM_FS_Massage_Prg_erweitert_Cxf_Programm_15)}, range raw 0..15, transfer-property=PENDING  # Info Massage Programm erweitert
            signal BCM_BFS_Massage_Intens_Lehne_XIX_SPRe_02_XIX_E3V_SAM_LIN4: start 13, 3 bit, little-endian, data-type-policy=OVERRIDE, i-signal-type=PRIMITIVE, init-value=0, base-type=BT_BCM_BFS_Massage_Intens_Lehne, compu {0=Cx0_Aus (CM_BCM_BFS_Massage_Intens_Lehne_Cx0_Aus), 1=Cx1_Stufe_1 (CM_BCM_BFS_Massage_Intens_Lehne_Cx1_Stufe_1), 2=Cx2_Stufe_2 (CM_BCM_BFS_Massage_Intens_Lehne_Cx2_Stufe_2), 3=Cx3_Stufe_3 (CM_BCM_BFS_Massage_Intens_Lehne_Cx3_Stufe_3), 4=Cx4_Stufe_4 (CM_BCM_BFS_Massage_Intens_Lehne_Cx4_Stufe_4), 5=Cx5_Stufe_5 (CM_BCM_BFS_Massage_Intens_Lehne_Cx5_Stufe_5), 6=Cx6_reserve (CM_BCM_BFS_Massage_Intens_Lehne_Cx6_reserve), 7=Cx7_reserve (CM_BCM_BFS_Massage_Intens_Lehne_Cx7_reserve)}, range raw 0..7, transfer-property=PENDING  # Info Massage Intensität Sitzlehne
            signal BCM_BFS_Massage_Intens_Sitz_XIX_SPRe_02_XIX_E3V_SAM_LIN4: start 16, 3 bit, little-endian, data-type-policy=OVERRIDE, i-signal-type=PRIMITIVE, init-value=0, base-type=BT_BCM_BFS_Massage_Intens_Sitz, compu {0=Cx0_Aus (CM_BCM_BFS_Massage_Intens_Sitz_Cx0_Aus), 1=Cx1_Stufe_1 (CM_BCM_BFS_Massage_Intens_Sitz_Cx1_Stufe_1), 2=Cx2_Stufe_2 (CM_BCM_BFS_Massage_Intens_Sitz_Cx2_Stufe_2), 3=Cx3_Stufe_3 (CM_BCM_BFS_Massage_Intens_Sitz_Cx3_Stufe_3), 4=Cx4_Stufe_4 (CM_BCM_BFS_Massage_Intens_Sitz_Cx4_Stufe_4), 5=Cx5_Stufe_5 (CM_BCM_BFS_Massage_Intens_Sitz_Cx5_Stufe_5), 6=Cx6_reserve (CM_BCM_BFS_Massage_Intens_Sitz_Cx6_reserve), 7=Cx7_reserve (CM_BCM_BFS_Massage_Intens_Sitz_Cx7_reserve)}, range raw 0..7, transfer-property=PENDING  # Info Massage Intensität Sitzkissen
            signal BCM_BFS_Massage_Dauer_XIX_SPRe_02_XIX_E3V_SAM_LIN4: start 19, 3 bit, little-endian, data-type-policy=OVERRIDE, i-signal-type=PRIMITIVE, init-value=0, base-type=BT_BCM_BFS_Massage_Dauer, compu {0=Cx0_Aus (CM_BCM_BFS_Massage_Dauer_Cx0_Aus), 1=Cx1_Dauer_1 (CM_BCM_BFS_Massage_Dauer_Cx1_Dauer_1), 2=Cx2_Dauer_2 (CM_BCM_BFS_Massage_Dauer_Cx2_Dauer_2), 3=Cx3_Dauer_3 (CM_BCM_BFS_Massage_Dauer_Cx3_Dauer_3), 4=Cx4_Dauer_4 (CM_BCM_BFS_Massage_Dauer_Cx4_Dauer_4), 5=Cx5_Dauer_5 (CM_BCM_BFS_Massage_Dauer_Cx5_Dauer_5), 6=Cx6_reserve (CM_BCM_BFS_Massage_Dauer_Cx6_reserve), 7=Cx7_reserve (CM_BCM_BFS_Massage_Dauer_Cx7_reserve)}, range raw 0..7, transfer-property=PENDING  # Info Massage Dauer
            signal BCM_BFS_Massage_Prg_erweitert_XIX_SPRe_02_XIX_E3V_SAM_LIN4: start 22, 4 bit, little-endian, data-type-policy=OVERRIDE, i-signal-type=PRIMITIVE, init-value=0, base-type=BT_BCM_BFS_Massage_Prg_erweitert, compu {0=Cx0_Aus (CM_BCM_BFS_Massage_Prg_erweitert_Cx0_Aus), 1=Cx1_Programm_1 (CM_BCM_BFS_Massage_Prg_erweitert_Cx1_Programm_1), 2=Cx2_Programm_2 (CM_BCM_BFS_Massage_Prg_erweitert_Cx2_Programm_2), 3=Cx3_Programm_3 (CM_BCM_BFS_Massage_Prg_erweitert_Cx3_Programm_3), 4=Cx4_Programm_4 (CM_BCM_BFS_Massage_Prg_erweitert_Cx4_Programm_4), 5=Cx5_Programm_5 (CM_BCM_BFS_Massage_Prg_erweitert_Cx5_Programm_5), 6=Cx6_Programm_6 (CM_BCM_BFS_Massage_Prg_erweitert_Cx6_Programm_6), 7=Cx7_Programm_7 (CM_BCM_BFS_Massage_Prg_erweitert_Cx7_Programm_7), 8=Cx8_Programm_8 (CM_BCM_BFS_Massage_Prg_erweitert_Cx8_Programm_8), 9=Cx9_Programm_9 (CM_BCM_BFS_Massage_Prg_erweitert_Cx9_Programm_9), 10=Cxa_Programm_10 (CM_BCM_BFS_Massage_Prg_erweitert_Cxa_Programm_10), 11=Cxb_Programm_11 (CM_BCM_BFS_Massage_Prg_erweitert_Cxb_Programm_11), 12=Cxc_Programm_12 (CM_BCM_BFS_Massage_Prg_erweitert_Cxc_Programm_12), 13=Cxd_Programm_13 (CM_BCM_BFS_Massage_Prg_erweitert_Cxd_Programm_13), 14=Cxe_Programm_14 (CM_BCM_BFS_Massage_Prg_erweitert_Cxe_Programm_14), 15=Cxf_Programm_15 (CM_BCM_BFS_Massage_Prg_erweitert_Cxf_Programm_15)}, range raw 0..15, transfer-property=PENDING  # Info Massage Programm erweitert
            signal BCM_FS_Wellness_Status_XIX_SPRe_02_XIX_E3V_SAM_LIN4: start 26, 1 bit, little-endian, data-type-policy=OVERRIDE, i-signal-type=PRIMITIVE, init-value=0, base-type=BT_BCM_FS_Wellness_Status, compu {0=Cx0_inaktiv (CM_BCM_FS_Wellness_Status_Cx0_inaktiv), 1=Cx1_aktiv (CM_BCM_FS_Wellness_Status_Cx1_aktiv)}, range raw 0..1, transfer-property=PENDING  # Info Wellness Status
            signal BCM_BFS_Wellness_Status_XIX_SPRe_02_XIX_E3V_SAM_LIN4: start 27, 1 bit, little-endian, data-type-policy=OVERRIDE, i-signal-type=PRIMITIVE, init-value=0, base-type=BT_BCM_BFS_Wellness_Status, compu {0=Cx0_inaktiv (CM_BCM_BFS_Wellness_Status_Cx0_inaktiv), 1=Cx1_aktiv (CM_BCM_BFS_Wellness_Status_Cx1_aktiv)}, range raw 0..1, transfer-property=PENDING  # Info Wellness Status
        frame SPRs_BFS_01_XIX_E3V_SAM_LIN4: id 0x2C, to SAM, frame-length=6, lin-checksum=ENHANCED
          pdu SPRs_BFS_01_XIX_E3V_SAM_LIN4: length=6, unused-bit-pattern=0
            signal SPR_BFS_CodierPinError_XIX_SPRs_BFS_01_XIX_E3V_SAM_LIN4: start 0, 1 bit, little-endian, data-type-policy=OVERRIDE, i-signal-type=PRIMITIVE, init-value=0, base-type=BT_SPR_BFS_CodierPinError, invalid-value=Invalid_SPR_BFS_CodierPinError_XIX_SPRs_BFS_01_XIX_E3V_SAM_LIN4:1, compu {0=Cx0_kein_Fehler (CM_SPR_BFS_CodierPinError_Cx0_kein_Fehler), 1=Cx1_Fehler (CM_SPR_BFS_CodierPinError_Cx1_Fehler)}, range raw 0..1, transfer-property=PENDING, to SAM(timeout 3.5 s)  # Inkonsistenz der HW-Codierpins zum EEPROM-Eintrag.
            signal SPR_BFS_Kompressor_elFehler_XIX_SPRs_BFS_01_XIX_E3V_SAM_LIN4: start 1, 1 bit, little-endian, data-type-policy=OVERRIDE, i-signal-type=PRIMITIVE, init-value=0, base-type=BT_SPR_BFS_Kompressor_elFehler, invalid-value=Invalid_SPR_BFS_Kompressor_elFehler_XIX_SPRs_BFS_01_XIX_E3V_SAM_LIN4:1, compu {0=Cx0_kein_Fehler (CM_SPR_BFS_Kompressor_elFehler_Cx0_kein_Fehler), 1=Cx1_Fehler (CM_SPR_BFS_Kompressor_elFehler_Cx1_Fehler)}, range raw 0..1, transfer-property=PENDING, to SAM(timeout 3.5 s)  # elektrischer Fehler im Kompressor oder Kabelbaum
            signal SPR_BFS_Verstellung_aktiv_XIX_SPRs_BFS_01_XIX_E3V_SAM_LIN4: start 2, 1 bit, little-endian, data-type-policy=OVERRIDE, i-signal-type=PRIMITIVE, init-value=0, base-type=BT_SPR_BFS_Verstellung_aktiv, compu {0=Cx0_Aus (CM_SPR_BFS_Verstellung_aktiv_Cx0_Aus), 1=Cx1_Ein (CM_SPR_BFS_Verstellung_aktiv_Cx1_Ein)}, range raw 0..1, transfer-property=PENDING, to SAM(timeout 3.5 s)  # Version erstellt durch Datenimport.
            signal SPR_BFS_MuFu_Fkt_vor_XIX_SPRs_BFS_01_XIX_E3V_SAM_LIN4: start 3, 1 bit, little-endian, data-type-policy=OVERRIDE, i-signal-type=PRIMITIVE, init-value=0, base-type=BT_SPR_BFS_MuFu_Fkt_vor, compu {0=Cx0_inaktiv (CM_SPR_BFS_MuFu_Fkt_vor_Cx0_inaktiv), 1=Cx1_aktiv (CM_SPR_BFS_MuFu_Fkt_vor_Cx1_aktiv)}, range raw 0..1, transfer-property=PENDING, to SAM(timeout 3.5 s)  # Menueauswahl inkrementieren
            signal SPR_BFS_MuFu_Fkt_zurueck_XIX_SPRs_BFS_01_XIX_E3V_SAM_LIN4: start 4, 1 bit, little-endian, data-type-policy=OVERRIDE, i-signal-type=PRIMITIVE, init-value=0, base-type=BT_SPR_BFS_MuFu_Fkt_zurueck, compu {0=Cx0_inaktiv (CM_SPR_BFS_MuFu_Fkt_zurueck_Cx0_inaktiv), 1=Cx1_aktiv (CM_SPR_BFS_MuFu_Fkt_zurueck_Cx1_aktiv)}, range raw 0..1, transfer-property=PENDING, to SAM(timeout 3.5 s)  # Menueauswahl dekrementieren
            signal SPR_BFS_Systemtest_Status_XIX_SPRs_BFS_01_XIX_E3V_SAM_LIN4: start 6, 2 bit, little-endian, data-type-policy=OVERRIDE, i-signal-type=PRIMITIVE, init-value=0, base-type=BT_SPR_BFS_Systemtest_Status, invalid-value=Invalid_SPR_BFS_Systemtest_Status_XIX_SPRs_BFS_01_XIX_E3V_SAM_LIN4:3, compu {0=Cx0_Aus (CM_SPR_BFS_Systemtest_Status_Cx0_Aus), 1=Cx1_Aktiv (CM_SPR_BFS_Systemtest_Status_Cx1_Aktiv), 2=Cx2_Beendet (CM_SPR_BFS_Systemtest_Status_Cx2_Beendet), 3=Cx3_Fehler (CM_SPR_BFS_Systemtest_Status_Cx3_Fehler)}, range raw 0..3, transfer-property=PENDING, to SAM(timeout 3.5 s)  # Gibt den Status des Systemfunktionstest aus.
            signal SPR_BFS_Tasterfehler_Mufu_v_z_XIX_SPRs_BFS_01_XIX_E3V_SAM_LIN4: start 8, 1 bit, little-endian, data-type-policy=OVERRIDE, i-signal-type=PRIMITIVE, init-value=0, base-type=BT_SPR_BFS_Tasterfehler_Mufu_v_z, compu {0=Cx0_keine_Leckage (CM_SPR_BFS_Tasterfehler_Mufu_v_z_Cx0_keine_Leckage), 1=Cx1_Leckage_Lordosekissen_oben (CM_SPR_BFS_Tasterfehler_Mufu_v_z_Cx1_Leckage_Lordosekissen_oben)}, range raw 0..1, transfer-property=PENDING, to SAM(timeout 3.5 s)  # Tasterfehler im Mufu-Kanal vor/zurueck
            signal SPR_BFS_Tasterfehler_Mufu_auf_ab_XIX_SPRs_BFS_01_XIX_E3V_SAM_LIN4: start 12, 1 bit, little-endian, data-type-policy=OVERRIDE, i-signal-type=PRIMITIVE, init-value=0, base-type=BT_SPR_BFS_Tasterfehler_Mufu_auf_ab, compu {0=Cx0_keine_Leckage (CM_SPR_BFS_Tasterfehler_Mufu_auf_ab_Cx0_keine_Leckage), 1=Cx1_Leckage_Lordosekissen_oben (CM_SPR_BFS_Tasterfehler_Mufu_auf_ab_Cx1_Leckage_Lordosekissen_oben)}, range raw 0..1, transfer-property=PENDING, to SAM(timeout 3.5 s)  # Tasterfehler im Mufu-Kanal auf/ab
            signal SPR_BFS_Leck_erkannt_XIX_SPRs_BFS_01_XIX_E3V_SAM_LIN4: start 13, 1 bit, little-endian, data-type-policy=OVERRIDE, i-signal-type=PRIMITIVE, base-type=BT_SPR_BFS_Leck_erkannt, compu {0=Cx0_nicht_aktiv (CM_SPR_BFS_Leck_erkannt_Cx0_nicht_aktiv), 1=Cx1_aktiv (CM_SPR_BFS_Leck_erkannt_Cx1_aktiv)}, range raw 0..1, transfer-property=PENDING, to SAM(timeout 3.5 s)  # Leck im Kissen erkannt
            signal SPR_BFS_Tasterfehler_Massage_XIX_SPRs_BFS_01_XIX_E3V_SAM_LIN4: start 14, 1 bit, little-endian, data-type-policy=OVERRIDE, i-signal-type=PRIMITIVE, init-value=0, base-type=BT_SPR_BFS_Tasterfehler_Massage, compu {0=Cx0_keine_Leckage (CM_SPR_BFS_Tasterfehler_Massage_Cx0_keine_Leckage), 1=Cx1_Leckage_Lordosekissen_oben (CM_SPR_BFS_Tasterfehler_Massage_Cx1_Leckage_Lordosekissen_oben)}, range raw 0..1, transfer-property=PENDING, to SAM(timeout 3.5 s)  # Tasterfehler im Massagetaster
            signal SPR_BFS_Tasterfehler_Mufu_Ring_XIX_SPRs_BFS_01_XIX_E3V_SAM_LIN4: start 15, 1 bit, little-endian, data-type-policy=OVERRIDE, i-signal-type=PRIMITIVE, init-value=0, base-type=BT_SPR_BFS_Tasterfehler_Mufu_Ring, compu {0=Cx0_keine_Leckage (CM_SPR_BFS_Tasterfehler_Mufu_Ring_Cx0_keine_Leckage), 1=Cx1_Leckage_Lordosekissen_oben (CM_SPR_BFS_Tasterfehler_Mufu_Ring_Cx1_Leckage_Lordosekissen_oben)}, range raw 0..1, transfer-property=PENDING, to SAM(timeout 3.5 s)  # Tasterfehler im Mufu-Ring
            signal SPR_BFS_Massage_Int_XIX_SPRs_BFS_01_XIX_E3V_SAM_LIN4: start 16, 3 bit, little-endian, data-type-policy=OVERRIDE, i-signal-type=PRIMITIVE, init-value=0, base-type=BT_SPR_BFS_Massage_Int, compu {0=Cx0_Aus (CM_SPR_BFS_Massage_Int_Cx0_Aus), 1=Cx1_Stufe1 (CM_SPR_BFS_Massage_Int_Cx1_Stufe1), 2=Cx2_Stufe2 (CM_SPR_BFS_Massage_Int_Cx2_Stufe2), 3=Cx3_Stufe3 (CM_SPR_BFS_Massage_Int_Cx3_Stufe3), 4=Cx4_Stufe4 (CM_SPR_BFS_Massage_Int_Cx4_Stufe4), 5=Cx5_Stufe_5 (CM_SPR_BFS_Massage_Int_Cx5_Stufe_5)}, range raw 0..5, transfer-property=PENDING, to SAM(timeout 3.5 s)  # Das Signal gibt den zu visualisierenden Status für die Massage Intensitaet an die entsprechende ECU zurueck.
            signal SPR_BFS_Massage_Prg_XIX_SPRs_BFS_01_XIX_E3V_SAM_LIN4: start 19, 3 bit, little-endian, data-type-policy=OVERRIDE, i-signal-type=PRIMITIVE, init-value=0, base-type=BT_SPR_BFS_Massage_Prg, compu {0=Cx0_Aus (CM_SPR_BFS_Massage_Prg_Cx0_Aus), 1=Cx1_Programm1 (CM_SPR_BFS_Massage_Prg_Cx1_Programm1), 2=Cx2_Programm2 (CM_SPR_BFS_Massage_Prg_Cx2_Programm2), 3=Cx3_Programm3 (CM_SPR_BFS_Massage_Prg_Cx3_Programm3), 4=Cx4_Programm4 (CM_SPR_BFS_Massage_Prg_Cx4_Programm4), 5=Cx5_Programm5 (CM_SPR_BFS_Massage_Prg_Cx5_Programm5)}, range raw 0..5, transfer-property=PENDING, to SAM(timeout 3.5 s)  # Weiterleitung des gewünschten Massageprogramms
            signal SPR_BFS_Lordose_hoch_XIX_SPRs_BFS_01_XIX_E3V_SAM_LIN4: start 22, 1 bit, little-endian, data-type-policy=OVERRIDE, i-signal-type=PRIMITIVE, init-value=0, base-type=BT_SPR_BFS_Lordose_hoch, compu {0=Cx0_Aus (CM_SPR_BFS_Lordose_hoch_Cx0_Aus), 1=Cx1_Ein (CM_SPR_BFS_Lordose_hoch_Cx1_Ein)}, range raw 0..1, transfer-property=PENDING, to SAM(timeout 3.5 s)  # Anforderung Lordosewoelbung nach oben zu verschieben
            signal SPR_BFS_Lordose_runter_XIX_SPRs_BFS_01_XIX_E3V_SAM_LIN4: start 23, 1 bit, little-endian, data-type-policy=OVERRIDE, i-signal-type=PRIMITIVE, init-value=0, base-type=BT_SPR_BFS_Lordose_runter, compu {0=Cx0_Aus (CM_SPR_BFS_Lordose_runter_Cx0_Aus), 1=Cx1_Ein (CM_SPR_BFS_Lordose_runter_Cx1_Ein)}, range raw 0..1, transfer-property=PENDING, to SAM(timeout 3.5 s)  # Anforderung Lordosewoelbung nach unten zu verschieben
            signal SPR_BFS_Lordose_zurueck_XIX_SPRs_BFS_01_XIX_E3V_SAM_LIN4: start 24, 1 bit, little-endian, data-type-policy=OVERRIDE, i-signal-type=PRIMITIVE, init-value=0, base-type=BT_SPR_BFS_Lordose_zurueck, compu {0=Cx0_Aus (CM_SPR_BFS_Lordose_zurueck_Cx0_Aus), 1=Cx1_Ein (CM_SPR_BFS_Lordose_zurueck_Cx1_Ein)}, range raw 0..1, transfer-property=PENDING, to SAM(timeout 3.5 s)  # Anforderung Lordosenwoelbung zu verkleinern.
            signal SPR_BFS_Lordose_vor_XIX_SPRs_BFS_01_XIX_E3V_SAM_LIN4: start 25, 1 bit, little-endian, data-type-policy=OVERRIDE, i-signal-type=PRIMITIVE, init-value=0, base-type=BT_SPR_BFS_Lordose_vor, compu {0=Cx0_Aus (CM_SPR_BFS_Lordose_vor_Cx0_Aus), 1=Cx1_Ein (CM_SPR_BFS_Lordose_vor_Cx1_Ein)}, range raw 0..1, transfer-property=PENDING, to SAM(timeout 3.5 s)  # Anforderung Lordosenwoelbung pneumatisch zu vergrößern.
            signal SPR_BFS_SWL_zurueck_XIX_SPRs_BFS_01_XIX_E3V_SAM_LIN4: start 26, 1 bit, little-endian, data-type-policy=OVERRIDE, i-signal-type=PRIMITIVE, init-value=0, base-type=BT_SPR_BFS_SWL_zurueck, compu {0=Cx0_Aus (CM_SPR_BFS_SWL_zurueck_Cx0_Aus), 1=Cx1_Ein (CM_SPR_BFS_SWL_zurueck_Cx1_Ein)}, range raw 0..1, transfer-property=PENDING, to SAM(timeout 3.5 s)  # Anforderung Seitenwangen Lehne zu verkleinern.
            signal SPR_BFS_SWL_vor_XIX_SPRs_BFS_01_XIX_E3V_SAM_LIN4: start 27, 1 bit, little-endian, data-type-policy=OVERRIDE, i-signal-type=PRIMITIVE, init-value=0, base-type=BT_SPR_BFS_SWL_vor, compu {0=Cx0_Aus (CM_SPR_BFS_SWL_vor_Cx0_Aus), 1=Cx1_Ein (CM_SPR_BFS_SWL_vor_Cx1_Ein)}, range raw 0..1, transfer-property=PENDING, to SAM(timeout 3.5 s)  # Anforderung Seitenwangen Lehne zu vergrößern.
            signal SPR_BFS_Unterspannung_XIX_SPRs_BFS_01_XIX_E3V_SAM_LIN4: start 28, 1 bit, little-endian, data-type-policy=OVERRIDE, i-signal-type=PRIMITIVE, init-value=0, base-type=BT_SPR_BFS_Unterspannung, invalid-value=Invalid_SPR_BFS_Unterspannung_XIX_SPRs_BFS_01_XIX_E3V_SAM_LIN4:1, compu {0=Cx0_normal (CM_SPR_BFS_Unterspannung_Cx0_normal), 1=Cx1_Fehler (CM_SPR_BFS_Unterspannung_Cx1_Fehler)}, range raw 0..1, transfer-property=PENDING, to SAM(timeout 3.5 s)  # Je ein Nibble für Speicher-Lesen über LIN-Applikationsbotschaft
            signal SPR_BFS_Ueberspannung_XIX_SPRs_BFS_01_XIX_E3V_SAM_LIN4: start 29, 1 bit, little-endian, data-type-policy=OVERRIDE, i-signal-type=PRIMITIVE, init-value=0, base-type=BT_SPR_BFS_Ueberspannung, invalid-value=Invalid_SPR_BFS_Ueberspannung_XIX_SPRs_BFS_01_XIX_E3V_SAM_LIN4:1, compu {0=Cx0_normal (CM_SPR_BFS_Ueberspannung_Cx0_normal), 1=Cx1_Fehler (CM_SPR_BFS_Ueberspannung_Cx1_Fehler)}, range raw 0..1, transfer-property=PENDING, to SAM(timeout 3.5 s)  # Je ein Nibble für Speicher-Lesen über LIN-Applikationsbotschaft
            signal SPR_BFS_SG_defekt_XIX_SPRs_BFS_01_XIX_E3V_SAM_LIN4: start 30, 1 bit, little-endian, data-type-policy=OVERRIDE, i-signal-type=PRIMITIVE, init-value=0, base-type=BT_SPR_BFS_SG_defekt, invalid-value=Invalid_SPR_BFS_SG_defekt_XIX_SPRs_BFS_01_XIX_E3V_SAM_LIN4:1, compu {0=Cx0_normal (CM_SPR_BFS_SG_defekt_Cx0_normal), 1=Cx1_Fehler (CM_SPR_BFS_SG_defekt_Cx1_Fehler)}, range raw 0..1, transfer-property=PENDING, to SAM(timeout 3.5 s)  # Je ein Nibble für Speicher-Lesen über LIN-Applikationsbotschaft
            signal SPR_BFS_Lokal_aktiv_XIX_SPRs_BFS_01_XIX_E3V_SAM_LIN4: start 31, 1 bit, little-endian, data-type-policy=OVERRIDE, i-signal-type=PRIMITIVE, init-value=0, base-type=BT_SPR_BFS_Lokal_aktiv, compu {0=Cx0_war_nicht_lokal_aktiv (CM_SPR_BFS_Lokal_aktiv_Cx0_war_nicht_lokal_aktiv), 1=Cx1_war_lokal_aktiv (CM_SPR_BFS_Lokal_aktiv_Cx1_war_lokal_aktiv)}, range raw 0..1, transfer-property=PENDING, to SAM(timeout 3.5 s)  # Steuergerät war lokal aktiv
            signal SPR_BFS_ResponseError_XIX_SPRs_BFS_01_XIX_E3V_SAM_LIN4: start 32, 1 bit, little-endian, data-type-policy=OVERRIDE, i-signal-type=PRIMITIVE, init-value=0, base-type=BT_SPR_BFS_ResponseError, invalid-value=Invalid_SPR_BFS_ResponseError_XIX_SPRs_BFS_01_XIX_E3V_SAM_LIN4:1, compu {0=Cx0_normal (CM_SPR_BFS_ResponseError_Cx0_normal), 1=Cx1_Fehler (CM_SPR_BFS_ResponseError_Cx1_Fehler)}, range raw 0..1, transfer-property=PENDING, to SAM(timeout 3.5 s)  # siehe LIN2.0-Specification (Darf nicht über ein Fehlergueltigkeitsbit abgesichtert werden!)
            signal SPR_BFS_PopUp_Request_XIX_SPRs_BFS_01_XIX_E3V_SAM_LIN4: start 40, 1 bit, little-endian, data-type-policy=OVERRIDE, i-signal-type=PRIMITIVE, base-type=BT_SPR_BFS_PopUp_Request, compu {0=Cx0_keine_Anforderung (CM_SPR_BFS_PopUp_Request_Cx0_keine_Anforderung), 1=Cx1_Anforderung_MMI_Popup_Massage (CM_SPR_BFS_PopUp_Request_Cx1_Anforderung_MMI_Popup_Massage)}, range raw 0..1, transfer-property=PENDING, to SAM(timeout 3.5 s)  # Anforderung MMI Popup für Massage
            signal SPR_BFS_Massagetaster_inv_XIX_SPRs_BFS_01_XIX_E3V_SAM_LIN4: start 41, 1 bit, little-endian, data-type-policy=OVERRIDE, i-signal-type=PRIMITIVE, init-value=1, base-type=BT_SPR_BFS_Massagetaster_inv, compu {0=Cx0_betaetigt (CM_SPR_BFS_Massagetaster_inv_Cx0_betaetigt), 1=Cx1_unbetaetigt (CM_SPR_BFS_Massagetaster_inv_Cx1_unbetaetigt)}, range raw 0..1, transfer-property=PENDING, to SAM(timeout 3.5 s)  # Signal für Panikabbruch bei Automatikfahrten des Sitzes und der Pneumatikkomponenten mit Memory. Signal invertiert für Rückwärtskompatibilität.
            signal SPR_BFS_Teller_inv_XIX_SPRs_BFS_01_XIX_E3V_SAM_LIN4: start 42, 1 bit, little-endian, data-type-policy=OVERRIDE, i-signal-type=PRIMITIVE, init-value=1, base-type=BT_SPR_BFS_Teller_inv, compu {0=Cx0_betaetigt (CM_SPR_BFS_Teller_inv_Cx0_betaetigt), 1=Cx1_unbetaetigt (CM_SPR_BFS_Teller_inv_Cx1_unbetaetigt)}, range raw 0..1, transfer-property=PENDING, to SAM(timeout 3.5 s)  # Signal für Panikabbruch bei Automatikfahrten des Sitzes und der Pneumatikkomponenten mit Memory. Signal invertiert für Rückwärtskompatibilität.
            signal SPR_BFS_Wippe_inv_XIX_SPRs_BFS_01_XIX_E3V_SAM_LIN4: start 43, 1 bit, little-endian, data-type-policy=OVERRIDE, i-signal-type=PRIMITIVE, init-value=1, base-type=BT_SPR_BFS_Wippe_inv, compu {0=Cx0_betaetigt (CM_SPR_BFS_Wippe_inv_Cx0_betaetigt), 1=Cx1_unbetaetigt (CM_SPR_BFS_Wippe_inv_Cx1_unbetaetigt)}, range raw 0..1, transfer-property=PENDING, to SAM(timeout 3.5 s)  # Signal für Panikabbruch bei Automatikfahrten des Sitzes und der Pneumatikkomponenten mit Memory. Signal invertiert für Rückwärtskompatibilität.
            signal SPR_BFS_MassageStatus_XIX_SPRs_BFS_01_XIX_E3V_SAM_LIN4: start 44, 1 bit, little-endian, data-type-policy=OVERRIDE, i-signal-type=PRIMITIVE, init-value=0, base-type=BT_SPR_BFS_MassageStatus, compu {0=Cx0_Aus (CM_SPR_BFS_MassageStatus_Cx0_Aus), 1=Cx1_Ein (CM_SPR_BFS_MassageStatus_Cx1_Ein)}, range raw 0..1, transfer-property=PENDING, to SAM(timeout 3.5 s)  # MMI Touch-Bedienung BFS Massagefunktion (Ein/Aus)
            signal SPR_BFS_Wellness_Status_XIX_SPRs_BFS_01_XIX_E3V_SAM_LIN4: start 45, 1 bit, little-endian, data-type-policy=OVERRIDE, i-signal-type=PRIMITIVE, init-value=0, base-type=BT_SPR_BFS_Wellness_Status, compu {0=Cx0_inaktiv (CM_SPR_BFS_Wellness_Status_Cx0_inaktiv), 1=Cx1_aktiv (CM_SPR_BFS_Wellness_Status_Cx1_aktiv)}, range raw 0..1, transfer-property=PENDING, to SAM(timeout 3.5 s)  # Info Wellness Status
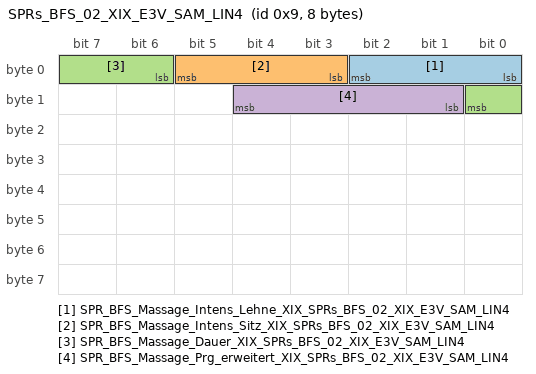
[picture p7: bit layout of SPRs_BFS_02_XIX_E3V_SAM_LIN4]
        frame SPRs_BFS_02_XIX_E3V_SAM_LIN4: id 0x9, to SAM, frame-length=8, lin-checksum=ENHANCED
          pdu SPRs_BFS_02_XIX_E3V_SAM_LIN4: length=8, unused-bit-pattern=0
            signal SPR_BFS_Massage_Intens_Lehne_XIX_SPRs_BFS_02_XIX_E3V_SAM_LIN4: start 0, 3 bit, little-endian, data-type-policy=OVERRIDE, i-signal-type=PRIMITIVE, init-value=0, base-type=BT_SPR_BFS_Massage_Intens_Lehne, compu {0=Cx0_Aus (CM_SPR_BFS_Massage_Intens_Lehne_Cx0_Aus), 1=Cx1_Stufe_1 (CM_SPR_BFS_Massage_Intens_Lehne_Cx1_Stufe_1), 2=Cx2_Stufe_2 (CM_SPR_BFS_Massage_Intens_Lehne_Cx2_Stufe_2), 3=Cx3_Stufe_3 (CM_SPR_BFS_Massage_Intens_Lehne_Cx3_Stufe_3), 4=Cx4_Stufe_4 (CM_SPR_BFS_Massage_Intens_Lehne_Cx4_Stufe_4), 5=Cx5_Stufe_5 (CM_SPR_BFS_Massage_Intens_Lehne_Cx5_Stufe_5), 6=Cx6_reserve (CM_SPR_BFS_Massage_Intens_Lehne_Cx6_reserve), 7=Cx7_reserve (CM_SPR_BFS_Massage_Intens_Lehne_Cx7_reserve)}, range raw 0..7, transfer-property=PENDING, to SAM(timeout 3.5 s)  # Info Massage Intensität Sitzlehne
            signal SPR_BFS_Massage_Intens_Sitz_XIX_SPRs_BFS_02_XIX_E3V_SAM_LIN4: start 3, 3 bit, little-endian, data-type-policy=OVERRIDE, i-signal-type=PRIMITIVE, init-value=0, base-type=BT_SPR_BFS_Massage_Intens_Sitz, compu {0=Cx0_Aus (CM_SPR_BFS_Massage_Intens_Sitz_Cx0_Aus), 1=Cx1_Stufe_1 (CM_SPR_BFS_Massage_Intens_Sitz_Cx1_Stufe_1), 2=Cx2_Stufe_2 (CM_SPR_BFS_Massage_Intens_Sitz_Cx2_Stufe_2), 3=Cx3_Stufe_3 (CM_SPR_BFS_Massage_Intens_Sitz_Cx3_Stufe_3), 4=Cx4_Stufe_4 (CM_SPR_BFS_Massage_Intens_Sitz_Cx4_Stufe_4), 5=Cx5_Stufe_5 (CM_SPR_BFS_Massage_Intens_Sitz_Cx5_Stufe_5), 6=Cx6_reserve (CM_SPR_BFS_Massage_Intens_Sitz_Cx6_reserve), 7=Cx7_reserve (CM_SPR_BFS_Massage_Intens_Sitz_Cx7_reserve)}, range raw 0..7, transfer-property=PENDING, to SAM(timeout 3.5 s)  # Info Massage Intensität Sitzkissen
            signal SPR_BFS_Massage_Dauer_XIX_SPRs_BFS_02_XIX_E3V_SAM_LIN4: start 6, 3 bit, little-endian, data-type-policy=OVERRIDE, i-signal-type=PRIMITIVE, init-value=0, base-type=BT_SPR_BFS_Massage_Dauer, compu {0=Cx0_Aus (CM_SPR_BFS_Massage_Dauer_Cx0_Aus), 1=Cx1_Dauer_1 (CM_SPR_BFS_Massage_Dauer_Cx1_Dauer_1), 2=Cx2_Dauer_2 (CM_SPR_BFS_Massage_Dauer_Cx2_Dauer_2), 3=Cx3_Dauer_3 (CM_SPR_BFS_Massage_Dauer_Cx3_Dauer_3), 4=Cx4_Dauer_4 (CM_SPR_BFS_Massage_Dauer_Cx4_Dauer_4), 5=Cx5_Dauer_5 (CM_SPR_BFS_Massage_Dauer_Cx5_Dauer_5), 6=Cx6_reserve (CM_SPR_BFS_Massage_Dauer_Cx6_reserve), 7=Cx7_reserve (CM_SPR_BFS_Massage_Dauer_Cx7_reserve)}, range raw 0..7, transfer-property=PENDING, to SAM(timeout 3.5 s)  # Info Massage Dauer
            signal SPR_BFS_Massage_Prg_erweitert_XIX_SPRs_BFS_02_XIX_E3V_SAM_LIN4: start 9, 4 bit, little-endian, data-type-policy=OVERRIDE, i-signal-type=PRIMITIVE, init-value=0, base-type=BT_SPR_BFS_Massage_Prg_erweitert, compu {0=Cx0_Aus (CM_SPR_BFS_Massage_Prg_erweitert_Cx0_Aus), 1=Cx1_Programm_1 (CM_SPR_BFS_Massage_Prg_erweitert_Cx1_Programm_1), 2=Cx2_Programm_2 (CM_SPR_BFS_Massage_Prg_erweitert_Cx2_Programm_2), 3=Cx3_Programm_3 (CM_SPR_BFS_Massage_Prg_erweitert_Cx3_Programm_3), 4=Cx4_Programm_4 (CM_SPR_BFS_Massage_Prg_erweitert_Cx4_Programm_4), 5=Cx5_Programm_5 (CM_SPR_BFS_Massage_Prg_erweitert_Cx5_Programm_5), 6=Cx6_Programm_6 (CM_SPR_BFS_Massage_Prg_erweitert_Cx6_Programm_6), 7=Cx7_Programm_7 (CM_SPR_BFS_Massage_Prg_erweitert_Cx7_Programm_7), 8=Cx8_Programm_8 (CM_SPR_BFS_Massage_Prg_erweitert_Cx8_Programm_8), 9=Cx9_Programm_9 (CM_SPR_BFS_Massage_Prg_erweitert_Cx9_Programm_9), 10=Cxa_Programm_10 (CM_SPR_BFS_Massage_Prg_erweitert_Cxa_Programm_10), 11=Cxb_Programm_11 (CM_SPR_BFS_Massage_Prg_erweitert_Cxb_Programm_11), 12=Cxc_Programm_12 (CM_SPR_BFS_Massage_Prg_erweitert_Cxc_Programm_12), 13=Cxd_Programm_13 (CM_SPR_BFS_Massage_Prg_erweitert_Cxd_Programm_13), 14=Cxe_Programm_14 (CM_SPR_BFS_Massage_Prg_erweitert_Cxe_Programm_14), 15=Cxf_Programm_15 (CM_SPR_BFS_Massage_Prg_erweitert_Cxf_Programm_15)}, range raw 0..15, transfer-property=PENDING, to SAM(timeout 3.5 s)  # Info Massage Programm erweitert
        frame SPRs_FS_01_XIX_E3V_SAM_LIN4: id 0x2B, to SAM, frame-length=6, lin-checksum=ENHANCED
          pdu SPRs_FS_01_XIX_E3V_SAM_LIN4: length=6, unused-bit-pattern=0
            signal SPR_FS_CodierPinError_XIX_SPRs_FS_01_XIX_E3V_SAM_LIN4: start 0, 1 bit, little-endian, data-type-policy=OVERRIDE, i-signal-type=PRIMITIVE, init-value=0, base-type=BT_SPR_FS_CodierPinError, invalid-value=Invalid_SPR_FS_CodierPinError_XIX_SPRs_FS_01_XIX_E3V_SAM_LIN4:1, compu {0=Cx0_kein_Fehler (CM_SPR_FS_CodierPinError_Cx0_kein_Fehler), 1=Cx1_Fehler (CM_SPR_FS_CodierPinError_Cx1_Fehler)}, range raw 0..1, transfer-property=PENDING, to SAM(timeout 3.5 s)  # Inkonsistenz der HW-Codierpins zum EEPROM-Eintrag.
            signal SPR_FS_Kompressor_elFehler_XIX_SPRs_FS_01_XIX_E3V_SAM_LIN4: start 1, 1 bit, little-endian, data-type-policy=OVERRIDE, i-signal-type=PRIMITIVE, init-value=0, base-type=BT_SPR_FS_Kompressor_elFehler, invalid-value=Invalid_SPR_FS_Kompressor_elFehler_XIX_SPRs_FS_01_XIX_E3V_SAM_LIN4:1, compu {0=Cx0_kein_Fehler (CM_SPR_FS_Kompressor_elFehler_Cx0_kein_Fehler), 1=Cx1_Fehler (CM_SPR_FS_Kompressor_elFehler_Cx1_Fehler)}, range raw 0..1, transfer-property=PENDING, to SAM(timeout 3.5 s)  # elektrischer Fehler im Kompressor oder Kabelbaum
            signal SPR_FS_Verstellung_aktiv_XIX_SPRs_FS_01_XIX_E3V_SAM_LIN4: start 2, 1 bit, little-endian, data-type-policy=OVERRIDE, i-signal-type=PRIMITIVE, init-value=0, base-type=BT_SPR_FS_Verstellung_aktiv, compu {0=Cx0_Aus (CM_SPR_FS_Verstellung_aktiv_Cx0_Aus), 1=Cx1_Ein (CM_SPR_FS_Verstellung_aktiv_Cx1_Ein)}, range raw 0..1, transfer-property=PENDING, to SAM(timeout 3.5 s)  # Version erstellt durch Datenimport.
            signal SPR_FS_MuFu_Fkt_vor_XIX_SPRs_FS_01_XIX_E3V_SAM_LIN4: start 3, 1 bit, little-endian, data-type-policy=OVERRIDE, i-signal-type=PRIMITIVE, init-value=0, base-type=BT_SPR_FS_MuFu_Fkt_vor, compu {0=Cx0_inaktiv (CM_SPR_FS_MuFu_Fkt_vor_Cx0_inaktiv), 1=Cx1_aktiv (CM_SPR_FS_MuFu_Fkt_vor_Cx1_aktiv)}, range raw 0..1, transfer-property=PENDING, to SAM(timeout 3.5 s)  # Menueauswahl inkrementieren
            signal SPR_FS_MuFu_Fkt_zurueck_XIX_SPRs_FS_01_XIX_E3V_SAM_LIN4: start 4, 1 bit, little-endian, data-type-policy=OVERRIDE, i-signal-type=PRIMITIVE, init-value=0, base-type=BT_SPR_FS_MuFu_Fkt_zurueck, compu {0=Cx0_inaktiv (CM_SPR_FS_MuFu_Fkt_zurueck_Cx0_inaktiv), 1=Cx1_aktiv (CM_SPR_FS_MuFu_Fkt_zurueck_Cx1_aktiv)}, range raw 0..1, transfer-property=PENDING, to SAM(timeout 3.5 s)  # Menueauswahl dekrementieren
            signal SPR_FS_Systemtest_Status_XIX_SPRs_FS_01_XIX_E3V_SAM_LIN4: start 6, 2 bit, little-endian, data-type-policy=OVERRIDE, i-signal-type=PRIMITIVE, init-value=0, base-type=BT_SPR_FS_Systemtest_Status, invalid-value=Invalid_SPR_FS_Systemtest_Status_XIX_SPRs_FS_01_XIX_E3V_SAM_LIN4:3, compu {0=Cx0_Aus (CM_SPR_FS_Systemtest_Status_Cx0_Aus), 1=Cx1_Aktiv (CM_SPR_FS_Systemtest_Status_Cx1_Aktiv), 2=Cx2_Beendet (CM_SPR_FS_Systemtest_Status_Cx2_Beendet), 3=Cx3_Fehler (CM_SPR_FS_Systemtest_Status_Cx3_Fehler)}, range raw 0..3, transfer-property=PENDING, to SAM(timeout 3.5 s)  # Gibt den Status des Systemfunktionstest aus.
            signal SPR_FS_Tasterfehler_Mufu_v_z_XIX_SPRs_FS_01_XIX_E3V_SAM_LIN4: start 8, 1 bit, little-endian, data-type-policy=OVERRIDE, i-signal-type=PRIMITIVE, base-type=BT_SPR_FS_Tasterfehler_Mufu_v_z, compu {0=Cx0_nicht_aktiv (CM_SPR_FS_Tasterfehler_Mufu_v_z_Cx0_nicht_aktiv), 1=Cx1_aktiv (CM_SPR_FS_Tasterfehler_Mufu_v_z_Cx1_aktiv)}, range raw 0..1, transfer-property=PENDING, to SAM(timeout 3.5 s)  # Tasterfehler am MuFu-Kanal vor/zurueck erkannt
            signal SPR_FS_Tasterfehler_Mufu_auf_ab_XIX_SPRs_FS_01_XIX_E3V_SAM_LIN4: start 12, 1 bit, little-endian, data-type-policy=OVERRIDE, i-signal-type=PRIMITIVE, base-type=BT_SPR_FS_Tasterfehler_Mufu_auf_ab, compu {0=Cx0_nicht_aktiv (CM_SPR_FS_Tasterfehler_Mufu_auf_ab_Cx0_nicht_aktiv), 1=Cx1_aktiv (CM_SPR_FS_Tasterfehler_Mufu_auf_ab_Cx1_aktiv)}, range raw 0..1, transfer-property=PENDING, to SAM(timeout 3.5 s)  # Tasterfehler am MuFu-Kanal auf/ab erkannt
            signal SPR_FS_Leck_erkannt_XIX_SPRs_FS_01_XIX_E3V_SAM_LIN4: start 13, 1 bit, little-endian, data-type-policy=OVERRIDE, i-signal-type=PRIMITIVE, base-type=BT_SPR_FS_Leck_erkannt, compu {0=Cx0_nicht_aktiv (CM_SPR_FS_Leck_erkannt_Cx0_nicht_aktiv), 1=Cx1_aktiv (CM_SPR_FS_Leck_erkannt_Cx1_aktiv)}, range raw 0..1, transfer-property=PENDING, to SAM(timeout 3.5 s)  # Leck im Kissen erkannt
            signal SPR_FS_Tasterfehler_Massage_XIX_SPRs_FS_01_XIX_E3V_SAM_LIN4: start 14, 1 bit, little-endian, data-type-policy=OVERRIDE, i-signal-type=PRIMITIVE, base-type=BT_SPR_FS_Tasterfehler_Massage, compu {0=Cx0_nicht_aktiv (CM_SPR_FS_Tasterfehler_Massage_Cx0_nicht_aktiv), 1=Cx1_aktiv (CM_SPR_FS_Tasterfehler_Massage_Cx1_aktiv)}, range raw 0..1, transfer-property=PENDING, to SAM(timeout 3.5 s)  # Tasterfehler am Massagetaster
            signal SPR_FS_Tasterfehler_Mufu_Ring_XIX_SPRs_FS_01_XIX_E3V_SAM_LIN4: start 15, 1 bit, little-endian, data-type-policy=OVERRIDE, i-signal-type=PRIMITIVE, base-type=BT_SPR_FS_Tasterfehler_Mufu_Ring, compu {0=Cx0_nicht_aktiv (CM_SPR_FS_Tasterfehler_Mufu_Ring_Cx0_nicht_aktiv), 1=Cx1_aktiv (CM_SPR_FS_Tasterfehler_Mufu_Ring_Cx1_aktiv)}, range raw 0..1, transfer-property=PENDING, to SAM(timeout 3.5 s)  # Tasterfehler am MuFu-Kanal Ring erkannt
            signal SPR_FS_Massage_Int_XIX_SPRs_FS_01_XIX_E3V_SAM_LIN4: start 16, 3 bit, little-endian, data-type-policy=OVERRIDE, i-signal-type=PRIMITIVE, init-value=0, base-type=BT_SPR_FS_Massage_Int, compu {0=Cx0_Aus (CM_SPR_FS_Massage_Int_Cx0_Aus), 1=Cx1_Stufe1 (CM_SPR_FS_Massage_Int_Cx1_Stufe1), 2=Cx2_Stufe2 (CM_SPR_FS_Massage_Int_Cx2_Stufe2), 3=Cx3_Stufe3 (CM_SPR_FS_Massage_Int_Cx3_Stufe3), 4=Cx4_Stufe4 (CM_SPR_FS_Massage_Int_Cx4_Stufe4), 5=Cx5_Stufe_5 (CM_SPR_FS_Massage_Int_Cx5_Stufe_5)}, range raw 0..5, transfer-property=PENDING, to SAM(timeout 3.5 s)  # Das Signal gibt den zu visualisierenden Status für die Massage Intensitaet an die entsprechende ECU zurueck.
            signal SPR_FS_Massage_Prg_XIX_SPRs_FS_01_XIX_E3V_SAM_LIN4: start 19, 3 bit, little-endian, data-type-policy=OVERRIDE, i-signal-type=PRIMITIVE, init-value=0, base-type=BT_SPR_FS_Massage_Prg, compu {0=Cx0_Aus (CM_SPR_FS_Massage_Prg_Cx0_Aus), 1=Cx1_Programm1 (CM_SPR_FS_Massage_Prg_Cx1_Programm1), 2=Cx2_Programm2 (CM_SPR_FS_Massage_Prg_Cx2_Programm2), 3=Cx3_Programm3 (CM_SPR_FS_Massage_Prg_Cx3_Programm3), 4=Cx4_Programm4 (CM_SPR_FS_Massage_Prg_Cx4_Programm4), 5=Cx5_Programm5 (CM_SPR_FS_Massage_Prg_Cx5_Programm5)}, range raw 0..5, transfer-property=PENDING, to SAM(timeout 3.5 s)  # Weiterleitung des gewünschten Massageprogramms
            signal SPR_FS_Lordose_hoch_XIX_SPRs_FS_01_XIX_E3V_SAM_LIN4: start 22, 1 bit, little-endian, data-type-policy=OVERRIDE, i-signal-type=PRIMITIVE, init-value=0, base-type=BT_SPR_FS_Lordose_hoch, compu {0=Cx0_Aus (CM_SPR_FS_Lordose_hoch_Cx0_Aus), 1=Cx1_Ein (CM_SPR_FS_Lordose_hoch_Cx1_Ein)}, range raw 0..1, transfer-property=PENDING, to SAM(timeout 3.5 s)  # Anforderung Lordosewoelbung nach oben zu verschieben
            signal SPR_FS_Lordose_runter_XIX_SPRs_FS_01_XIX_E3V_SAM_LIN4: start 23, 1 bit, little-endian, data-type-policy=OVERRIDE, i-signal-type=PRIMITIVE, init-value=0, base-type=BT_SPR_FS_Lordose_runter, compu {0=Cx0_Aus (CM_SPR_FS_Lordose_runter_Cx0_Aus), 1=Cx1_Ein (CM_SPR_FS_Lordose_runter_Cx1_Ein)}, range raw 0..1, transfer-property=PENDING, to SAM(timeout 3.5 s)  # Anforderung Lordosewoelbung nach unten zu verschieben
            signal SPR_FS_Lordose_zurueck_XIX_SPRs_FS_01_XIX_E3V_SAM_LIN4: start 24, 1 bit, little-endian, data-type-policy=OVERRIDE, i-signal-type=PRIMITIVE, init-value=0, base-type=BT_SPR_FS_Lordose_zurueck, compu {0=Cx0_Aus (CM_SPR_FS_Lordose_zurueck_Cx0_Aus), 1=Cx1_Ein (CM_SPR_FS_Lordose_zurueck_Cx1_Ein)}, range raw 0..1, transfer-property=PENDING, to SAM(timeout 3.5 s)  # Anforderung Lordosenwoelbung zu verkleinern.
            signal SPR_FS_Lordose_vor_XIX_SPRs_FS_01_XIX_E3V_SAM_LIN4: start 25, 1 bit, little-endian, data-type-policy=OVERRIDE, i-signal-type=PRIMITIVE, init-value=0, base-type=BT_SPR_FS_Lordose_vor, compu {0=Cx0_Aus (CM_SPR_FS_Lordose_vor_Cx0_Aus), 1=Cx1_Ein (CM_SPR_FS_Lordose_vor_Cx1_Ein)}, range raw 0..1, transfer-property=PENDING, to SAM(timeout 3.5 s)  # Anforderung Lordosenwoelbung pneumatisch zu vergrößern.
            signal SPR_FS_SWL_zurueck_XIX_SPRs_FS_01_XIX_E3V_SAM_LIN4: start 26, 1 bit, little-endian, data-type-policy=OVERRIDE, i-signal-type=PRIMITIVE, init-value=0, base-type=BT_SPR_FS_SWL_zurueck, compu {0=Cx0_Aus (CM_SPR_FS_SWL_zurueck_Cx0_Aus), 1=Cx1_Ein (CM_SPR_FS_SWL_zurueck_Cx1_Ein)}, range raw 0..1, transfer-property=PENDING, to SAM(timeout 3.5 s)  # Anforderung Seitenwangen Lehne zu verkleinern.
            signal SPR_FS_SWL_vor_XIX_SPRs_FS_01_XIX_E3V_SAM_LIN4: start 27, 1 bit, little-endian, data-type-policy=OVERRIDE, i-signal-type=PRIMITIVE, init-value=0, base-type=BT_SPR_FS_SWL_vor, compu {0=Cx0_Aus (CM_SPR_FS_SWL_vor_Cx0_Aus), 1=Cx1_Ein (CM_SPR_FS_SWL_vor_Cx1_Ein)}, range raw 0..1, transfer-property=PENDING, to SAM(timeout 3.5 s)  # Anforderung Seitenwangen Lehne zu vergrößern.
            signal SPR_FS_Unterspannung_XIX_SPRs_FS_01_XIX_E3V_SAM_LIN4: start 28, 1 bit, little-endian, data-type-policy=OVERRIDE, i-signal-type=PRIMITIVE, init-value=0, base-type=BT_SPR_FS_Unterspannung, invalid-value=Invalid_SPR_FS_Unterspannung_XIX_SPRs_FS_01_XIX_E3V_SAM_LIN4:1, compu {0=Cx0_normal (CM_SPR_FS_Unterspannung_Cx0_normal), 1=Cx1_Fehler (CM_SPR_FS_Unterspannung_Cx1_Fehler)}, range raw 0..1, transfer-property=PENDING, to SAM(timeout 3.5 s)  # Je ein Nibble für Speicher-Lesen über LIN-Applikationsbotschaft
            signal SPR_FS_Ueberspannung_XIX_SPRs_FS_01_XIX_E3V_SAM_LIN4: start 29, 1 bit, little-endian, data-type-policy=OVERRIDE, i-signal-type=PRIMITIVE, init-value=0, base-type=BT_SPR_FS_Ueberspannung, invalid-value=Invalid_SPR_FS_Ueberspannung_XIX_SPRs_FS_01_XIX_E3V_SAM_LIN4:1, compu {0=Cx0_normal (CM_SPR_FS_Ueberspannung_Cx0_normal), 1=Cx1_Fehler (CM_SPR_FS_Ueberspannung_Cx1_Fehler)}, range raw 0..1, transfer-property=PENDING, to SAM(timeout 3.5 s)  # Je ein Nibble für Speicher-Lesen über LIN-Applikationsbotschaft
            signal SPR_FS_SG_defekt_XIX_SPRs_FS_01_XIX_E3V_SAM_LIN4: start 30, 1 bit, little-endian, data-type-policy=OVERRIDE, i-signal-type=PRIMITIVE, init-value=0, base-type=BT_SPR_FS_SG_defekt, invalid-value=Invalid_SPR_FS_SG_defekt_XIX_SPRs_FS_01_XIX_E3V_SAM_LIN4:1, compu {0=Cx0_normal (CM_SPR_FS_SG_defekt_Cx0_normal), 1=Cx1_Fehler (CM_SPR_FS_SG_defekt_Cx1_Fehler)}, range raw 0..1, transfer-property=PENDING, to SAM(timeout 3.5 s)  # Je ein Nibble für Speicher-Lesen über LIN-Applikationsbotschaft
            signal SPR_FS_Lokal_aktiv_XIX_SPRs_FS_01_XIX_E3V_SAM_LIN4: start 31, 1 bit, little-endian, data-type-policy=OVERRIDE, i-signal-type=PRIMITIVE, init-value=0, base-type=BT_SPR_FS_Lokal_aktiv, compu {0=Cx0_war_nicht_lokal_aktiv (CM_SPR_FS_Lokal_aktiv_Cx0_war_nicht_lokal_aktiv), 1=Cx1_war_lokal_aktiv (CM_SPR_FS_Lokal_aktiv_Cx1_war_lokal_aktiv)}, range raw 0..1, transfer-property=PENDING, to SAM(timeout 3.5 s)  # Steuergerät war lokal aktiv
            signal SPR_FS_ResponseError_XIX_SPRs_FS_01_XIX_E3V_SAM_LIN4: start 32, 1 bit, little-endian, data-type-policy=OVERRIDE, i-signal-type=PRIMITIVE, init-value=0, base-type=BT_SPR_FS_ResponseError, invalid-value=Invalid_SPR_FS_ResponseError_XIX_SPRs_FS_01_XIX_E3V_SAM_LIN4:1, compu {0=Cx0_normal (CM_SPR_FS_ResponseError_Cx0_normal), 1=Cx1_Fehler (CM_SPR_FS_ResponseError_Cx1_Fehler)}, range raw 0..1, transfer-property=PENDING, to SAM(timeout 3.5 s)  # siehe LIN2.0-Specification (Darf nicht über ein Fehlergueltigkeitsbit abgesichtert werden!)
            signal SPR_FS_PopUp_Request_XIX_SPRs_FS_01_XIX_E3V_SAM_LIN4: start 40, 1 bit, little-endian, data-type-policy=OVERRIDE, i-signal-type=PRIMITIVE, init-value=0, base-type=BT_SPR_FS_PopUp_Request, compu {0=Cx0_keine_Anforderung (CM_SPR_FS_PopUp_Request_Cx0_keine_Anforderung), 1=Cx1_Anforderung_MMI_Popup_Massage (CM_SPR_FS_PopUp_Request_Cx1_Anforderung_MMI_Popup_Massage) (Anforderung_MMI Popup Massage)}, range raw 0..1, transfer-property=PENDING, to SAM(timeout 3.5 s)  # Anforderung MMI Popup für Massage
            signal SPR_FS_Massagetaster_inv_XIX_SPRs_FS_01_XIX_E3V_SAM_LIN4: start 41, 1 bit, little-endian, data-type-policy=OVERRIDE, i-signal-type=PRIMITIVE, init-value=1, base-type=BT_SPR_FS_Massagetaster_inv, compu {0=Cx0_betaetigt (CM_SPR_FS_Massagetaster_inv_Cx0_betaetigt), 1=Cx1_unbetaetigt (CM_SPR_FS_Massagetaster_inv_Cx1_unbetaetigt)}, range raw 0..1, transfer-property=PENDING, to SAM(timeout 3.5 s)  # Signal für Panikabbruch bei Automatikfahrten des Sitzes und der Pneumatikkomponenten mit Memory. Signal invertiert für Rückwärtskompatibilität.
            signal SPR_FS_Teller_inv_XIX_SPRs_FS_01_XIX_E3V_SAM_LIN4: start 42, 1 bit, little-endian, data-type-policy=OVERRIDE, i-signal-type=PRIMITIVE, init-value=1, base-type=BT_SPR_FS_Teller_inv, compu {0=Cx0_betaetigt (CM_SPR_FS_Teller_inv_Cx0_betaetigt), 1=Cx1_unbetaetigt (CM_SPR_FS_Teller_inv_Cx1_unbetaetigt)}, range raw 0..1, transfer-property=PENDING, to SAM(timeout 3.5 s)  # Signal für Panikabbruch bei Automatikfahrten des Sitzes und der Pneumatikkomponenten mit Memory. Signal invertiert für Rückwärtskompatibilität.
            signal SPR_FS_Wippe_inv_XIX_SPRs_FS_01_XIX_E3V_SAM_LIN4: start 43, 1 bit, little-endian, data-type-policy=OVERRIDE, i-signal-type=PRIMITIVE, init-value=1, base-type=BT_SPR_FS_Wippe_inv, compu {0=Cx0_betaetigt (CM_SPR_FS_Wippe_inv_Cx0_betaetigt), 1=Cx1_unbetaetigt (CM_SPR_FS_Wippe_inv_Cx1_unbetaetigt)}, range raw 0..1, transfer-property=PENDING, to SAM(timeout 3.5 s)  # Signal für Panikabbruch bei Automatikfahrten des Sitzes und der Pneumatikkomponenten mit Memory. Signal invertiert für Rückwärtskompatibilität.
            signal SPR_FS_MassageStatus_XIX_SPRs_FS_01_XIX_E3V_SAM_LIN4: start 44, 1 bit, little-endian, data-type-policy=OVERRIDE, i-signal-type=PRIMITIVE, init-value=0, base-type=BT_SPR_FS_MassageStatus, compu {0=Cx0_Aus (CM_SPR_FS_MassageStatus_Cx0_Aus), 1=Cx1_Ein (CM_SPR_FS_MassageStatus_Cx1_Ein)}, range raw 0..1, transfer-property=PENDING, to SAM(timeout 3.5 s)  # MMI Touch-Bedienung FS Massagefunktion (Ein/Aus)
            signal SPR_FS_Wellness_Status_XIX_SPRs_FS_01_XIX_E3V_SAM_LIN4: start 45, 1 bit, little-endian, data-type-policy=OVERRIDE, i-signal-type=PRIMITIVE, init-value=0, base-type=BT_SPR_FS_Wellness_Status, compu {0=Cx0_inaktiv (CM_SPR_FS_Wellness_Status_Cx0_inaktiv), 1=Cx1_aktiv (CM_SPR_FS_Wellness_Status_Cx1_aktiv)}, range raw 0..1, transfer-property=PENDING, to SAM(timeout 3.5 s)  # Info Wellness Status
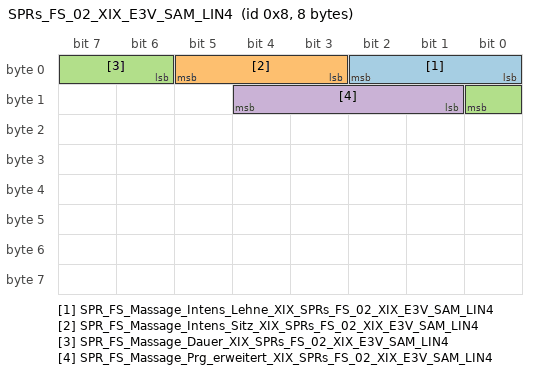
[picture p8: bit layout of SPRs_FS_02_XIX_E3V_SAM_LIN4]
        frame SPRs_FS_02_XIX_E3V_SAM_LIN4: id 0x8, to SAM, frame-length=8, lin-checksum=ENHANCED
          pdu SPRs_FS_02_XIX_E3V_SAM_LIN4: length=8, unused-bit-pattern=0
            signal SPR_FS_Massage_Intens_Lehne_XIX_SPRs_FS_02_XIX_E3V_SAM_LIN4: start 0, 3 bit, little-endian, data-type-policy=OVERRIDE, i-signal-type=PRIMITIVE, init-value=0, base-type=BT_SPR_FS_Massage_Intens_Lehne, compu {0=Cx0_Aus (CM_SPR_FS_Massage_Intens_Lehne_Cx0_Aus), 1=Cx1_Stufe_1 (CM_SPR_FS_Massage_Intens_Lehne_Cx1_Stufe_1), 2=Cx2_Stufe_2 (CM_SPR_FS_Massage_Intens_Lehne_Cx2_Stufe_2), 3=Cx3_Stufe_3 (CM_SPR_FS_Massage_Intens_Lehne_Cx3_Stufe_3), 4=Cx4_Stufe_4 (CM_SPR_FS_Massage_Intens_Lehne_Cx4_Stufe_4), 5=Cx5_Stufe_5 (CM_SPR_FS_Massage_Intens_Lehne_Cx5_Stufe_5), 6=Cx6_reserve (CM_SPR_FS_Massage_Intens_Lehne_Cx6_reserve), 7=Cx7_reserve (CM_SPR_FS_Massage_Intens_Lehne_Cx7_reserve)}, range raw 0..7, transfer-property=PENDING, to SAM(timeout 3.5 s)  # Info Massage Intensität Sitzlehne
            signal SPR_FS_Massage_Intens_Sitz_XIX_SPRs_FS_02_XIX_E3V_SAM_LIN4: start 3, 3 bit, little-endian, data-type-policy=OVERRIDE, i-signal-type=PRIMITIVE, init-value=0, base-type=BT_SPR_FS_Massage_Intens_Sitz, compu {0=Cx0_Aus (CM_SPR_FS_Massage_Intens_Sitz_Cx0_Aus), 1=Cx1_Stufe_1 (CM_SPR_FS_Massage_Intens_Sitz_Cx1_Stufe_1), 2=Cx2_Stufe_2 (CM_SPR_FS_Massage_Intens_Sitz_Cx2_Stufe_2), 3=Cx3_Stufe_3 (CM_SPR_FS_Massage_Intens_Sitz_Cx3_Stufe_3), 4=Cx4_Stufe_4 (CM_SPR_FS_Massage_Intens_Sitz_Cx4_Stufe_4), 5=Cx5_Stufe_5 (CM_SPR_FS_Massage_Intens_Sitz_Cx5_Stufe_5), 6=Cx6_reserve (CM_SPR_FS_Massage_Intens_Sitz_Cx6_reserve), 7=Cx7_reserve (CM_SPR_FS_Massage_Intens_Sitz_Cx7_reserve)}, range raw 0..7, transfer-property=PENDING, to SAM(timeout 3.5 s)  # Info Massage Intensität Sitzkissen
            signal SPR_FS_Massage_Dauer_XIX_SPRs_FS_02_XIX_E3V_SAM_LIN4: start 6, 3 bit, little-endian, data-type-policy=OVERRIDE, i-signal-type=PRIMITIVE, init-value=0, base-type=BT_SPR_FS_Massage_Dauer, compu {0=Cx0_Aus (CM_SPR_FS_Massage_Dauer_Cx0_Aus), 1=Cx1_Dauer_1 (CM_SPR_FS_Massage_Dauer_Cx1_Dauer_1), 2=Cx2_Dauer_2 (CM_SPR_FS_Massage_Dauer_Cx2_Dauer_2), 3=Cx3_Dauer_3 (CM_SPR_FS_Massage_Dauer_Cx3_Dauer_3), 4=Cx4_Dauer_4 (CM_SPR_FS_Massage_Dauer_Cx4_Dauer_4), 5=Cx5_Dauer_5 (CM_SPR_FS_Massage_Dauer_Cx5_Dauer_5), 6=Cx6_reserve (CM_SPR_FS_Massage_Dauer_Cx6_reserve), 7=Cx7_reserve (CM_SPR_FS_Massage_Dauer_Cx7_reserve)}, range raw 0..7, transfer-property=PENDING, to SAM(timeout 3.5 s)  # Info Massage Dauer
            signal SPR_FS_Massage_Prg_erweitert_XIX_SPRs_FS_02_XIX_E3V_SAM_LIN4: start 9, 4 bit, little-endian, data-type-policy=OVERRIDE, i-signal-type=PRIMITIVE, init-value=0, base-type=BT_SPR_FS_Massage_Prg_erweitert, compu {0=Cx0_Aus (CM_SPR_FS_Massage_Prg_erweitert_Cx0_Aus), 1=Cx1_Programm_1 (CM_SPR_FS_Massage_Prg_erweitert_Cx1_Programm_1), 2=Cx2_Programm_2 (CM_SPR_FS_Massage_Prg_erweitert_Cx2_Programm_2), 3=Cx3_Programm_3 (CM_SPR_FS_Massage_Prg_erweitert_Cx3_Programm_3), 4=Cx4_Programm_4 (CM_SPR_FS_Massage_Prg_erweitert_Cx4_Programm_4), 5=Cx5_Programm_5 (CM_SPR_FS_Massage_Prg_erweitert_Cx5_Programm_5), 6=Cx6_Programm_6 (CM_SPR_FS_Massage_Prg_erweitert_Cx6_Programm_6), 7=Cx7_Programm_7 (CM_SPR_FS_Massage_Prg_erweitert_Cx7_Programm_7), 8=Cx8_Programm_8 (CM_SPR_FS_Massage_Prg_erweitert_Cx8_Programm_8), 9=Cx9_Programm_9 (CM_SPR_FS_Massage_Prg_erweitert_Cx9_Programm_9), 10=Cxa_Programm_10 (CM_SPR_FS_Massage_Prg_erweitert_Cxa_Programm_10), 11=Cxb_Programm_11 (CM_SPR_FS_Massage_Prg_erweitert_Cxb_Programm_11), 12=Cxc_Programm_12 (CM_SPR_FS_Massage_Prg_erweitert_Cxc_Programm_12), 13=Cxd_Programm_13 (CM_SPR_FS_Massage_Prg_erweitert_Cxd_Programm_13), 14=Cxe_Programm_14 (CM_SPR_FS_Massage_Prg_erweitert_Cxe_Programm_14), 15=Cxf_Programm_15 (CM_SPR_FS_Massage_Prg_erweitert_Cxf_Programm_15)}, range raw 0..15, transfer-property=PENDING, to SAM(timeout 3.5 s)  # Info Massage Programm erweitert
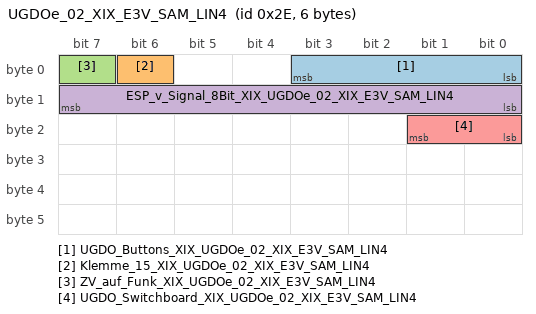
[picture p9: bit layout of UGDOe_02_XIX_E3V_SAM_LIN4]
        frame UGDOe_02_XIX_E3V_SAM_LIN4: id 0x2E, from SAM, frame-length=6, lin-checksum=ENHANCED  # Für BAP-Erweiterung des UGDO-Senders.
          pdu UGDOe_02_XIX_E3V_SAM_LIN4: length=6, unused-bit-pattern=0  # Für BAP-Erweiterung des UGDO-Senders.
            signal UGDO_Buttons_XIX_UGDOe_02_XIX_E3V_SAM_LIN4: start 0, 4 bit, little-endian, data-type-policy=OVERRIDE, i-signal-type=PRIMITIVE, base-type=BT_UGDO_Buttons, compu {0=Cx0_All_buttons_released (CM_UGDO_Buttons_Cx0_All_buttons_released), 1=Cx1_Button_1_Status (CM_UGDO_Buttons_Cx1_Button_1_Status), 2=Cx2_Button_2_Status (CM_UGDO_Buttons_Cx2_Button_2_Status), 3=Cx3_Button_1_2_Status_on (CM_UGDO_Buttons_Cx3_Button_1_2_Status_on), 4=Cx4_Button_3_Status (CM_UGDO_Buttons_Cx4_Button_3_Status), 5=Cx5_Button_1_3_Status_on (CM_UGDO_Buttons_Cx5_Button_1_3_Status_on), 6=Cx6_Button_2_3_Status_on (CM_UGDO_Buttons_Cx6_Button_2_3_Status_on), 7=Cx7_Button_1_2_3_Status_on (CM_UGDO_Buttons_Cx7_Button_1_2_3_Status_on), 8=Cx8_Button_X_Status (CM_UGDO_Buttons_Cx8_Button_X_Status)}, range raw 0..8, transfer-property=PENDING  # Status vom Bedienfeld,Schalterzustände (wird 1:1 vom BCM1 geroutet zum UGDO Sender. Ursprünglicher Sender ist UGDO Bedienteil)
            signal Klemme_15_XIX_UGDOe_02_XIX_E3V_SAM_LIN4: start 6, 1 bit, little-endian, data-type-policy=OVERRIDE, i-signal-type=PRIMITIVE, init-value=0, base-type=BT_Klemme_15, compu {0=Cx0_Aus (CM_Klemme_15_Cx0_Aus), 1=Cx1_Ein (CM_Klemme_15_Cx1_Ein)}, range raw 0..1, transfer-property=PENDING
            signal ZV_auf_Funk_XIX_UGDOe_02_XIX_E3V_SAM_LIN4: start 7, 1 bit, little-endian, data-type-policy=OVERRIDE, i-signal-type=PRIMITIVE, init-value=0, base-type=BT_ZV_auf_Funk, compu {0=Cx0_nicht_betaetigt (CM_ZV_auf_Funk_Cx0_nicht_betaetigt), 1=Cx1_betaetigt (CM_ZV_auf_Funk_Cx1_betaetigt)}, range raw 0..1, transfer-property=PENDING  # ZV Schliessstelle
            signal ESP_v_Signal_8Bit_XIX_UGDOe_02_XIX_E3V_SAM_LIN4: start 8, 8 bit, little-endian, data-type-policy=OVERRIDE, i-signal-type=PRIMITIVE, init-value=254, base-type=BT_ESP_v_Signal_8Bit, compu {phys=raw*2.56 for raw 0..253, 254=Cxfe_Init (CM_ESP_v_Signal_8Bit_Cxfe_Init), 255=Cxff_Fehler (CM_ESP_v_Signal_8Bit_Cxff_Fehler); unit Unit_KiloMeterPerHour}, range phys 0..647.68 Unit_KiloMeterPerHour, raw 0..255, unit=Unit_KiloMeterPerHour, transfer-property=PENDING
            signal UGDO_Switchboard_XIX_UGDOe_02_XIX_E3V_SAM_LIN4: start 16, 2 bit, little-endian, data-type-policy=OVERRIDE, i-signal-type=PRIMITIVE, base-type=BT_UGDO_Switchboard, compu {0=Cx0_Button_function (CM_UGDO_Switchboard_Cx0_Button_function) (Button function), 1=Cx1_Switchboard_failure (CM_UGDO_Switchboard_Cx1_Switchboard_failure) (Switchboard failure)}, range raw 0..1, transfer-property=PENDING  # Status vom Bedienfeld (wird 1:1 vom BCM1 geroutet zum UGDO Sender. Ursprünglicher Sender ist das UGDO Bedienteil)
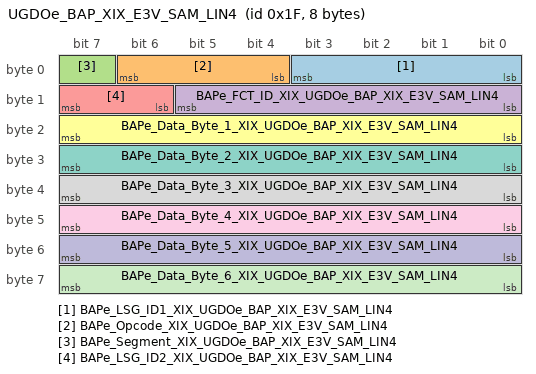
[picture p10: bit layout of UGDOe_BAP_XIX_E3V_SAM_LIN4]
        frame UGDOe_BAP_XIX_E3V_SAM_LIN4: id 0x1F, from SAM, frame-length=8, lin-checksum=ENHANCED
          pdu UGDOe_BAP_XIX_E3V_SAM_LIN4: length=8, unused-bit-pattern=0
            signal BAPe_LSG_ID1_XIX_UGDOe_BAP_XIX_E3V_SAM_LIN4: start 0, 4 bit, little-endian, data-type-policy=OVERRIDE, i-signal-type=PRIMITIVE, init-value=0, base-type=BT_BAPe_LSG_ID1, compu {0=Cx0_Init (CM_BAPe_LSG_ID1_Cx0_Init)}, range raw 0, transfer-property=PENDING  # LSG_ID1 BAP-Botschaft zum UGDO-Sender
            signal BAPe_Opcode_XIX_UGDOe_BAP_XIX_E3V_SAM_LIN4: start 4, 3 bit, little-endian, data-type-policy=OVERRIDE, i-signal-type=PRIMITIVE, init-value=0, base-type=BT_BAPe_Opcode, compu {0=Cx0_Init (CM_BAPe_Opcode_Cx0_Init)}, range raw 0, transfer-property=PENDING  # Opcode BAP-Botschaft zum UGDO-Sender
            signal BAPe_Segment_XIX_UGDOe_BAP_XIX_E3V_SAM_LIN4: start 7, 1 bit, little-endian, data-type-policy=OVERRIDE, i-signal-type=PRIMITIVE, init-value=0, base-type=BT_BAPe_Segment, compu {0=Cx0_Init (CM_BAPe_Segment_Cx0_Init)}, range raw 0, transfer-property=PENDING  # Segment BAP-Botschaft zum UGDO-Sender
            signal BAPe_FCT_ID_XIX_UGDOe_BAP_XIX_E3V_SAM_LIN4: start 8, 6 bit, little-endian, data-type-policy=OVERRIDE, i-signal-type=PRIMITIVE, init-value=0, base-type=BT_BAPe_FCT_ID, compu {0=Cx0_Init (CM_BAPe_FCT_ID_Cx0_Init)}, range raw 0, transfer-property=PENDING  # Fct_ID BAP-Botschaft zum UGDO-Sender
            signal BAPe_LSG_ID2_XIX_UGDOe_BAP_XIX_E3V_SAM_LIN4: start 14, 2 bit, little-endian, data-type-policy=OVERRIDE, i-signal-type=PRIMITIVE, init-value=0, base-type=BT_BAPe_LSG_ID2, compu {0=Cx0_Init (CM_BAPe_LSG_ID2_Cx0_Init)}, range raw 0, transfer-property=PENDING  # LSG_ID2 BAP-Botschaft zum UGDO-Sender
            signal BAPe_Data_Byte_1_XIX_UGDOe_BAP_XIX_E3V_SAM_LIN4: start 16, 8 bit, little-endian, data-type-policy=OVERRIDE, i-signal-type=PRIMITIVE, init-value=0, base-type=BT_BAPe_Data_Byte_1, compu {0=Cx0_Init (CM_BAPe_Data_Byte_1_Cx0_Init)}, range raw 0, transfer-property=PENDING  # Dateninhalt Byte 1 BAP-Botschaft zum UGDO-Sender.
            signal BAPe_Data_Byte_2_XIX_UGDOe_BAP_XIX_E3V_SAM_LIN4: start 24, 8 bit, little-endian, data-type-policy=OVERRIDE, i-signal-type=PRIMITIVE, init-value=0, base-type=BT_BAPe_Data_Byte_2, compu {0=Cx0_Init (CM_BAPe_Data_Byte_2_Cx0_Init)}, range raw 0, transfer-property=PENDING  # Dateninhalt Byte 2 BAP-Botschaft zum UGDO-Sender.
            signal BAPe_Data_Byte_3_XIX_UGDOe_BAP_XIX_E3V_SAM_LIN4: start 32, 8 bit, little-endian, data-type-policy=OVERRIDE, i-signal-type=PRIMITIVE, init-value=0, base-type=BT_BAPe_Data_Byte_3, compu {0=Cx0_Init (CM_BAPe_Data_Byte_3_Cx0_Init)}, range raw 0, transfer-property=PENDING  # Dateninhalt Byte 3 BAP-Botschaft zum UGDO-Sender.
            signal BAPe_Data_Byte_4_XIX_UGDOe_BAP_XIX_E3V_SAM_LIN4: start 40, 8 bit, little-endian, data-type-policy=OVERRIDE, i-signal-type=PRIMITIVE, init-value=0, base-type=BT_BAPe_Data_Byte_4, compu {0=Cx0_Init (CM_BAPe_Data_Byte_4_Cx0_Init)}, range raw 0, transfer-property=PENDING  # Dateninhalt Byte 4 BAP-Botschaft zum UGDO-Sender.
            signal BAPe_Data_Byte_5_XIX_UGDOe_BAP_XIX_E3V_SAM_LIN4: start 48, 8 bit, little-endian, data-type-policy=OVERRIDE, i-signal-type=PRIMITIVE, init-value=0, base-type=BT_BAPe_Data_Byte_5, compu {0=Cx0_Init (CM_BAPe_Data_Byte_5_Cx0_Init)}, range raw 0, transfer-property=PENDING  # Dateninhalt Byte 5 BAP-Botschaft zum UGDO-Sender.
            signal BAPe_Data_Byte_6_XIX_UGDOe_BAP_XIX_E3V_SAM_LIN4: start 56, 8 bit, little-endian, data-type-policy=OVERRIDE, i-signal-type=PRIMITIVE, init-value=0, base-type=BT_BAPe_Data_Byte_6, compu {0=Cx0_Init (CM_BAPe_Data_Byte_6_Cx0_Init)}, range raw 0, transfer-property=PENDING  # Dateninhalt Byte 6 BAP-Botschaft zum UGDO-Sender.
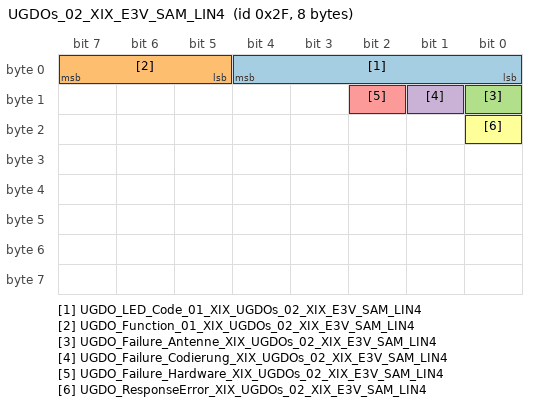
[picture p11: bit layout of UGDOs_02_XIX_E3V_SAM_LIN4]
        frame UGDOs_02_XIX_E3V_SAM_LIN4: id 0x2F, to SAM, frame-length=8, lin-checksum=ENHANCED  # Für BAP-Erweiterung des UGDO-Senders.
          pdu UGDOs_02_XIX_E3V_SAM_LIN4: length=8, unused-bit-pattern=0  # Für BAP-Erweiterung des UGDO-Senders.
            signal UGDO_LED_Code_01_XIX_UGDOs_02_XIX_E3V_SAM_LIN4: start 0, 5 bit, little-endian, data-type-policy=OVERRIDE, i-signal-type=PRIMITIVE, init-value=0, base-type=BT_UGDO_LED_Code_01, compu {0=Cx0_Init (CM_UGDO_LED_Code_01_Cx0_Init), 1=Cx1_LED_green_on (CM_UGDO_LED_Code_01_Cx1_LED_green_on), 2=Cx2_LED_yellow_on (CM_UGDO_LED_Code_01_Cx2_LED_yellow_on), 3=Cx3_LED_red_on (CM_UGDO_LED_Code_01_Cx3_LED_red_on), 4=Cx4_LED_green_flashing_with_10_Hz (CM_UGDO_LED_Code_01_Cx4_LED_green_flashing_with_10_Hz), 5=Cx5_LED_yellow_flashing_with_1_Hz (CM_UGDO_LED_Code_01_Cx5_LED_yellow_flashing_with_1_Hz), 16=Cx10_LED_flashing_off (CM_UGDO_LED_Code_01_Cx10_LED_flashing_off), 17=Cx11_LED_green_flashing_1_x_1_Hz (CM_UGDO_LED_Code_01_Cx11_LED_green_flashing_1_x_1_Hz), 18=Cx12_LED_green_flashing_2_x_1_Hz (CM_UGDO_LED_Code_01_Cx12_LED_green_flashing_2_x_1_Hz), 19=Cx13_LED_green_flashing_3_x_1_Hz (CM_UGDO_LED_Code_01_Cx13_LED_green_flashing_3_x_1_Hz), 20=Cx14_LED_green_flashing_4_x_1_Hz (CM_UGDO_LED_Code_01_Cx14_LED_green_flashing_4_x_1_Hz), 21=Cx15_LED_green_flashing_5_x_1_Hz (CM_UGDO_LED_Code_01_Cx15_LED_green_flashing_5_x_1_Hz), 22=Cx16_LED_green_flashing_6_x_1_Hz (CM_UGDO_LED_Code_01_Cx16_LED_green_flashing_6_x_1_Hz), 23=Cx17_LED_green_flashing_7_x_1_Hz (CM_UGDO_LED_Code_01_Cx17_LED_green_flashing_7_x_1_Hz), 24=Cx18_LED_green_flashing_8_x_1_Hz (CM_UGDO_LED_Code_01_Cx18_LED_green_flashing_8_x_1_Hz), 25=Cx19_LED_green_flashing_9_x_1_Hz (CM_UGDO_LED_Code_01_Cx19_LED_green_flashing_9_x_1_Hz), 26=Cx1a_LED_green_flashing_10_x_1_Hz (CM_UGDO_LED_Code_01_Cx1a_LED_green_flashing_10_x_1_Hz), 27=Cx1b_LED_green_flashing_11_x_1_Hz (CM_UGDO_LED_Code_01_Cx1b_LED_green_flashing_11_x_1_Hz), 28=Cx1c_LED_green_flashing_12_x_1_Hz (CM_UGDO_LED_Code_01_Cx1c_LED_green_flashing_12_x_1_Hz), 29=Cx1d_LED_green_flashing_13_x_1_Hz (CM_UGDO_LED_Code_01_Cx1d_LED_green_flashing_13_x_1_Hz), 30=Cx1e_LED_green_flashing_14_x_1_Hz (CM_UGDO_LED_Code_01_Cx1e_LED_green_flashing_14_x_1_Hz)}, range raw 0..30, transfer-property=PENDING, to SAM(timeout 3.5 s)  # UGDO_Sender = LIN-Slave BCM1 Signal wird bei Kl.15 AUS mit dem letzten empfangenen Wert gesendet
            signal UGDO_Function_01_XIX_UGDOs_02_XIX_E3V_SAM_LIN4: start 5, 3 bit, little-endian, data-type-policy=OVERRIDE, i-signal-type=PRIMITIVE, init-value=0, base-type=BT_UGDO_Function_01, invalid-value=Invalid_UGDO_Function_01_XIX_UGDOs_02_XIX_E3V_SAM_LIN4:7, compu {0=Cx0_LED_Function (CM_UGDO_Function_01_Cx0_LED_Function) (LED Function), 1=Cx1_Transceiver_locked (CM_UGDO_Function_01_Cx1_Transceiver_locked) (Transceiver locked), 2=Cx2_reserviert (CM_UGDO_Function_01_Cx2_reserviert), 3=Cx3_reserviert (CM_UGDO_Function_01_Cx3_reserviert), 4=Cx4_Successful_learned (CM_UGDO_Function_01_Cx4_Successful_learned) (Successful learned), 5=Cx5_reserviert (CM_UGDO_Function_01_Cx5_reserviert), 6=Cx6_Timeout_learning (CM_UGDO_Function_01_Cx6_Timeout_learning) (Timeout learning), 7=Cx7_Fehler (CM_UGDO_Function_01_Cx7_Fehler)}, range raw 0..7, transfer-property=PENDING, to SAM(timeout 3.5 s)  # UGDO_Sender = LIN-Slave BCM1 bei Kl.15 AUS wird für 4s noch der letzte Wert gesendet, danach wird der Wert 7 (= Fehler gesendet)
            signal UGDO_Failure_Antenne_XIX_UGDOs_02_XIX_E3V_SAM_LIN4: start 8, 1 bit, little-endian, data-type-policy=OVERRIDE, i-signal-type=PRIMITIVE, init-value=0, base-type=BT_UGDO_Failure_Antenne, invalid-value=Invalid_UGDO_Failure_Antenne_XIX_UGDOs_02_XIX_E3V_SAM_LIN4:1, compu {0=Cx0_normal (CM_UGDO_Failure_Antenne_Cx0_normal), 1=Cx1_Fehler (CM_UGDO_Failure_Antenne_Cx1_Fehler)}, range raw 0..1, transfer-property=PENDING, to SAM(timeout 3.5 s)  # UGDO = LIN-Slave am BCM1. UGDO-Sender meldet Fehlerstatus ans BCM1.
            signal UGDO_Failure_Codierung_XIX_UGDOs_02_XIX_E3V_SAM_LIN4: start 9, 1 bit, little-endian, data-type-policy=OVERRIDE, i-signal-type=PRIMITIVE, init-value=0, base-type=BT_UGDO_Failure_Codierung, invalid-value=Invalid_UGDO_Failure_Codierung_XIX_UGDOs_02_XIX_E3V_SAM_LIN4:1, compu {0=Cx0_normal (CM_UGDO_Failure_Codierung_Cx0_normal), 1=Cx1_Fehler (CM_UGDO_Failure_Codierung_Cx1_Fehler)}, range raw 0..1, transfer-property=PENDING, to SAM(timeout 3.5 s)  # UGDO = LIN-Slave am BCM1. UGDO-Sender meldet Fehlerstatus ans BCM1.
            signal UGDO_Failure_Hardware_XIX_UGDOs_02_XIX_E3V_SAM_LIN4: start 10, 1 bit, little-endian, data-type-policy=OVERRIDE, i-signal-type=PRIMITIVE, init-value=0, base-type=BT_UGDO_Failure_Hardware, invalid-value=Invalid_UGDO_Failure_Hardware_XIX_UGDOs_02_XIX_E3V_SAM_LIN4:1, compu {0=Cx0_normal (CM_UGDO_Failure_Hardware_Cx0_normal), 1=Cx1_Fehler (CM_UGDO_Failure_Hardware_Cx1_Fehler)}, range raw 0..1, transfer-property=PENDING, to SAM(timeout 3.5 s)  # UGDO = LIN-Slave am BCM1. UGDO-Sender meldet Fehlerstatus ans BCM1.
            signal UGDO_ResponseError_XIX_UGDOs_02_XIX_E3V_SAM_LIN4: start 16, 1 bit, little-endian, data-type-policy=OVERRIDE, i-signal-type=PRIMITIVE, init-value=0, base-type=BT_UGDO_ResponseError, invalid-value=Invalid_UGDO_ResponseError_XIX_UGDOs_02_XIX_E3V_SAM_LIN4:1, compu {0=Cx0_normal (CM_UGDO_ResponseError_Cx0_normal), 1=Cx1_Fehler (CM_UGDO_ResponseError_Cx1_Fehler)}, range raw 0..1, transfer-property=PENDING, to SAM(timeout 3.5 s)  # siehe LIN2.0-Specification (Darf nicht über ein Fehlergueltigkeitsbit abgesichtert werden!)
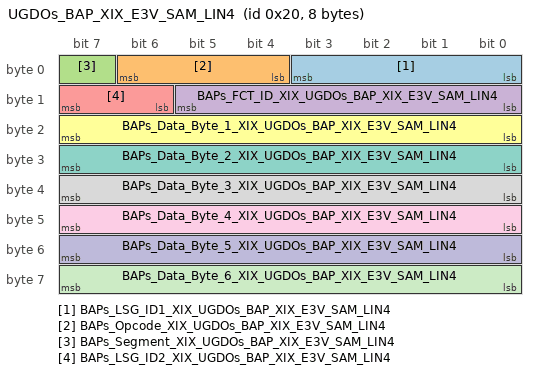
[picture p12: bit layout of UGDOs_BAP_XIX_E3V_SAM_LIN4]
        frame UGDOs_BAP_XIX_E3V_SAM_LIN4: id 0x20, to SAM, frame-length=8, lin-checksum=ENHANCED
          pdu UGDOs_BAP_XIX_E3V_SAM_LIN4: length=8, unused-bit-pattern=0
            signal BAPs_LSG_ID1_XIX_UGDOs_BAP_XIX_E3V_SAM_LIN4: start 0, 4 bit, little-endian, data-type-policy=OVERRIDE, i-signal-type=PRIMITIVE, init-value=0, base-type=BT_BAPs_LSG_ID1, compu {0=Cx0_Init (CM_BAPs_LSG_ID1_Cx0_Init)}, range raw 0, transfer-property=PENDING, to SAM(timeout 3.5 s)  # BAP-Botschaft vom UGDO-Sender
            signal BAPs_Opcode_XIX_UGDOs_BAP_XIX_E3V_SAM_LIN4: start 4, 3 bit, little-endian, data-type-policy=OVERRIDE, i-signal-type=PRIMITIVE, init-value=0, base-type=BT_BAPs_Opcode, compu {0=Cx0_Init (CM_BAPs_Opcode_Cx0_Init)}, range raw 0, transfer-property=PENDING, to SAM(timeout 3.5 s)  # BAP-Botschaft vom UGDO-Sender.
            signal BAPs_Segment_XIX_UGDOs_BAP_XIX_E3V_SAM_LIN4: start 7, 1 bit, little-endian, data-type-policy=OVERRIDE, i-signal-type=PRIMITIVE, init-value=0, base-type=BT_BAPs_Segment, compu {0=Cx0_Init (CM_BAPs_Segment_Cx0_Init)}, range raw 0, transfer-property=PENDING, to SAM(timeout 3.5 s)  # BAP-Botschaft vom UGDO-Sender.
            signal BAPs_FCT_ID_XIX_UGDOs_BAP_XIX_E3V_SAM_LIN4: start 8, 6 bit, little-endian, data-type-policy=OVERRIDE, i-signal-type=PRIMITIVE, init-value=0, base-type=BT_BAPs_FCT_ID, compu {0=Cx0_Init (CM_BAPs_FCT_ID_Cx0_Init)}, range raw 0, transfer-property=PENDING, to SAM(timeout 3.5 s)  # BAP-Botschaft vom UGDO-Sender
            signal BAPs_LSG_ID2_XIX_UGDOs_BAP_XIX_E3V_SAM_LIN4: start 14, 2 bit, little-endian, data-type-policy=OVERRIDE, i-signal-type=PRIMITIVE, init-value=0, base-type=BT_BAPs_LSG_ID2, compu {0=Cx0_Init (CM_BAPs_LSG_ID2_Cx0_Init)}, range raw 0, transfer-property=PENDING, to SAM(timeout 3.5 s)  # BAP-Botschaft vom UGDO-Sender.
            signal BAPs_Data_Byte_1_XIX_UGDOs_BAP_XIX_E3V_SAM_LIN4: start 16, 8 bit, little-endian, data-type-policy=OVERRIDE, i-signal-type=PRIMITIVE, init-value=0, base-type=BT_BAPs_Data_Byte_1, compu {0=Cx0_Init (CM_BAPs_Data_Byte_1_Cx0_Init)}, range raw 0, transfer-property=PENDING, to SAM(timeout 3.5 s)  # Dateninhalt Byte 1 BAP-Botschaft vom UGDO-Sender.
            signal BAPs_Data_Byte_2_XIX_UGDOs_BAP_XIX_E3V_SAM_LIN4: start 24, 8 bit, little-endian, data-type-policy=OVERRIDE, i-signal-type=PRIMITIVE, init-value=0, base-type=BT_BAPs_Data_Byte_2, compu {0=Cx0_Init (CM_BAPs_Data_Byte_2_Cx0_Init)}, range raw 0, transfer-property=PENDING, to SAM(timeout 3.5 s)  # Dateninhalt Byte 2 BAP-Botschaft vom UGDO-Sender.
            signal BAPs_Data_Byte_3_XIX_UGDOs_BAP_XIX_E3V_SAM_LIN4: start 32, 8 bit, little-endian, data-type-policy=OVERRIDE, i-signal-type=PRIMITIVE, init-value=0, base-type=BT_BAPs_Data_Byte_3, compu {0=Cx0_Init (CM_BAPs_Data_Byte_3_Cx0_Init)}, range raw 0, transfer-property=PENDING, to SAM(timeout 3.5 s)  # Dateninhalt Byte 3 BAP-Botschaft vom UGDO-Sender.
            signal BAPs_Data_Byte_4_XIX_UGDOs_BAP_XIX_E3V_SAM_LIN4: start 40, 8 bit, little-endian, data-type-policy=OVERRIDE, i-signal-type=PRIMITIVE, init-value=0, base-type=BT_BAPs_Data_Byte_4, compu {0=Cx0_Init (CM_BAPs_Data_Byte_4_Cx0_Init)}, range raw 0, transfer-property=PENDING, to SAM(timeout 3.5 s)  # Dateninhalt Byte 4 BAP-Botschaft vom UGDO-Sender.
            signal BAPs_Data_Byte_5_XIX_UGDOs_BAP_XIX_E3V_SAM_LIN4: start 48, 8 bit, little-endian, data-type-policy=OVERRIDE, i-signal-type=PRIMITIVE, init-value=0, base-type=BT_BAPs_Data_Byte_5, compu {0=Cx0_Init (CM_BAPs_Data_Byte_5_Cx0_Init)}, range raw 0, transfer-property=PENDING, to SAM(timeout 3.5 s)  # Dateninhalt Byte 5 BAP-Botschaft vom UGDO-Sender.
            signal BAPs_Data_Byte_6_XIX_UGDOs_BAP_XIX_E3V_SAM_LIN4: start 56, 8 bit, little-endian, data-type-policy=OVERRIDE, i-signal-type=PRIMITIVE, init-value=0, base-type=BT_BAPs_Data_Byte_6, compu {0=Cx0_Init (CM_BAPs_Data_Byte_6_Cx0_Init)}, range raw 0, transfer-property=PENDING, to SAM(timeout 3.5 s)  # Dateninhalt Byte 6 BAP-Botschaft vom UGDO-Sender.
        pdu triggering PT_E3V_SAM_LIN4_XIX_TPCHType_LIN_Diagnose_XIX_0x0_XIX_0x15_XIX_Physical: pdu=DCM_E3V_SAM_LIN4_XIX_TPCHType_LIN_Diagnose_XIX_0x0_XIX_0x15_XIX_Physical, from SAM
        pdu triggering PT_E3V_SAM_LIN4_XIX_TPCHType_LIN_Diagnose_XIX_0x0_XIX_0x17_XIX_Physical: pdu=DCM_E3V_SAM_LIN4_XIX_TPCHType_LIN_Diagnose_XIX_0x0_XIX_0x17_XIX_Physical, from SAM
        pdu triggering PT_E3V_SAM_LIN4_XIX_TPCHType_LIN_Diagnose_XIX_0x0_XIX_0x1_XIX_Physical: pdu=DCM_E3V_SAM_LIN4_XIX_TPCHType_LIN_Diagnose_XIX_0x0_XIX_0x1_XIX_Physical, from SAM
        pdu triggering PT_E3V_SAM_LIN4_XIX_TPCHType_LIN_Diagnose_XIX_0x0_XIX_0x40_XIX_Physical: pdu=DCM_E3V_SAM_LIN4_XIX_TPCHType_LIN_Diagnose_XIX_0x0_XIX_0x40_XIX_Physical, from SAM
        pdu triggering PT_E3V_SAM_LIN4_XIX_TPCHType_LIN_Diagnose_XIX_0x0_XIX_0x41_XIX_Physical: pdu=DCM_E3V_SAM_LIN4_XIX_TPCHType_LIN_Diagnose_XIX_0x0_XIX_0x41_XIX_Physical, from SAM
        pdu triggering PT_E3V_SAM_LIN4_XIX_TPCHType_LIN_Diagnose_XIX_0x0_XIX_0xD_XIX_Physical: pdu=DCM_E3V_SAM_LIN4_XIX_TPCHType_LIN_Diagnose_XIX_0x0_XIX_0xD_XIX_Physical, from SAM
        pdu triggering PT_E3V_SAM_LIN4_XIX_TPCHType_LIN_Diagnose_XIX_0x0_XIX_0xF_XIX_Physical: pdu=DCM_E3V_SAM_LIN4_XIX_TPCHType_LIN_Diagnose_XIX_0x0_XIX_0xF_XIX_Physical, from SAM
        pdu triggering PT_E3V_SAM_LIN4_XIX_TPCHType_LIN_Diagnose_XIX_0x15_XIX_0x0_XIX_Physical: pdu=DCM_E3V_SAM_LIN4_XIX_TPCHType_LIN_Diagnose_XIX_0x15_XIX_0x0_XIX_Physical, to SAM
        pdu triggering PT_E3V_SAM_LIN4_XIX_TPCHType_LIN_Diagnose_XIX_0x17_XIX_0x0_XIX_Physical: pdu=DCM_E3V_SAM_LIN4_XIX_TPCHType_LIN_Diagnose_XIX_0x17_XIX_0x0_XIX_Physical, to SAM
        pdu triggering PT_E3V_SAM_LIN4_XIX_TPCHType_LIN_Diagnose_XIX_0x1_XIX_0x0_XIX_Physical: pdu=DCM_E3V_SAM_LIN4_XIX_TPCHType_LIN_Diagnose_XIX_0x1_XIX_0x0_XIX_Physical, to SAM
        pdu triggering PT_E3V_SAM_LIN4_XIX_TPCHType_LIN_Diagnose_XIX_0x40_XIX_0x0_XIX_Physical: pdu=DCM_E3V_SAM_LIN4_XIX_TPCHType_LIN_Diagnose_XIX_0x40_XIX_0x0_XIX_Physical, to SAM
        pdu triggering PT_E3V_SAM_LIN4_XIX_TPCHType_LIN_Diagnose_XIX_0x41_XIX_0x0_XIX_Physical: pdu=DCM_E3V_SAM_LIN4_XIX_TPCHType_LIN_Diagnose_XIX_0x41_XIX_0x0_XIX_Physical, to SAM
        pdu triggering PT_E3V_SAM_LIN4_XIX_TPCHType_LIN_Diagnose_XIX_0xD_XIX_0x0_XIX_Physical: pdu=DCM_E3V_SAM_LIN4_XIX_TPCHType_LIN_Diagnose_XIX_0xD_XIX_0x0_XIX_Physical, to SAM
        pdu triggering PT_E3V_SAM_LIN4_XIX_TPCHType_LIN_Diagnose_XIX_0xF_XIX_0x0_XIX_Physical: pdu=DCM_E3V_SAM_LIN4_XIX_TPCHType_LIN_Diagnose_XIX_0xF_XIX_0x0_XIX_Physical, to SAM
        lin schedule table DiagRequest: resume-position=CONTINUE-AT-IT-POSITION, run-mode=RUN-ONCE, application-entry{delay=0.01, position-in-table=0, frame-triggering=CHNL/FT_MasterReq}
        lin schedule table DiagResponse: resume-position=CONTINUE-AT-IT-POSITION, run-mode=RUN-ONCE, application-entry{delay=0.01, position-in-table=0, frame-triggering=CHNL/FT_SlaveResp}
        lin schedule table st_main: resume-position=CONTINUE-AT-IT-POSITION, run-mode=RUN-CONTINUOUS
          table-entrys:
            delay=0.01, position-in-table=0, frame-triggering=FT_LLRe_L_01
            delay=0.01, position-in-table=1, frame-triggering=FT_SPRe_02
            delay=0.01, position-in-table=2, frame-triggering=FT_UGDOe_BAP
            delay=0.01, position-in-table=3, frame-triggering=FT_UGDOe_02
            delay=0.01, position-in-table=4, frame-triggering=FT_SPRe_01
            delay=0.01, position-in-table=5, frame-triggering=FT_LLRs_LL_01
            delay=0.01, position-in-table=6, frame-triggering=FT_UGDOs_BAP
            delay=0.01, position-in-table=7, frame-triggering=FT_LLRs_LS_01
            delay=0.01, position-in-table=8, frame-triggering=FT_SPRs_FS_02
            delay=0.01, position-in-table=9, frame-triggering=FT_SPRs_BFS_02
            delay=0.02, position-in-table=10, frame-triggering=FT_UGDOe_BAP
            delay=0.01, position-in-table=11, frame-triggering=FT_LLRe_R_01
            delay=0.01, position-in-table=12, frame-triggering=FT_UGDOs_02
            delay=0.01, position-in-table=13, frame-triggering=FT_UGDOs_BAP
            delay=0.01, position-in-table=14, frame-triggering=FT_SPRs_FS_01
            delay=0.02, position-in-table=15, frame-triggering=FT_SPRs_BFS_01
            delay=0.01, position-in-table=16, frame-triggering=FT_UGDOe_BAP
            delay=0.01, position-in-table=17, frame-triggering=FT_LLRs_RL_01
            delay=0.02, position-in-table=18, frame-triggering=FT_LLRs_RS_01
            delay=0.02, position-in-table=19, frame-triggering=FT_UGDOs_BAP
    E3V_SAM_LIN12
      lin physical channel CHNL: comm-connectors=CN_E3V_SAM_LIN12
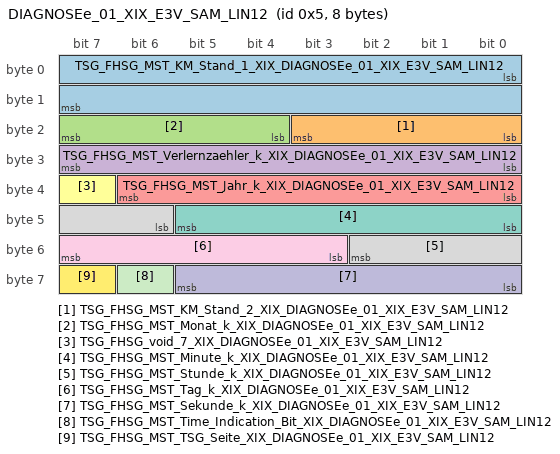
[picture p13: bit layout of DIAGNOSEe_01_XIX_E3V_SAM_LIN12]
        frame DIAGNOSEe_01_XIX_E3V_SAM_LIN12: id 0x5, from SAM, frame-length=8, lin-checksum=ENHANCED
          pdu DIAGNOSEe_01_XIX_E3V_SAM_LIN12: length=8, unused-bit-pattern=0
            signal TSG_FHSG_MST_KM_Stand_1_XIX_DIAGNOSEe_01_XIX_E3V_SAM_LIN12: start 0, 16 bit, little-endian, data-type-policy=OVERRIDE, i-signal-type=PRIMITIVE, init-value=0, base-type=BT_TSG_FHSG_MST_KM_Stand_1, transfer-property=PENDING  # Umweltdaten Kilometerstand
            signal TSG_FHSG_MST_KM_Stand_2_XIX_DIAGNOSEe_01_XIX_E3V_SAM_LIN12: start 16, 4 bit, little-endian, data-type-policy=OVERRIDE, i-signal-type=PRIMITIVE, init-value=0, base-type=BT_TSG_FHSG_MST_KM_Stand_2, transfer-property=PENDING  # Umweltdaten Kilometerstand
            signal TSG_FHSG_MST_Monat_k_XIX_DIAGNOSEe_01_XIX_E3V_SAM_LIN12: start 20, 4 bit, little-endian, data-type-policy=OVERRIDE, i-signal-type=PRIMITIVE, init-value=0, base-type=BT_TSG_FHSG_MST_Monat_k, compu {0=Cx0_Init (CM_TSG_FHSG_MST_Monat_k_Cx0_Init), phys=raw for raw 1..12; unit Unit_Month}, range phys 1..12 Unit_Month, raw 0..12, unit=Unit_Month, transfer-property=PENDING  # Fehlende Beschreibung (Import)
            signal TSG_FHSG_MST_Verlernzaehler_k_XIX_DIAGNOSEe_01_XIX_E3V_SAM_LIN12: start 24, 8 bit, little-endian, data-type-policy=OVERRIDE, i-signal-type=PRIMITIVE, init-value=0, base-type=BT_TSG_FHSG_MST_Verlernzaehler_k, compu {phys=raw for raw 0..254, 255=Cxff_ungueltiger_Zaehlerstand_oder_kein_gueltiger_Fahrzyklus (CM_TSG_FHSG_MST_Verlernzaehler_k_Cxff_ungueltiger_Zaehlerstand_oder_kein_gueltiger_Fahrzyklus)}, range phys 0..254, raw 0..255, transfer-property=PENDING
            signal TSG_FHSG_MST_Jahr_k_XIX_DIAGNOSEe_01_XIX_E3V_SAM_LIN12: start 32, 7 bit, little-endian, data-type-policy=OVERRIDE, i-signal-type=PRIMITIVE, init-value=0, base-type=BT_TSG_FHSG_MST_Jahr_k, compu {phys=raw+2000 for raw 0..127; unit Unit_Year}, range phys 2000..2127 Unit_Year, raw 0..127, unit=Unit_Year, transfer-property=PENDING  # Umweltdaten für Ereignisspeicher
            signal TSG_FHSG_void_7_XIX_DIAGNOSEe_01_XIX_E3V_SAM_LIN12: start 39, 1 bit, little-endian, data-type-policy=OVERRIDE, i-signal-type=PRIMITIVE, init-value=0, base-type=BT_TSG_FHSG_void_7, transfer-property=PENDING  # reserviert
            signal TSG_FHSG_MST_Minute_k_XIX_DIAGNOSEe_01_XIX_E3V_SAM_LIN12: start 40, 6 bit, little-endian, data-type-policy=OVERRIDE, i-signal-type=PRIMITIVE, init-value=0, base-type=BT_TSG_FHSG_MST_Minute_k, compu {phys=raw for raw 0..59; unit Unit_Minut}, range phys 0..59 Unit_Minut, raw 0..59, unit=Unit_Minut, transfer-property=PENDING  # Umweltdaten für Ereignisspeicher
            signal TSG_FHSG_MST_Stunde_k_XIX_DIAGNOSEe_01_XIX_E3V_SAM_LIN12: start 46, 5 bit, little-endian, data-type-policy=OVERRIDE, i-signal-type=PRIMITIVE, init-value=0, base-type=BT_TSG_FHSG_MST_Stunde_k, compu {phys=raw for raw 0..23; unit Unit_Hours}, range phys 0..23 Unit_Hours, raw 0..23, unit=Unit_Hours, transfer-property=PENDING  # Umweltdaten für Ereignisspeicher
            signal TSG_FHSG_MST_Tag_k_XIX_DIAGNOSEe_01_XIX_E3V_SAM_LIN12: start 51, 5 bit, little-endian, data-type-policy=OVERRIDE, i-signal-type=PRIMITIVE, init-value=0, base-type=BT_TSG_FHSG_MST_Tag_k, compu {phys=raw for raw 1..31; unit Unit_Day}, range phys 1..31 Unit_Day, raw 1..31, unit=Unit_Day, transfer-property=PENDING  # Umweltdaten für Ereignisspeicher
            signal TSG_FHSG_MST_Sekunde_k_XIX_DIAGNOSEe_01_XIX_E3V_SAM_LIN12: start 56, 6 bit, little-endian, data-type-policy=OVERRIDE, i-signal-type=PRIMITIVE, init-value=0, base-type=BT_TSG_FHSG_MST_Sekunde_k, compu {phys=raw for raw 0..59; unit Unit_Secon}, range phys 0..59 Unit_Secon, raw 0..59, unit=Unit_Secon, transfer-property=PENDING  # Umweltdaten für Ereignisspeicher
            signal TSG_FHSG_MST_Time_Indication_Bit_XIX_DIAGNOSEe_01_XIX_E3V_SAM_LIN12: start 62, 1 bit, little-endian, data-type-policy=OVERRIDE, i-signal-type=PRIMITIVE, init-value=0, base-type=BT_TSG_FHSG_MST_Time_Indication_Bit, transfer-property=PENDING  # Umweltdaten für Ereignisspeicher
            signal TSG_FHSG_MST_TSG_Seite_XIX_DIAGNOSEe_01_XIX_E3V_SAM_LIN12: start 63, 1 bit, little-endian, data-type-policy=OVERRIDE, i-signal-type=PRIMITIVE, init-value=0, base-type=BT_TSG_FHSG_MST_TSG_Seite, compu {0=Cx0_Hinten_Beifahrer_Kreuzverbau (CM_TSG_FHSG_MST_TSG_Seite_Cx0_Hinten_Beifahrer_Kreuzverbau) (Hinten_Beifahrer__Kreuzverbau), 1=Cx1_Hinten_Fahrer_Normalverbau (CM_TSG_FHSG_MST_TSG_Seite_Cx1_Hinten_Fahrer_Normalverbau) (Hinten_Fahrer__Normalverbau)}, range raw 0..1, transfer-property=PENDING  # Information für die hinteren FHSG über die Verbaulage (Normal-/Kreuzverbau).
        frame FHSG_HBFSs01_XIX_E3V_SAM_LIN12: id 0x18, to SAM, frame-length=8, lin-checksum=ENHANCED
          pdu FHSG_HBFSs01_XIX_E3V_SAM_LIN12: length=8, unused-bit-pattern=0
            signal HBFS_FH_S_ManHoch_XIX_FHSG_HBFSs01_XIX_E3V_SAM_LIN12: start 0, 1 bit, little-endian, data-type-policy=OVERRIDE, i-signal-type=PRIMITIVE, init-value=0, base-type=BT_HBFS_FH_S_ManHoch, compu {0=Cx0_nicht_betaetigt (CM_HBFS_FH_S_ManHoch_Cx0_nicht_betaetigt), 1=Cx1_betaetigt (CM_HBFS_FH_S_ManHoch_Cx1_betaetigt)}, range raw 0..1, transfer-property=PENDING, to SAM(timeout 3.5 s)  # Betaetigung FH Schalter man hoch
            signal HBFS_FH_S_AutoHoch_XIX_FHSG_HBFSs01_XIX_E3V_SAM_LIN12: start 1, 1 bit, little-endian, data-type-policy=OVERRIDE, i-signal-type=PRIMITIVE, init-value=0, base-type=BT_HBFS_FH_S_AutoHoch, compu {0=Cx0_nicht_betaetigt (CM_HBFS_FH_S_AutoHoch_Cx0_nicht_betaetigt), 1=Cx1_betaetigt (CM_HBFS_FH_S_AutoHoch_Cx1_betaetigt)}, range raw 0..1, transfer-property=PENDING, to SAM(timeout 3.5 s)  # Betaetigung FH Schalter auto tief
            signal HBFS_FH_S_ManTief_XIX_FHSG_HBFSs01_XIX_E3V_SAM_LIN12: start 2, 1 bit, little-endian, data-type-policy=OVERRIDE, i-signal-type=PRIMITIVE, init-value=0, base-type=BT_HBFS_FH_S_ManTief, compu {0=Cx0_nicht_betaetigt (CM_HBFS_FH_S_ManTief_Cx0_nicht_betaetigt), 1=Cx1_betaetigt (CM_HBFS_FH_S_ManTief_Cx1_betaetigt)}, range raw 0..1, transfer-property=PENDING, to SAM(timeout 3.5 s)  # Betaetigung FH Schalter man tief
            signal HBFS_FH_S_AutoTief_XIX_FHSG_HBFSs01_XIX_E3V_SAM_LIN12: start 3, 1 bit, little-endian, data-type-policy=OVERRIDE, i-signal-type=PRIMITIVE, init-value=0, base-type=BT_HBFS_FH_S_AutoTief, compu {0=Cx0_nicht_betaetigt (CM_HBFS_FH_S_AutoTief_Cx0_nicht_betaetigt), 1=Cx1_betaetigt (CM_HBFS_FH_S_AutoTief_Cx1_betaetigt)}, range raw 0..1, transfer-property=PENDING, to SAM(timeout 3.5 s)  # Betaetigung FH Schalter auto hoch
            signal HBFS_Status_Routine_XIX_FHSG_HBFSs01_XIX_E3V_SAM_LIN12: start 4, 2 bit, little-endian, data-type-policy=OVERRIDE, i-signal-type=PRIMITIVE, init-value=0, base-type=BT_HBFS_Status_Routine, compu {0=Cx0_nicht_gestartet (CM_HBFS_Status_Routine_Cx0_nicht_gestartet), 1=Cx1_mind_eine_Routine_laueft (CM_HBFS_Status_Routine_Cx1_mind_eine_Routine_laueft), 2=Cx2_Abbruch (CM_HBFS_Status_Routine_Cx2_Abbruch), 3=Cx3_kann_nicht_beendet_werden (CM_HBFS_Status_Routine_Cx3_kann_nicht_beendet_werden)}, range raw 0..3, transfer-property=PENDING, to SAM(timeout 3.5 s)  # Rückmeldung des Status der SG Routinen
            signal HBFS_Status_Stellgliedtest_XIX_FHSG_HBFSs01_XIX_E3V_SAM_LIN12: start 6, 2 bit, little-endian, data-type-policy=OVERRIDE, i-signal-type=PRIMITIVE, init-value=0, base-type=BT_HBFS_Status_Stellgliedtest, compu {0=Cx0_nicht_gestartet (CM_HBFS_Status_Stellgliedtest_Cx0_nicht_gestartet), 1=Cx1_mind_ein_SGT_laueft (CM_HBFS_Status_Stellgliedtest_Cx1_mind_ein_SGT_laueft), 2=Cx2_Abbruch_wg_Zeit (CM_HBFS_Status_Stellgliedtest_Cx2_Abbruch_wg_Zeit), 3=Cx3_Abbruch_wg_Sicherheit (CM_HBFS_Status_Stellgliedtest_Cx3_Abbruch_wg_Sicherheit)}, range raw 0..3, transfer-property=PENDING, to SAM(timeout 3.5 s)  # Rückmeldung des Status vom Stellgliedtest
            signal HBFS_FH_void_2_XIX_FHSG_HBFSs01_XIX_E3V_SAM_LIN12: start 8, 8 bit, little-endian, data-type-policy=OVERRIDE, i-signal-type=PRIMITIVE, init-value=0, base-type=BT_HBFS_FH_void_2, transfer-property=PENDING  # reserviert
            signal HBFS_TIG_betaetigt_XIX_FHSG_HBFSs01_XIX_E3V_SAM_LIN12: start 16, 1 bit, little-endian, data-type-policy=OVERRIDE, i-signal-type=PRIMITIVE, init-value=0, base-type=BT_HBFS_TIG_betaetigt, compu {0=Cx0_nicht_betaetigt (CM_HBFS_TIG_betaetigt_Cx0_nicht_betaetigt), 1=Cx1_betaetigt (CM_HBFS_TIG_betaetigt_Cx1_betaetigt)}, range raw 0..1, transfer-property=PENDING  # Betaetigung Tuerinnengriff
            signal HBFS_TAG_betaetigt_XIX_FHSG_HBFSs01_XIX_E3V_SAM_LIN12: start 17, 1 bit, little-endian, data-type-policy=OVERRIDE, i-signal-type=PRIMITIVE, init-value=0, base-type=BT_HBFS_TAG_betaetigt, compu {0=Cx0_nicht_betaetigt (CM_HBFS_TAG_betaetigt_Cx0_nicht_betaetigt), 1=Cx1_betaetigt (CM_HBFS_TAG_betaetigt_Cx1_betaetigt)}, range raw 0..1, transfer-property=PENDING  # Betaetigung Türaussengriff
            signal HBFS_FH_void_3_XIX_FHSG_HBFSs01_XIX_E3V_SAM_LIN12: start 18, 6 bit, little-endian, data-type-policy=OVERRIDE, i-signal-type=PRIMITIVE, init-value=0, base-type=BT_HBFS_FH_void_3, transfer-property=PENDING  # reserviert
            signal HBFS_FH_Oeffnung_XIX_FHSG_HBFSs01_XIX_E3V_SAM_LIN12: start 24, 8 bit, little-endian, data-type-policy=OVERRIDE, i-signal-type=PRIMITIVE, init-value=0, base-type=BT_HBFS_FH_Oeffnung, compu {phys=raw*0.5 for raw 0..200; unit Unit_PerCent}, range phys 0..100 Unit_PerCent, raw 0..200, unit=Unit_PerCent, transfer-property=PENDING, to SAM(timeout 3.5 s)  # Gibt den Fensteröffnungswert in % an.
            signal HBFS_FH_Bew_hoch_XIX_FHSG_HBFSs01_XIX_E3V_SAM_LIN12: start 32, 1 bit, little-endian, data-type-policy=OVERRIDE, i-signal-type=PRIMITIVE, init-value=0, base-type=BT_HBFS_FH_Bew_hoch, compu {0=Cx0_inaktiv (CM_HBFS_FH_Bew_hoch_Cx0_inaktiv), 1=Cx1_aktiv (CM_HBFS_FH_Bew_hoch_Cx1_aktiv)}, range raw 0..1, transfer-property=PENDING, to SAM(timeout 3.5 s)  # HBFS Fenster bewegt sich in Richtung hoch
            signal HBFS_FH_Bew_tief_XIX_FHSG_HBFSs01_XIX_E3V_SAM_LIN12: start 33, 1 bit, little-endian, data-type-policy=OVERRIDE, i-signal-type=PRIMITIVE, init-value=0, base-type=BT_HBFS_FH_Bew_tief, compu {0=Cx0_inaktiv (CM_HBFS_FH_Bew_tief_Cx0_inaktiv), 1=Cx1_aktiv (CM_HBFS_FH_Bew_tief_Cx1_aktiv)}, range raw 0..1, transfer-property=PENDING, to SAM(timeout 3.5 s)  # HBFS Fenster bewegt sich in Richtung tief
            signal HBFS_Oben_Block_erw_XIX_FHSG_HBFSs01_XIX_E3V_SAM_LIN12: start 34, 1 bit, little-endian, data-type-policy=OVERRIDE, i-signal-type=PRIMITIVE, init-value=0, base-type=BT_HBFS_Oben_Block_erw, compu {0=Cx0_Fensterheber_nicht_in_Blockerwar (CM_HBFS_Oben_Block_erw_Cx0_Fensterheber_nicht_in_Blockerwar), 1=Cx1_Fensterheber_in_Blockerwartung_o (CM_HBFS_Oben_Block_erw_Cx1_Fensterheber_in_Blockerwartung_o)}, range raw 0..1, transfer-property=PENDING, to SAM(timeout 3.5 s)  # Fensterheber in Blockerwartung oben
            signal HBFS_Unten_Block_erw_XIX_FHSG_HBFSs01_XIX_E3V_SAM_LIN12: start 35, 1 bit, little-endian, data-type-policy=OVERRIDE, i-signal-type=PRIMITIVE, init-value=0, base-type=BT_HBFS_Unten_Block_erw, compu {0=Cx0_Fensterheber_nicht_in_Blockerwar (CM_HBFS_Unten_Block_erw_Cx0_Fensterheber_nicht_in_Blockerwar), 1=Cx1_Fensterheber_in_Blockerwartung_u (CM_HBFS_Unten_Block_erw_Cx1_Fensterheber_in_Blockerwartung_u)}, range raw 0..1, transfer-property=PENDING, to SAM(timeout 3.5 s)  # Fensterheber in Blockerwartung unten
            signal HBFS_FH_Block_XIX_FHSG_HBFSs01_XIX_E3V_SAM_LIN12: start 36, 1 bit, little-endian, data-type-policy=OVERRIDE, i-signal-type=PRIMITIVE, init-value=0, base-type=BT_HBFS_FH_Block, compu {0=Cx0_inaktiv (CM_HBFS_FH_Block_Cx0_inaktiv), 1=Cx1_aktiv (CM_HBFS_FH_Block_Cx1_aktiv)}, range raw 0..1, transfer-property=PENDING, to SAM(timeout 3.5 s)  # Fensterscheibe befindet sich im mechanischen Block (oben oder unten)
            signal HBFS_FH_Fang_XIX_FHSG_HBFSs01_XIX_E3V_SAM_LIN12: start 37, 1 bit, little-endian, data-type-policy=OVERRIDE, i-signal-type=PRIMITIVE, init-value=0, base-type=BT_HBFS_FH_Fang, compu {0=Cx0_ausserhalb_Fangbereich (CM_HBFS_FH_Fang_Cx0_ausserhalb_Fangbereich), 1=Cx1_innerhalb_Fangbereich (CM_HBFS_FH_Fang_Cx1_innerhalb_Fangbereich)}, range raw 0..1, transfer-property=PENDING, to SAM(timeout 3.5 s)  # Fangbereich ist 4mm von oberer Lippendichtung
            signal HBFS_UEKB_aktiviert_XIX_FHSG_HBFSs01_XIX_E3V_SAM_LIN12: start 38, 1 bit, little-endian, data-type-policy=OVERRIDE, i-signal-type=PRIMITIVE, init-value=0, base-type=BT_HBFS_UEKB_aktiviert, compu {0=Cx0_inaktiv (CM_HBFS_UEKB_aktiviert_Cx0_inaktiv), 1=Cx1_aktiv (CM_HBFS_UEKB_aktiviert_Cx1_aktiv)}, range raw 0..1, transfer-property=PENDING, to SAM(timeout 3.5 s)  # Überschutzbegrenzungskraft bei Reversieren
            signal HBFS_Fehler_FH_Normierung_XIX_FHSG_HBFSs01_XIX_E3V_SAM_LIN12: start 39, 1 bit, little-endian, data-type-policy=OVERRIDE, i-signal-type=PRIMITIVE, init-value=0, base-type=BT_HBFS_Fehler_FH_Normierung, invalid-value=Invalid_HBFS_Fehler_FH_Normierung_XIX_FHSG_HBFSs01_XIX_E3V_SAM_LIN12:1, compu {0=Cx0_kein_Fehler (CM_HBFS_Fehler_FH_Normierung_Cx0_kein_Fehler), 1=Cx1_Fehler (CM_HBFS_Fehler_FH_Normierung_Cx1_Fehler)}, range raw 0..1, transfer-property=PENDING, to SAM(timeout 3.5 s)  # Normierung Fensterheber hinten Beifahrerseite fehlgeschlagen.
            signal HBFS_Status_KiSi_XIX_FHSG_HBFSs01_XIX_E3V_SAM_LIN12: start 40, 1 bit, little-endian, data-type-policy=OVERRIDE, i-signal-type=PRIMITIVE, init-value=0, base-type=BT_HBFS_Status_KiSi, compu {0=Cx0_inaktiv (CM_HBFS_Status_KiSi_Cx0_inaktiv), 1=Cx1_aktiv (CM_HBFS_Status_KiSi_Cx1_aktiv)}, range raw 0..1, transfer-property=PENDING, to SAM(timeout 3.5 s)  # Status Kindersicherung HBFS
            signal HBFS_SleepIndication_XIX_FHSG_HBFSs01_XIX_E3V_SAM_LIN12: start 41, 1 bit, little-endian, data-type-policy=OVERRIDE, i-signal-type=PRIMITIVE, init-value=1, base-type=BT_HBFS_SleepIndication, compu {0=Cx0_keine_Busruhe (CM_HBFS_SleepIndication_Cx0_keine_Busruhe), 1=Cx1_bereit_fuer_Busruhe (CM_HBFS_SleepIndication_Cx1_bereit_fuer_Busruhe)}, range raw 0..1, transfer-property=PENDING, to SAM(timeout 3.5 s)  # Sleep Indication nach Master WakeUp. Default Wert "1".
            signal HBFS_RelaisFehler_XIX_FHSG_HBFSs01_XIX_E3V_SAM_LIN12: start 42, 1 bit, little-endian, data-type-policy=OVERRIDE, i-signal-type=PRIMITIVE, init-value=0, base-type=BT_HBFS_RelaisFehler, compu {0=Cx0_kein_Fehler (CM_HBFS_RelaisFehler_Cx0_kein_Fehler), 1=Cx1_Fehler (CM_HBFS_RelaisFehler_Cx1_Fehler)}, range raw 0..1, transfer-property=PENDING, to SAM(timeout 3.5 s)
            signal HBFS_FH_void_6_XIX_FHSG_HBFSs01_XIX_E3V_SAM_LIN12: start 43, 1 bit, little-endian, data-type-policy=OVERRIDE, i-signal-type=PRIMITIVE, init-value=0, base-type=BT_HBFS_FH_void_6, transfer-property=PENDING  # reserviert
            signal HBFS_FH_void_4_XIX_FHSG_HBFSs01_XIX_E3V_SAM_LIN12: start 44, 4 bit, little-endian, data-type-policy=OVERRIDE, i-signal-type=PRIMITIVE, init-value=0, base-type=BT_HBFS_FH_void_4, transfer-property=PENDING  # reserviert
            signal HBFS_FH_normiert_XIX_FHSG_HBFSs01_XIX_E3V_SAM_LIN12: start 48, 1 bit, little-endian, data-type-policy=OVERRIDE, i-signal-type=PRIMITIVE, init-value=0, base-type=BT_HBFS_FH_normiert, compu {0=Cx0_inaktiv (CM_HBFS_FH_normiert_Cx0_inaktiv), 1=Cx1_aktiv (CM_HBFS_FH_normiert_Cx1_aktiv)}, range raw 0..1, transfer-property=PENDING, to SAM(timeout 3.5 s)  # Die Position der Fensterheberscheibe ist bekannt.
            signal HBFS_FH_Thermo_XIX_FHSG_HBFSs01_XIX_E3V_SAM_LIN12: start 49, 1 bit, little-endian, data-type-policy=OVERRIDE, i-signal-type=PRIMITIVE, init-value=0, base-type=BT_HBFS_FH_Thermo, compu {0=Cx0_inaktiv (CM_HBFS_FH_Thermo_Cx0_inaktiv), 1=Cx1_aktiv (CM_HBFS_FH_Thermo_Cx1_aktiv)}, range raw 0..1, transfer-property=PENDING, to SAM(timeout 3.5 s)  # gibt an ob Fensterheber im Thermoschutz ist
            signal HBFS_FH_Unterspannung_XIX_FHSG_HBFSs01_XIX_E3V_SAM_LIN12: start 50, 1 bit, little-endian, data-type-policy=OVERRIDE, i-signal-type=PRIMITIVE, init-value=0, base-type=BT_HBFS_FH_Unterspannung, invalid-value=Invalid_HBFS_FH_Unterspannung_XIX_FHSG_HBFSs01_XIX_E3V_SAM_LIN12:1, compu {0=Cx0_normal (CM_HBFS_FH_Unterspannung_Cx0_normal), 1=Cx1_Fehler (CM_HBFS_FH_Unterspannung_Cx1_Fehler)}, range raw 0..1, transfer-property=PENDING, to SAM(timeout 3.5 s)
            signal HBFS_FH_Ueberspannung_XIX_FHSG_HBFSs01_XIX_E3V_SAM_LIN12: start 51, 1 bit, little-endian, data-type-policy=OVERRIDE, i-signal-type=PRIMITIVE, init-value=0, base-type=BT_HBFS_FH_Ueberspannung, invalid-value=Invalid_HBFS_FH_Ueberspannung_XIX_FHSG_HBFSs01_XIX_E3V_SAM_LIN12:1, compu {0=Cx0_normal (CM_HBFS_FH_Ueberspannung_Cx0_normal), 1=Cx1_Fehler (CM_HBFS_FH_Ueberspannung_Cx1_Fehler)}, range raw 0..1, transfer-property=PENDING, to SAM(timeout 3.5 s)
            signal HBFS_FH_void_5_XIX_FHSG_HBFSs01_XIX_E3V_SAM_LIN12: start 52, 4 bit, little-endian, data-type-policy=OVERRIDE, i-signal-type=PRIMITIVE, init-value=0, base-type=BT_HBFS_FH_void_5, transfer-property=PENDING  # reserviert
            signal HBFS_Fehler_FH_Schalter_XIX_FHSG_HBFSs01_XIX_E3V_SAM_LIN12: start 56, 1 bit, little-endian, data-type-policy=OVERRIDE, i-signal-type=PRIMITIVE, init-value=0, base-type=BT_HBFS_Fehler_FH_Schalter, invalid-value=Invalid_HBFS_Fehler_FH_Schalter_XIX_FHSG_HBFSs01_XIX_E3V_SAM_LIN12:1, compu {0=Cx0_normal (CM_HBFS_Fehler_FH_Schalter_Cx0_normal), 1=Cx1_Fehler (CM_HBFS_Fehler_FH_Schalter_Cx1_Fehler)}, range raw 0..1, transfer-property=PENDING, to SAM(timeout 3.5 s)
            signal HBFS_Fehler_TIG_TAG_XIX_FHSG_HBFSs01_XIX_E3V_SAM_LIN12: start 57, 1 bit, little-endian, data-type-policy=OVERRIDE, i-signal-type=PRIMITIVE, init-value=0, base-type=BT_HBFS_Fehler_TIG_TAG, invalid-value=Invalid_HBFS_Fehler_TIG_TAG_XIX_FHSG_HBFSs01_XIX_E3V_SAM_LIN12:1, compu {0=Cx0_normal (CM_HBFS_Fehler_TIG_TAG_Cx0_normal), 1=Cx1_Fehler (CM_HBFS_Fehler_TIG_TAG_Cx1_Fehler)}, range raw 0..1, transfer-property=PENDING
            signal HBFS_Fehler_Beleuchtung_XIX_FHSG_HBFSs01_XIX_E3V_SAM_LIN12: start 58, 1 bit, little-endian, data-type-policy=OVERRIDE, i-signal-type=PRIMITIVE, init-value=0, base-type=BT_HBFS_Fehler_Beleuchtung, invalid-value=Invalid_HBFS_Fehler_Beleuchtung_XIX_FHSG_HBFSs01_XIX_E3V_SAM_LIN12:1, compu {0=Cx0_normal (CM_HBFS_Fehler_Beleuchtung_Cx0_normal), 1=Cx1_Fehler (CM_HBFS_Fehler_Beleuchtung_Cx1_Fehler)}, range raw 0..1, transfer-property=PENDING, to SAM(timeout 3.5 s)  # Fehler Schalter-Suchbeleuchtung hinten Beifahrerseite (Klemme 58xs)
            signal HBFS_Fehler_SG_XIX_FHSG_HBFSs01_XIX_E3V_SAM_LIN12: start 59, 1 bit, little-endian, data-type-policy=OVERRIDE, i-signal-type=PRIMITIVE, init-value=0, base-type=BT_HBFS_Fehler_SG, invalid-value=Invalid_HBFS_Fehler_SG_XIX_FHSG_HBFSs01_XIX_E3V_SAM_LIN12:1, compu {0=Cx0_normal (CM_HBFS_Fehler_SG_Cx0_normal), 1=Cx1_Fehler (CM_HBFS_Fehler_SG_Cx1_Fehler)}, range raw 0..1, transfer-property=PENDING, to SAM(timeout 3.5 s)
            signal HBFS_Fehler_Parameter_XIX_FHSG_HBFSs01_XIX_E3V_SAM_LIN12: start 60, 1 bit, little-endian, data-type-policy=OVERRIDE, i-signal-type=PRIMITIVE, init-value=0, base-type=BT_HBFS_Fehler_Parameter, invalid-value=Invalid_HBFS_Fehler_Parameter_XIX_FHSG_HBFSs01_XIX_E3V_SAM_LIN12:1, compu {0=Cx0_normal (CM_HBFS_Fehler_Parameter_Cx0_normal), 1=Cx1_Fehler (CM_HBFS_Fehler_Parameter_Cx1_Fehler)}, range raw 0..1, transfer-property=PENDING, to SAM(timeout 3.5 s)
            signal HBFS_Fehler_Kodierdaten_XIX_FHSG_HBFSs01_XIX_E3V_SAM_LIN12: start 61, 1 bit, little-endian, data-type-policy=OVERRIDE, i-signal-type=PRIMITIVE, init-value=0, base-type=BT_HBFS_Fehler_Kodierdaten, invalid-value=Invalid_HBFS_Fehler_Kodierdaten_XIX_FHSG_HBFSs01_XIX_E3V_SAM_LIN12:1, compu {0=Cx0_normal (CM_HBFS_Fehler_Kodierdaten_Cx0_normal), 1=Cx1_Fehler (CM_HBFS_Fehler_Kodierdaten_Cx1_Fehler)}, range raw 0..1, transfer-property=PENDING, to SAM(timeout 3.5 s)
            signal HBFS_Fehler_Hallsensor_XIX_FHSG_HBFSs01_XIX_E3V_SAM_LIN12: start 62, 1 bit, little-endian, data-type-policy=OVERRIDE, i-signal-type=PRIMITIVE, init-value=0, base-type=BT_HBFS_Fehler_Hallsensor, invalid-value=Invalid_HBFS_Fehler_Hallsensor_XIX_FHSG_HBFSs01_XIX_E3V_SAM_LIN12:1, compu {0=Cx0_normal (CM_HBFS_Fehler_Hallsensor_Cx0_normal), 1=Cx1_Fehler (CM_HBFS_Fehler_Hallsensor_Cx1_Fehler)}, range raw 0..1, transfer-property=PENDING, to SAM(timeout 3.5 s)
            signal HBFS_ResponseError_XIX_FHSG_HBFSs01_XIX_E3V_SAM_LIN12: start 63, 1 bit, little-endian, data-type-policy=OVERRIDE, i-signal-type=PRIMITIVE, init-value=0, base-type=BT_HBFS_ResponseError, invalid-value=Invalid_HBFS_ResponseError_XIX_FHSG_HBFSs01_XIX_E3V_SAM_LIN12:1, compu {0=Cx0_normal (CM_HBFS_ResponseError_Cx0_normal), 1=Cx1_Fehler (CM_HBFS_ResponseError_Cx1_Fehler)}, range raw 0..1, transfer-property=PENDING, to SAM(timeout 3.5 s)  # siehe LIN2.0-Specification (Darf nicht über ein Fehlergueltigkeitsbit abgesichtert werden!)
        frame FHSG_HFSs01_XIX_E3V_SAM_LIN12: id 0x17, to SAM, frame-length=8, lin-checksum=ENHANCED
          pdu FHSG_HFSs01_XIX_E3V_SAM_LIN12: length=8, unused-bit-pattern=0
            signal HFS_FH_S_ManHoch_XIX_FHSG_HFSs01_XIX_E3V_SAM_LIN12: start 0, 1 bit, little-endian, data-type-policy=OVERRIDE, i-signal-type=PRIMITIVE, init-value=0, base-type=BT_HFS_FH_S_ManHoch, compu {0=Cx0_nicht_betaetigt (CM_HFS_FH_S_ManHoch_Cx0_nicht_betaetigt), 1=Cx1_betaetigt (CM_HFS_FH_S_ManHoch_Cx1_betaetigt)}, range raw 0..1, transfer-property=PENDING, to SAM(timeout 3.5 s)  # Betaetigung FH Schalter man hoch
            signal HFS_FH_S_AutoHoch_XIX_FHSG_HFSs01_XIX_E3V_SAM_LIN12: start 1, 1 bit, little-endian, data-type-policy=OVERRIDE, i-signal-type=PRIMITIVE, init-value=0, base-type=BT_HFS_FH_S_AutoHoch, compu {0=Cx0_nicht_betaetigt (CM_HFS_FH_S_AutoHoch_Cx0_nicht_betaetigt), 1=Cx1_betaetigt (CM_HFS_FH_S_AutoHoch_Cx1_betaetigt)}, range raw 0..1, transfer-property=PENDING, to SAM(timeout 3.5 s)  # Betaetigung FH Schalter auto hoch
            signal HFS_FH_S_ManTief_XIX_FHSG_HFSs01_XIX_E3V_SAM_LIN12: start 2, 1 bit, little-endian, data-type-policy=OVERRIDE, i-signal-type=PRIMITIVE, init-value=0, base-type=BT_HFS_FH_S_ManTief, compu {0=Cx0_nicht_betaetigt (CM_HFS_FH_S_ManTief_Cx0_nicht_betaetigt), 1=Cx1_betaetigt (CM_HFS_FH_S_ManTief_Cx1_betaetigt)}, range raw 0..1, transfer-property=PENDING, to SAM(timeout 3.5 s)  # Betaetigung FH Schalter man tief
            signal HFS_FH_S_AutoTief_XIX_FHSG_HFSs01_XIX_E3V_SAM_LIN12: start 3, 1 bit, little-endian, data-type-policy=OVERRIDE, i-signal-type=PRIMITIVE, init-value=0, base-type=BT_HFS_FH_S_AutoTief, compu {0=Cx0_nicht_betaetigt (CM_HFS_FH_S_AutoTief_Cx0_nicht_betaetigt), 1=Cx1_betaetigt (CM_HFS_FH_S_AutoTief_Cx1_betaetigt)}, range raw 0..1, transfer-property=PENDING, to SAM(timeout 3.5 s)  # Betaetigung FH Schalter auto tief
            signal HFS_Status_Routine_XIX_FHSG_HFSs01_XIX_E3V_SAM_LIN12: start 4, 2 bit, little-endian, data-type-policy=OVERRIDE, i-signal-type=PRIMITIVE, init-value=0, base-type=BT_HFS_Status_Routine, compu {0=Cx0_nicht_gestartet (CM_HFS_Status_Routine_Cx0_nicht_gestartet), 1=Cx1_mind_eine_Routine_laueft (CM_HFS_Status_Routine_Cx1_mind_eine_Routine_laueft), 2=Cx2_Abbruch (CM_HFS_Status_Routine_Cx2_Abbruch), 3=Cx3_kann_nicht_beendet_werden (CM_HFS_Status_Routine_Cx3_kann_nicht_beendet_werden)}, range raw 0..3, transfer-property=PENDING, to SAM(timeout 3.5 s)  # Rückmeldung des Status der SG Routinen
            signal HFS_Status_Stellgliedtest_XIX_FHSG_HFSs01_XIX_E3V_SAM_LIN12: start 6, 2 bit, little-endian, data-type-policy=OVERRIDE, i-signal-type=PRIMITIVE, init-value=0, base-type=BT_HFS_Status_Stellgliedtest, compu {0=Cx0_nicht_gestartet (CM_HFS_Status_Stellgliedtest_Cx0_nicht_gestartet), 1=Cx1_mind_ein_SGT_laueft (CM_HFS_Status_Stellgliedtest_Cx1_mind_ein_SGT_laueft), 2=Cx2_Abbruch_wg_Zeit (CM_HFS_Status_Stellgliedtest_Cx2_Abbruch_wg_Zeit), 3=Cx3_Abbruch_wg_Sicherheit (CM_HFS_Status_Stellgliedtest_Cx3_Abbruch_wg_Sicherheit)}, range raw 0..3, transfer-property=PENDING, to SAM(timeout 3.5 s)  # Rückmeldung des Status vom Stellgliedtest
            signal HFS_FH_void_2_XIX_FHSG_HFSs01_XIX_E3V_SAM_LIN12: start 8, 8 bit, little-endian, data-type-policy=OVERRIDE, i-signal-type=PRIMITIVE, init-value=0, base-type=BT_HFS_FH_void_2, transfer-property=PENDING  # reserviert
            signal HFS_TIG_betaetigt_XIX_FHSG_HFSs01_XIX_E3V_SAM_LIN12: start 16, 1 bit, little-endian, data-type-policy=OVERRIDE, i-signal-type=PRIMITIVE, init-value=0, base-type=BT_HFS_TIG_betaetigt, compu {0=Cx0_nicht_betaetigt (CM_HFS_TIG_betaetigt_Cx0_nicht_betaetigt), 1=Cx1_betaetigt (CM_HFS_TIG_betaetigt_Cx1_betaetigt)}, range raw 0..1, transfer-property=PENDING  # Betaetigung Türinnengriff
            signal HFS_TAG_betaetigt_XIX_FHSG_HFSs01_XIX_E3V_SAM_LIN12: start 17, 1 bit, little-endian, data-type-policy=OVERRIDE, i-signal-type=PRIMITIVE, init-value=0, base-type=BT_HFS_TAG_betaetigt, compu {0=Cx0_nicht_betaetigt (CM_HFS_TAG_betaetigt_Cx0_nicht_betaetigt), 1=Cx1_betaetigt (CM_HFS_TAG_betaetigt_Cx1_betaetigt)}, range raw 0..1, transfer-property=PENDING  # Betaetigung Türaussengriff
            signal HFS_FH_void_3_XIX_FHSG_HFSs01_XIX_E3V_SAM_LIN12: start 18, 6 bit, little-endian, data-type-policy=OVERRIDE, i-signal-type=PRIMITIVE, init-value=0, base-type=BT_HFS_FH_void_3, transfer-property=PENDING  # reserviert
            signal HFS_FH_Oeffnung_XIX_FHSG_HFSs01_XIX_E3V_SAM_LIN12: start 24, 8 bit, little-endian, data-type-policy=OVERRIDE, i-signal-type=PRIMITIVE, init-value=0, base-type=BT_HFS_FH_Oeffnung, compu {phys=raw*0.5 for raw 0..200; unit Unit_PerCent}, range phys 0..100 Unit_PerCent, raw 0..200, unit=Unit_PerCent, transfer-property=PENDING, to SAM(timeout 3.5 s)  # Gibt den Fensteröffnungswert in % an.
            signal HFS_FH_Bew_hoch_XIX_FHSG_HFSs01_XIX_E3V_SAM_LIN12: start 32, 1 bit, little-endian, data-type-policy=OVERRIDE, i-signal-type=PRIMITIVE, init-value=0, base-type=BT_HFS_FH_Bew_hoch, compu {0=Cx0_inaktiv (CM_HFS_FH_Bew_hoch_Cx0_inaktiv), 1=Cx1_aktiv (CM_HFS_FH_Bew_hoch_Cx1_aktiv)}, range raw 0..1, transfer-property=PENDING, to SAM(timeout 3.5 s)  # HFS Fenster bewegt sich in Richtung hoch
            signal HFS_FH_Bew_tief_XIX_FHSG_HFSs01_XIX_E3V_SAM_LIN12: start 33, 1 bit, little-endian, data-type-policy=OVERRIDE, i-signal-type=PRIMITIVE, init-value=0, base-type=BT_HFS_FH_Bew_tief, compu {0=Cx0_inaktiv (CM_HFS_FH_Bew_tief_Cx0_inaktiv), 1=Cx1_aktiv (CM_HFS_FH_Bew_tief_Cx1_aktiv)}, range raw 0..1, transfer-property=PENDING, to SAM(timeout 3.5 s)  # HFS Fenster bewegt sich in Richtung tief
            signal HFS_Oben_Block_erw_XIX_FHSG_HFSs01_XIX_E3V_SAM_LIN12: start 34, 1 bit, little-endian, data-type-policy=OVERRIDE, i-signal-type=PRIMITIVE, init-value=0, base-type=BT_HFS_Oben_Block_erw, compu {0=Cx0_Fensterheber_nicht_in_Blockerwar (CM_HFS_Oben_Block_erw_Cx0_Fensterheber_nicht_in_Blockerwar), 1=Cx1_Fensterheber_in_Blockerwartung_o (CM_HFS_Oben_Block_erw_Cx1_Fensterheber_in_Blockerwartung_o)}, range raw 0..1, transfer-property=PENDING, to SAM(timeout 3.5 s)  # Fensterheber in Blockerwartung oben
            signal HFS_Unten_Block_erw_XIX_FHSG_HFSs01_XIX_E3V_SAM_LIN12: start 35, 1 bit, little-endian, data-type-policy=OVERRIDE, i-signal-type=PRIMITIVE, init-value=0, base-type=BT_HFS_Unten_Block_erw, compu {0=Cx0_Fensterheber_nicht_in_Blockerwar (CM_HFS_Unten_Block_erw_Cx0_Fensterheber_nicht_in_Blockerwar), 1=Cx1_Fensterheber_in_Blockerwartung_u (CM_HFS_Unten_Block_erw_Cx1_Fensterheber_in_Blockerwartung_u)}, range raw 0..1, transfer-property=PENDING, to SAM(timeout 3.5 s)  # Fensterheber in Blockerwartung unten
            signal HFS_FH_Block_XIX_FHSG_HFSs01_XIX_E3V_SAM_LIN12: start 36, 1 bit, little-endian, data-type-policy=OVERRIDE, i-signal-type=PRIMITIVE, init-value=0, base-type=BT_HFS_FH_Block, compu {0=Cx0_inaktiv (CM_HFS_FH_Block_Cx0_inaktiv), 1=Cx1_aktiv (CM_HFS_FH_Block_Cx1_aktiv)}, range raw 0..1, transfer-property=PENDING, to SAM(timeout 3.5 s)  # Fensterscheibe befindet sich im mechanischen Block (oben oder unten)
            signal HFS_FH_Fang_XIX_FHSG_HFSs01_XIX_E3V_SAM_LIN12: start 37, 1 bit, little-endian, data-type-policy=OVERRIDE, i-signal-type=PRIMITIVE, init-value=0, base-type=BT_HFS_FH_Fang, compu {0=Cx0_ausserhalb_Fangbereich (CM_HFS_FH_Fang_Cx0_ausserhalb_Fangbereich), 1=Cx1_innerhalb_Fangbereich (CM_HFS_FH_Fang_Cx1_innerhalb_Fangbereich)}, range raw 0..1, transfer-property=PENDING, to SAM(timeout 3.5 s)  # Fangbereich ist 4mm von oberer Lippendichtung
            signal HFS_UEKB_aktiviert_XIX_FHSG_HFSs01_XIX_E3V_SAM_LIN12: start 38, 1 bit, little-endian, data-type-policy=OVERRIDE, i-signal-type=PRIMITIVE, init-value=0, base-type=BT_HFS_UEKB_aktiviert, compu {0=Cx0_inaktiv (CM_HFS_UEKB_aktiviert_Cx0_inaktiv), 1=Cx1_aktiv (CM_HFS_UEKB_aktiviert_Cx1_aktiv)}, range raw 0..1, transfer-property=PENDING, to SAM(timeout 3.5 s)  # Überschutzbegrenzungskraft bei Reversieren
            signal HFS_Fehler_FH_Normierung_XIX_FHSG_HFSs01_XIX_E3V_SAM_LIN12: start 39, 1 bit, little-endian, data-type-policy=OVERRIDE, i-signal-type=PRIMITIVE, init-value=0, base-type=BT_HFS_Fehler_FH_Normierung, invalid-value=Invalid_HFS_Fehler_FH_Normierung_XIX_FHSG_HFSs01_XIX_E3V_SAM_LIN12:1, compu {0=Cx0_kein_Fehler (CM_HFS_Fehler_FH_Normierung_Cx0_kein_Fehler), 1=Cx1_Fehler (CM_HFS_Fehler_FH_Normierung_Cx1_Fehler)}, range raw 0..1, transfer-property=PENDING, to SAM(timeout 3.5 s)  # Normierung Fensterheber hinten Fahrerseite fehlgeschlagen.
            signal HFS_Status_KiSi_XIX_FHSG_HFSs01_XIX_E3V_SAM_LIN12: start 40, 1 bit, little-endian, data-type-policy=OVERRIDE, i-signal-type=PRIMITIVE, init-value=0, base-type=BT_HFS_Status_KiSi, compu {0=Cx0_inaktiv (CM_HFS_Status_KiSi_Cx0_inaktiv), 1=Cx1_aktiv (CM_HFS_Status_KiSi_Cx1_aktiv)}, range raw 0..1, transfer-property=PENDING, to SAM(timeout 3.5 s)  # Status Kindersicherung hinten Fahrerseite
            signal HFS_SleepIndication_XIX_FHSG_HFSs01_XIX_E3V_SAM_LIN12: start 41, 1 bit, little-endian, data-type-policy=OVERRIDE, i-signal-type=PRIMITIVE, init-value=1, base-type=BT_HFS_SleepIndication, compu {0=Cx0_keine_Busruhe (CM_HFS_SleepIndication_Cx0_keine_Busruhe), 1=Cx1_bereit_fuer_Busruhe (CM_HFS_SleepIndication_Cx1_bereit_fuer_Busruhe)}, range raw 0..1, transfer-property=PENDING, to SAM(timeout 3.5 s)  # Sleep Indication nach Master WakeUp. Default Wert "1".
            signal HFS_RelaisFehler_XIX_FHSG_HFSs01_XIX_E3V_SAM_LIN12: start 42, 1 bit, little-endian, data-type-policy=OVERRIDE, i-signal-type=PRIMITIVE, init-value=0, base-type=BT_HFS_RelaisFehler, compu {0=Cx0_kein_Fehler (CM_HFS_RelaisFehler_Cx0_kein_Fehler), 1=Cx1_Fehler (CM_HFS_RelaisFehler_Cx1_Fehler)}, range raw 0..1, transfer-property=PENDING, to SAM(timeout 3.5 s)
            signal HFS_FH_void_6_XIX_FHSG_HFSs01_XIX_E3V_SAM_LIN12: start 43, 1 bit, little-endian, data-type-policy=OVERRIDE, i-signal-type=PRIMITIVE, init-value=0, base-type=BT_HFS_FH_void_6, transfer-property=PENDING  # reserviert
            signal HFS_FH_void_4_XIX_FHSG_HFSs01_XIX_E3V_SAM_LIN12: start 44, 4 bit, little-endian, data-type-policy=OVERRIDE, i-signal-type=PRIMITIVE, init-value=0, base-type=BT_HFS_FH_void_4, transfer-property=PENDING  # reserviert
            signal HFS_FH_normiert_XIX_FHSG_HFSs01_XIX_E3V_SAM_LIN12: start 48, 1 bit, little-endian, data-type-policy=OVERRIDE, i-signal-type=PRIMITIVE, init-value=0, base-type=BT_HFS_FH_normiert, compu {0=Cx0_inaktiv (CM_HFS_FH_normiert_Cx0_inaktiv), 1=Cx1_aktiv (CM_HFS_FH_normiert_Cx1_aktiv)}, range raw 0..1, transfer-property=PENDING, to SAM(timeout 3.5 s)  # Die Position der Fensterheberscheibe ist bekannt.
            signal HFS_FH_Thermo_XIX_FHSG_HFSs01_XIX_E3V_SAM_LIN12: start 49, 1 bit, little-endian, data-type-policy=OVERRIDE, i-signal-type=PRIMITIVE, init-value=0, base-type=BT_HFS_FH_Thermo, compu {0=Cx0_inaktiv (CM_HFS_FH_Thermo_Cx0_inaktiv), 1=Cx1_aktiv (CM_HFS_FH_Thermo_Cx1_aktiv)}, range raw 0..1, transfer-property=PENDING, to SAM(timeout 3.5 s)  # gibt an ob Fensterheber im Thermoschutz ist
            signal HFS_FH_Unterspannung_XIX_FHSG_HFSs01_XIX_E3V_SAM_LIN12: start 50, 1 bit, little-endian, data-type-policy=OVERRIDE, i-signal-type=PRIMITIVE, init-value=0, base-type=BT_HFS_FH_Unterspannung, invalid-value=Invalid_HFS_FH_Unterspannung_XIX_FHSG_HFSs01_XIX_E3V_SAM_LIN12:1, compu {0=Cx0_normal (CM_HFS_FH_Unterspannung_Cx0_normal), 1=Cx1_Fehler (CM_HFS_FH_Unterspannung_Cx1_Fehler)}, range raw 0..1, transfer-property=PENDING, to SAM(timeout 3.5 s)
            signal HFS_FH_Ueberspannung_XIX_FHSG_HFSs01_XIX_E3V_SAM_LIN12: start 51, 1 bit, little-endian, data-type-policy=OVERRIDE, i-signal-type=PRIMITIVE, init-value=0, base-type=BT_HFS_FH_Ueberspannung, invalid-value=Invalid_HFS_FH_Ueberspannung_XIX_FHSG_HFSs01_XIX_E3V_SAM_LIN12:1, compu {0=Cx0_normal (CM_HFS_FH_Ueberspannung_Cx0_normal), 1=Cx1_Fehler (CM_HFS_FH_Ueberspannung_Cx1_Fehler)}, range raw 0..1, transfer-property=PENDING, to SAM(timeout 3.5 s)
            signal HFS_FH_void_5_XIX_FHSG_HFSs01_XIX_E3V_SAM_LIN12: start 52, 4 bit, little-endian, data-type-policy=OVERRIDE, i-signal-type=PRIMITIVE, init-value=0, base-type=BT_HFS_FH_void_5, transfer-property=PENDING  # reserviert
            signal HFS_Fehler_FH_Schalter_XIX_FHSG_HFSs01_XIX_E3V_SAM_LIN12: start 56, 1 bit, little-endian, data-type-policy=OVERRIDE, i-signal-type=PRIMITIVE, init-value=0, base-type=BT_HFS_Fehler_FH_Schalter, invalid-value=Invalid_HFS_Fehler_FH_Schalter_XIX_FHSG_HFSs01_XIX_E3V_SAM_LIN12:1, compu {0=Cx0_normal (CM_HFS_Fehler_FH_Schalter_Cx0_normal), 1=Cx1_Fehler (CM_HFS_Fehler_FH_Schalter_Cx1_Fehler)}, range raw 0..1, transfer-property=PENDING, to SAM(timeout 3.5 s)
            signal HFS_Fehler_TIG_TAG_XIX_FHSG_HFSs01_XIX_E3V_SAM_LIN12: start 57, 1 bit, little-endian, data-type-policy=OVERRIDE, i-signal-type=PRIMITIVE, init-value=0, base-type=BT_HFS_Fehler_TIG_TAG, invalid-value=Invalid_HFS_Fehler_TIG_TAG_XIX_FHSG_HFSs01_XIX_E3V_SAM_LIN12:1, compu {0=Cx0_normal (CM_HFS_Fehler_TIG_TAG_Cx0_normal), 1=Cx1_Fehler (CM_HFS_Fehler_TIG_TAG_Cx1_Fehler)}, range raw 0..1, transfer-property=PENDING
            signal HFS_Fehler_Beleuchtung_XIX_FHSG_HFSs01_XIX_E3V_SAM_LIN12: start 58, 1 bit, little-endian, data-type-policy=OVERRIDE, i-signal-type=PRIMITIVE, init-value=0, base-type=BT_HFS_Fehler_Beleuchtung, invalid-value=Invalid_HFS_Fehler_Beleuchtung_XIX_FHSG_HFSs01_XIX_E3V_SAM_LIN12:1, compu {0=Cx0_normal (CM_HFS_Fehler_Beleuchtung_Cx0_normal), 1=Cx1_Fehler (CM_HFS_Fehler_Beleuchtung_Cx1_Fehler)}, range raw 0..1, transfer-property=PENDING, to SAM(timeout 3.5 s)  # Fehler Schalter-Suchbeleuchtung hinten Fahrerseite (Klemme 58xs)
            signal HFS_Fehler_SG_XIX_FHSG_HFSs01_XIX_E3V_SAM_LIN12: start 59, 1 bit, little-endian, data-type-policy=OVERRIDE, i-signal-type=PRIMITIVE, init-value=0, base-type=BT_HFS_Fehler_SG, invalid-value=Invalid_HFS_Fehler_SG_XIX_FHSG_HFSs01_XIX_E3V_SAM_LIN12:1, compu {0=Cx0_normal (CM_HFS_Fehler_SG_Cx0_normal), 1=Cx1_Fehler (CM_HFS_Fehler_SG_Cx1_Fehler)}, range raw 0..1, transfer-property=PENDING, to SAM(timeout 3.5 s)
            signal HFS_Fehler_Parameter_XIX_FHSG_HFSs01_XIX_E3V_SAM_LIN12: start 60, 1 bit, little-endian, data-type-policy=OVERRIDE, i-signal-type=PRIMITIVE, init-value=0, base-type=BT_HFS_Fehler_Parameter, invalid-value=Invalid_HFS_Fehler_Parameter_XIX_FHSG_HFSs01_XIX_E3V_SAM_LIN12:1, compu {0=Cx0_normal (CM_HFS_Fehler_Parameter_Cx0_normal), 1=Cx1_Fehler (CM_HFS_Fehler_Parameter_Cx1_Fehler)}, range raw 0..1, transfer-property=PENDING, to SAM(timeout 3.5 s)
            signal HFS_Fehler_Kodierdaten_XIX_FHSG_HFSs01_XIX_E3V_SAM_LIN12: start 61, 1 bit, little-endian, data-type-policy=OVERRIDE, i-signal-type=PRIMITIVE, init-value=0, base-type=BT_HFS_Fehler_Kodierdaten, invalid-value=Invalid_HFS_Fehler_Kodierdaten_XIX_FHSG_HFSs01_XIX_E3V_SAM_LIN12:1, compu {0=Cx0_normal (CM_HFS_Fehler_Kodierdaten_Cx0_normal), 1=Cx1_Fehler (CM_HFS_Fehler_Kodierdaten_Cx1_Fehler)}, range raw 0..1, transfer-property=PENDING, to SAM(timeout 3.5 s)
            signal HFS_Fehler_Hallsensor_XIX_FHSG_HFSs01_XIX_E3V_SAM_LIN12: start 62, 1 bit, little-endian, data-type-policy=OVERRIDE, i-signal-type=PRIMITIVE, init-value=0, base-type=BT_HFS_Fehler_Hallsensor, invalid-value=Invalid_HFS_Fehler_Hallsensor_XIX_FHSG_HFSs01_XIX_E3V_SAM_LIN12:1, compu {0=Cx0_normal (CM_HFS_Fehler_Hallsensor_Cx0_normal), 1=Cx1_Fehler (CM_HFS_Fehler_Hallsensor_Cx1_Fehler)}, range raw 0..1, transfer-property=PENDING, to SAM(timeout 3.5 s)
            signal HFS_ResponseError_XIX_FHSG_HFSs01_XIX_E3V_SAM_LIN12: start 63, 1 bit, little-endian, data-type-policy=OVERRIDE, i-signal-type=PRIMITIVE, init-value=0, base-type=BT_HFS_ResponseError, invalid-value=Invalid_HFS_ResponseError_XIX_FHSG_HFSs01_XIX_E3V_SAM_LIN12:1, compu {0=Cx0_normal (CM_HFS_ResponseError_Cx0_normal), 1=Cx1_Fehler (CM_HFS_ResponseError_Cx1_Fehler)}, range raw 0..1, transfer-property=PENDING, to SAM(timeout 3.5 s)  # siehe LIN2.0-Specification (Darf nicht über ein Fehlergueltigkeitsbit abgesichtert werden!)
        frame FHSGe01_XIX_E3V_SAM_LIN12: id 0x14, from SAM, frame-length=8, lin-checksum=ENHANCED
          pdu FHSGe01_XIX_E3V_SAM_LIN12: length=8, unused-bit-pattern=0
            signal FHSG_void_3_XIX_FHSGe01_XIX_E3V_SAM_LIN12: start 0, 8 bit, little-endian, data-type-policy=OVERRIDE, i-signal-type=PRIMITIVE, init-value=0, base-type=BT_FHSG_void_3, transfer-property=PENDING  # reserviert
            signal FHSG_MST_FH_HFS_ManHoch_XIX_FHSGe01_XIX_E3V_SAM_LIN12: start 8, 1 bit, little-endian, data-type-policy=OVERRIDE, i-signal-type=PRIMITIVE, init-value=0, base-type=BT_FHSG_MST_FH_HFS_ManHoch, compu {0=Cx0_nicht_betaetigt (CM_FHSG_MST_FH_HFS_ManHoch_Cx0_nicht_betaetigt), 1=Cx1_betaetigt (CM_FHSG_MST_FH_HFS_ManHoch_Cx1_betaetigt)}, range raw 0..1, transfer-property=PENDING  # Betaetigung FH Schalter man hoch
            signal FHSG_MST_FH_HFS_AutoHoch_XIX_FHSGe01_XIX_E3V_SAM_LIN12: start 9, 1 bit, little-endian, data-type-policy=OVERRIDE, i-signal-type=PRIMITIVE, init-value=0, base-type=BT_FHSG_MST_FH_HFS_AutoHoch, compu {0=Cx0_nicht_betaetigt (CM_FHSG_MST_FH_HFS_AutoHoch_Cx0_nicht_betaetigt), 1=Cx1_betaetigt (CM_FHSG_MST_FH_HFS_AutoHoch_Cx1_betaetigt)}, range raw 0..1, transfer-property=PENDING  # Betaetigung FH Schalter auto hoch
            signal FHSG_MST_FH_HFS_ManTief_XIX_FHSGe01_XIX_E3V_SAM_LIN12: start 10, 1 bit, little-endian, data-type-policy=OVERRIDE, i-signal-type=PRIMITIVE, init-value=0, base-type=BT_FHSG_MST_FH_HFS_ManTief, compu {0=Cx0_nicht_betaetigt (CM_FHSG_MST_FH_HFS_ManTief_Cx0_nicht_betaetigt), 1=Cx1_betaetigt (CM_FHSG_MST_FH_HFS_ManTief_Cx1_betaetigt)}, range raw 0..1, transfer-property=PENDING  # Betaetigung FH Schalter man tief
            signal FHSG_MST_FH_HFS_AutoTief_XIX_FHSGe01_XIX_E3V_SAM_LIN12: start 11, 1 bit, little-endian, data-type-policy=OVERRIDE, i-signal-type=PRIMITIVE, init-value=0, base-type=BT_FHSG_MST_FH_HFS_AutoTief, compu {0=Cx0_nicht_betaetigt (CM_FHSG_MST_FH_HFS_AutoTief_Cx0_nicht_betaetigt), 1=Cx1_betaetigt (CM_FHSG_MST_FH_HFS_AutoTief_Cx1_betaetigt)}, range raw 0..1, transfer-property=PENDING  # Betaetigung FH Schalter auto tief
            signal FHSG_MST_FH_HBFS_ManHoch_XIX_FHSGe01_XIX_E3V_SAM_LIN12: start 12, 1 bit, little-endian, data-type-policy=OVERRIDE, i-signal-type=PRIMITIVE, init-value=0, base-type=BT_FHSG_MST_FH_HBFS_ManHoch, compu {0=Cx0_nicht_betaetigt (CM_FHSG_MST_FH_HBFS_ManHoch_Cx0_nicht_betaetigt), 1=Cx1_betaetigt (CM_FHSG_MST_FH_HBFS_ManHoch_Cx1_betaetigt)}, range raw 0..1, transfer-property=PENDING  # Betaetigung FH Schalter man hoch
            signal FHSG_MST_FH_HBFS_AutoHoch_XIX_FHSGe01_XIX_E3V_SAM_LIN12: start 13, 1 bit, little-endian, data-type-policy=OVERRIDE, i-signal-type=PRIMITIVE, init-value=0, base-type=BT_FHSG_MST_FH_HBFS_AutoHoch, compu {0=Cx0_nicht_betaetigt (CM_FHSG_MST_FH_HBFS_AutoHoch_Cx0_nicht_betaetigt), 1=Cx1_betaetigt (CM_FHSG_MST_FH_HBFS_AutoHoch_Cx1_betaetigt)}, range raw 0..1, transfer-property=PENDING  # Betaetigung FH Schalter auto hoch
            signal FHSG_MST_FH_HBFS_ManTief_XIX_FHSGe01_XIX_E3V_SAM_LIN12: start 14, 1 bit, little-endian, data-type-policy=OVERRIDE, i-signal-type=PRIMITIVE, init-value=0, base-type=BT_FHSG_MST_FH_HBFS_ManTief, compu {0=Cx0_nicht_betaetigt (CM_FHSG_MST_FH_HBFS_ManTief_Cx0_nicht_betaetigt), 1=Cx1_betaetigt (CM_FHSG_MST_FH_HBFS_ManTief_Cx1_betaetigt)}, range raw 0..1, transfer-property=PENDING  # Betaetigung FH Schalter man tief
            signal FHSG_MST_FH_HBFS_AutoTief_XIX_FHSGe01_XIX_E3V_SAM_LIN12: start 15, 1 bit, little-endian, data-type-policy=OVERRIDE, i-signal-type=PRIMITIVE, init-value=0, base-type=BT_FHSG_MST_FH_HBFS_AutoTief, compu {0=Cx0_nicht_betaetigt (CM_FHSG_MST_FH_HBFS_AutoTief_Cx0_nicht_betaetigt), 1=Cx1_betaetigt (CM_FHSG_MST_FH_HBFS_AutoTief_Cx1_betaetigt)}, range raw 0..1, transfer-property=PENDING  # Betaetigung FH Schalter auto tief
            signal FHSG_void_4_XIX_FHSGe01_XIX_E3V_SAM_LIN12: start 16, 2 bit, little-endian, data-type-policy=OVERRIDE, i-signal-type=PRIMITIVE, init-value=0, base-type=BT_FHSG_void_4, transfer-property=PENDING  # reserviert
            signal FHSG_MST_Tuer_HFS_entriegelt_XIX_FHSGe01_XIX_E3V_SAM_LIN12: start 18, 1 bit, little-endian, data-type-policy=OVERRIDE, i-signal-type=PRIMITIVE, init-value=0, base-type=BT_FHSG_MST_Tuer_HFS_entriegelt, compu {0=Cx0_nicht_entriegelt (CM_FHSG_MST_Tuer_HFS_entriegelt_Cx0_nicht_entriegelt), 1=Cx1_entriegelt (CM_FHSG_MST_Tuer_HFS_entriegelt_Cx1_entriegelt)}, range raw 0..1, transfer-property=PENDING
            signal FHSG_MST_Tuer_HBFS_entriegelt_XIX_FHSGe01_XIX_E3V_SAM_LIN12: start 19, 1 bit, little-endian, data-type-policy=OVERRIDE, i-signal-type=PRIMITIVE, init-value=0, base-type=BT_FHSG_MST_Tuer_HBFS_entriegelt, compu {0=Cx0_nicht_entriegelt (CM_FHSG_MST_Tuer_HBFS_entriegelt_Cx0_nicht_entriegelt), 1=Cx1_entriegelt (CM_FHSG_MST_Tuer_HBFS_entriegelt_Cx1_entriegelt)}, range raw 0..1, transfer-property=PENDING
            signal FHSG_MST_FT_FH_H_Kisi_ein_XIX_FHSGe01_XIX_E3V_SAM_LIN12: start 20, 1 bit, little-endian, data-type-policy=OVERRIDE, i-signal-type=PRIMITIVE, init-value=0, base-type=BT_FHSG_MST_FT_FH_H_Kisi_ein, compu {0=Cx0_Sollzustand_KISI_Aus (CM_FHSG_MST_FT_FH_H_Kisi_ein_Cx0_Sollzustand_KISI_Aus), 1=Cx1_Sollzustand_KISI_Ein (CM_FHSG_MST_FT_FH_H_Kisi_ein_Cx1_Sollzustand_KISI_Ein)}, range raw 0..1, transfer-property=PENDING
            signal FHSG_void_5_XIX_FHSGe01_XIX_E3V_SAM_LIN12: start 21, 2 bit, little-endian, data-type-policy=OVERRIDE, i-signal-type=PRIMITIVE, init-value=0, base-type=BT_FHSG_void_5, transfer-property=PENDING  # reserviert
            signal ZAS_Kl_15_XIX_FHSGe01_XIX_E3V_SAM_LIN12: start 23, 1 bit, little-endian, data-type-policy=OVERRIDE, i-signal-type=PRIMITIVE, init-value=0, base-type=BT_ZAS_Kl_15, compu {0=Cx0_aus (CM_ZAS_Kl_15_Cx0_aus), 1=Cx1_ein (CM_ZAS_Kl_15_Cx1_ein)}, range raw 0..1, transfer-property=PENDING  # Klemme 15: Zuendung (SW-Kl.15)
            signal MO_Kl_50_XIX_FHSGe01_XIX_E3V_SAM_LIN12: start 24, 1 bit, little-endian, data-type-policy=OVERRIDE, i-signal-type=PRIMITIVE, init-value=0, base-type=BT_MO_Kl_50, compu {0=Cx0_aus (CM_MO_Kl_50_Cx0_aus), 1=Cx1_KL50_ein_Startausfuehrung_Fahrer (CM_MO_Kl_50_Cx1_KL50_ein_Startausfuehrung_Fahrer)}, range raw 0..1, transfer-property=PENDING  # Klemme 50: Startausführung durch Ritzelstarter MLB: nicht von allen Motoren gesendet MQB/MLBevo: gesendet von allen Motoren
            signal ZAS_Kl_S_XIX_FHSGe01_XIX_E3V_SAM_LIN12: start 25, 1 bit, little-endian, data-type-policy=OVERRIDE, i-signal-type=PRIMITIVE, init-value=0, base-type=BT_ZAS_Kl_S, compu {0=Cx0_aus (CM_ZAS_Kl_S_Cx0_aus), 1=Cx1_S_Kontakt_ein (CM_ZAS_Kl_S_Cx1_S_Kontakt_ein)}, range raw 0..1, transfer-property=PENDING  # Klemme S: S-Kontakt (Schluessel steckt)
            signal MO_Kl_75_XIX_FHSGe01_XIX_E3V_SAM_LIN12: start 26, 1 bit, little-endian, data-type-policy=OVERRIDE, i-signal-type=PRIMITIVE, init-value=0, base-type=BT_MO_Kl_75, compu {0=Cx0_Aus (CM_MO_Kl_75_Cx0_Aus), 1=Cx1_Ein (CM_MO_Kl_75_Cx1_Ein)}, range raw 0..1, transfer-property=PENDING  # Klemme X
            signal BCM_FH_Freigabe_XIX_FHSGe01_XIX_E3V_SAM_LIN12: start 27, 1 bit, little-endian, data-type-policy=OVERRIDE, i-signal-type=PRIMITIVE, init-value=0, base-type=BT_BCM_FH_Freigabe, compu {1=Cx1_Funktionsfreigabe_Fensterheber (CM_BCM_FH_Freigabe_Cx1_Funktionsfreigabe_Fensterheber) (Funktionsfreigabe Fensterheber)}, range raw 1, transfer-property=PENDING  # Funktionsfreigabe Fensterheber
            signal BCM_Komfortfkt_Freigabe_XIX_FHSGe01_XIX_E3V_SAM_LIN12: start 28, 1 bit, little-endian, data-type-policy=OVERRIDE, i-signal-type=PRIMITIVE, init-value=0, base-type=BT_BCM_Komfortfkt_Freigabe, compu {0=Cx0_Komfortfunktion_gesperrt (CM_BCM_Komfortfkt_Freigabe_Cx0_Komfortfunktion_gesperrt) (Komfortfunktion gesperrt), 1=Cx1_globale_Freigabe_der_Komfortfunktion_erteilt (CM_BCM_Komfortfkt_Freigabe_Cx1_globale_Freigabe_der_Komfortfunktion_erteilt) (globale Freigabe der Komfortfunktion erteilt)}, range raw 0..1, transfer-property=PENDING  # globale Freigabe der Komfortfunktion
            signal FHSG_MST_FH_Kurzhub_oeffnen_FT_XIX_FHSGe01_XIX_E3V_SAM_LIN12: start 29, 1 bit, little-endian, data-type-policy=OVERRIDE, i-signal-type=PRIMITIVE, init-value=0, base-type=BT_FHSG_MST_FH_Kurzhub_oeffnen_FT, compu {0=Cx0_neutral (CM_FHSG_MST_FH_Kurzhub_oeffnen_FT_Cx0_neutral), 1=Cx1_senken (CM_FHSG_MST_FH_Kurzhub_oeffnen_FT_Cx1_senken)}, range raw 0..1, transfer-property=PENDING
            signal FHSG_MST_FH_Kurzhub_oeffnen_BT_XIX_FHSGe01_XIX_E3V_SAM_LIN12: start 30, 1 bit, little-endian, data-type-policy=OVERRIDE, i-signal-type=PRIMITIVE, init-value=0, base-type=BT_FHSG_MST_FH_Kurzhub_oeffnen_BT, compu {0=Cx0_neutral (CM_FHSG_MST_FH_Kurzhub_oeffnen_BT_Cx0_neutral), 1=Cx1_senken (CM_FHSG_MST_FH_Kurzhub_oeffnen_BT_Cx1_senken)}, range raw 0..1, transfer-property=PENDING
            signal FHSG_MST_FH_Kurzhub_oeffnen_HFS_XIX_FHSGe01_XIX_E3V_SAM_LIN12: start 31, 1 bit, little-endian, data-type-policy=OVERRIDE, i-signal-type=PRIMITIVE, init-value=0, base-type=BT_FHSG_MST_FH_Kurzhub_oeffnen_HFS, compu {0=Cx0_neutral (CM_FHSG_MST_FH_Kurzhub_oeffnen_HFS_Cx0_neutral), 1=Cx1_senken (CM_FHSG_MST_FH_Kurzhub_oeffnen_HFS_Cx1_senken)}, range raw 0..1, transfer-property=PENDING
            signal FHSG_MST_FH_Kurzhub_oeffnen_HBFS_XIX_FHSGe01_XIX_E3V_SAM_LIN12: start 32, 1 bit, little-endian, data-type-policy=OVERRIDE, i-signal-type=PRIMITIVE, init-value=0, base-type=BT_FHSG_MST_FH_Kurzhub_oeffnen_HBFS, compu {0=Cx0_neutral (CM_FHSG_MST_FH_Kurzhub_oeffnen_HBFS_Cx0_neutral), 1=Cx1_senken (CM_FHSG_MST_FH_Kurzhub_oeffnen_HBFS_Cx1_senken)}, range raw 0..1, transfer-property=PENDING
            signal FHSG_void_6_XIX_FHSGe01_XIX_E3V_SAM_LIN12: start 33, 2 bit, little-endian, data-type-policy=OVERRIDE, i-signal-type=PRIMITIVE, init-value=0, base-type=BT_FHSG_void_6, transfer-property=PENDING  # reserviert
            signal FHSG_MST_FH_Langhub_XIX_FHSGe01_XIX_E3V_SAM_LIN12: start 35, 1 bit, little-endian, data-type-policy=OVERRIDE, i-signal-type=PRIMITIVE, init-value=0, base-type=BT_FHSG_MST_FH_Langhub, compu {0=Cx0_neutral (CM_FHSG_MST_FH_Langhub_Cx0_neutral), 1=Cx1_senken (CM_FHSG_MST_FH_Langhub_Cx1_senken)}, range raw 0..1, transfer-property=PENDING
            signal FHSG_MST_FH_KomfortHoch_XIX_FHSGe01_XIX_E3V_SAM_LIN12: start 36, 1 bit, little-endian, data-type-policy=OVERRIDE, i-signal-type=PRIMITIVE, init-value=0, base-type=BT_FHSG_MST_FH_KomfortHoch, compu {0=Cx0_nicht_betaetigt (CM_FHSG_MST_FH_KomfortHoch_Cx0_nicht_betaetigt), 1=Cx1_betaetigt (CM_FHSG_MST_FH_KomfortHoch_Cx1_betaetigt)}, range raw 0..1, transfer-property=PENDING
            signal FHSG_MST_FH_Komforttief_XIX_FHSGe01_XIX_E3V_SAM_LIN12: start 37, 1 bit, little-endian, data-type-policy=OVERRIDE, i-signal-type=PRIMITIVE, init-value=0, base-type=BT_FHSG_MST_FH_Komforttief, compu {0=Cx0_nicht_betaetigt (CM_FHSG_MST_FH_Komforttief_Cx0_nicht_betaetigt), 1=Cx1_betaetigt (CM_FHSG_MST_FH_Komforttief_Cx1_betaetigt)}, range raw 0..1, transfer-property=PENDING
            signal FHSG_void_1_XIX_FHSGe01_XIX_E3V_SAM_LIN12: start 38, 4 bit, little-endian, data-type-policy=OVERRIDE, i-signal-type=PRIMITIVE, init-value=0, base-type=BT_FHSG_void_1, transfer-property=PENDING  # reserviert
            signal FHSG_MST_Lenkigkeit_XIX_FHSGe01_XIX_E3V_SAM_LIN12: start 42, 1 bit, little-endian, data-type-policy=OVERRIDE, i-signal-type=PRIMITIVE, init-value=1, base-type=BT_FHSG_MST_Lenkigkeit, compu {0=Cx0_Rechtslenker (CM_FHSG_MST_Lenkigkeit_Cx0_Rechtslenker), 1=Cx1_Linkslenker (CM_FHSG_MST_Lenkigkeit_Cx1_Linkslenker)}, range raw 0..1, transfer-property=PENDING  # Information für die hinteren FHSG über Rechtslenker/Linkslenker. Die FHSG nutzen den Signal für ihre Verbauorterkennung (hinten Fahrerseite/Beifahrerseite).
            signal MO_StartStopp_Wiederstart_XIX_FHSGe01_XIX_E3V_SAM_LIN12: start 43, 1 bit, little-endian, data-type-policy=OVERRIDE, i-signal-type=PRIMITIVE, init-value=0, base-type=BT_MO_StartStopp_Wiederstart, compu {0=Cx0_Wiederstart_inaktiv (CM_MO_StartStopp_Wiederstart_Cx0_Wiederstart_inaktiv), 1=Cx1_Wiederstart_aktiv (CM_MO_StartStopp_Wiederstart_Cx1_Wiederstart_aktiv)}, range raw 0..1, transfer-property=PENDING  # Motorwiederstart durch Start/Stopp-Koordinator HYBRID: Wenn MO_Hybridfahrzeug =1 gilt: Warnung vor Spannungseinbruch beim Zustart des Verbrennungsmotors. -nicht relevant, da derzeit kein Start über 12V-Starter geplant- Dieses Signal wird nur vom Hybrid-Koordintor gesetzt, wenn durch den Wiederstart ein Spannungseinbruch zu erwarten ist
            signal FHSG_MST_Crashfall_erkannt_XIX_FHSGe01_XIX_E3V_SAM_LIN12: start 44, 1 bit, little-endian, data-type-policy=OVERRIDE, i-signal-type=PRIMITIVE, init-value=0, base-type=BT_FHSG_MST_Crashfall_erkannt, compu {0=Cx0_kein_Crashfall_erkannt (CM_FHSG_MST_Crashfall_erkannt_Cx0_kein_Crashfall_erkannt), 1=Cx1_Crashfall_erkannt (CM_FHSG_MST_Crashfall_erkannt_Cx1_Crashfall_erkannt)}, range raw 0..1, transfer-property=PENDING
            signal FHSG_MST_Precrash_XIX_FHSGe01_XIX_E3V_SAM_LIN12: start 45, 1 bit, little-endian, data-type-policy=OVERRIDE, i-signal-type=PRIMITIVE, init-value=0, base-type=BT_FHSG_MST_Precrash, compu {0=Cx0_inaktiv (CM_FHSG_MST_Precrash_Cx0_inaktiv), 1=Cx1_aktiv (CM_FHSG_MST_Precrash_Cx1_aktiv)}, range raw 0..1, transfer-property=PENDING
            signal FHSG_MST_Drehfalle_vorne_FA_XIX_FHSGe01_XIX_E3V_SAM_LIN12: start 46, 1 bit, little-endian, data-type-policy=OVERRIDE, i-signal-type=PRIMITIVE, init-value=0, base-type=BT_FHSG_MST_Drehfalle_vorne_FA, compu {0=Cx0_geschlossen (CM_FHSG_MST_Drehfalle_vorne_FA_Cx0_geschlossen), 1=Cx1_offen (CM_FHSG_MST_Drehfalle_vorne_FA_Cx1_offen)}, range raw 0..1, transfer-property=PENDING
            signal FHSG_MST_Drehfalle_vorne_BF_XIX_FHSGe01_XIX_E3V_SAM_LIN12: start 47, 1 bit, little-endian, data-type-policy=OVERRIDE, i-signal-type=PRIMITIVE, init-value=0, base-type=BT_FHSG_MST_Drehfalle_vorne_BF, compu {0=Cx0_geschlossen (CM_FHSG_MST_Drehfalle_vorne_BF_Cx0_geschlossen), 1=Cx1_offen (CM_FHSG_MST_Drehfalle_vorne_BF_Cx1_offen)}, range raw 0..1, transfer-property=PENDING
            signal FHSG_MST_FT_Blockerwartung_XIX_FHSGe01_XIX_E3V_SAM_LIN12: start 48, 1 bit, little-endian, data-type-policy=OVERRIDE, i-signal-type=PRIMITIVE, init-value=0, base-type=BT_FHSG_MST_FT_Blockerwartung, compu {0=Cx0_inaktiv (CM_FHSG_MST_FT_Blockerwartung_Cx0_inaktiv), 1=Cx1_aktiv (CM_FHSG_MST_FT_Blockerwartung_Cx1_aktiv)}, range raw 0..1, transfer-property=PENDING  # Fensterheber in Blockerwartung
            signal FHSG_MST_BT_Blockerwartung_XIX_FHSGe01_XIX_E3V_SAM_LIN12: start 49, 1 bit, little-endian, data-type-policy=OVERRIDE, i-signal-type=PRIMITIVE, init-value=0, base-type=BT_FHSG_MST_BT_Blockerwartung, compu {0=Cx0_inaktiv (CM_FHSG_MST_BT_Blockerwartung_Cx0_inaktiv), 1=Cx1_aktiv (CM_FHSG_MST_BT_Blockerwartung_Cx1_aktiv)}, range raw 0..1, transfer-property=PENDING  # Fensterheber in Blockerwartung
            signal FHSG_MST_HFS_Blockerwartung_XIX_FHSGe01_XIX_E3V_SAM_LIN12: start 50, 1 bit, little-endian, data-type-policy=OVERRIDE, i-signal-type=PRIMITIVE, init-value=0, base-type=BT_FHSG_MST_HFS_Blockerwartung, compu {0=Cx0_inaktiv (CM_FHSG_MST_HFS_Blockerwartung_Cx0_inaktiv), 1=Cx1_aktiv (CM_FHSG_MST_HFS_Blockerwartung_Cx1_aktiv)}, range raw 0..1, transfer-property=PENDING  # Fensterheber in Blockerwartung
            signal FHSG_MST_HBFS_Blockerwartung_XIX_FHSGe01_XIX_E3V_SAM_LIN12: start 51, 1 bit, little-endian, data-type-policy=OVERRIDE, i-signal-type=PRIMITIVE, init-value=0, base-type=BT_FHSG_MST_HBFS_Blockerwartung, compu {0=Cx0_inaktiv (CM_FHSG_MST_HBFS_Blockerwartung_Cx0_inaktiv), 1=Cx1_aktiv (CM_FHSG_MST_HBFS_Blockerwartung_Cx1_aktiv)}, range raw 0..1, transfer-property=PENDING  # Fensterheber in Blockerwartung
            signal FHSG_void_8_XIX_FHSGe01_XIX_E3V_SAM_LIN12: start 52, 1 bit, little-endian, data-type-policy=OVERRIDE, i-signal-type=PRIMITIVE, init-value=0, base-type=BT_FHSG_void_8, transfer-property=PENDING  # reserviert
            signal FHSG_MST_Architektur_XIX_FHSGe01_XIX_E3V_SAM_LIN12: start 53, 1 bit, little-endian, data-type-policy=OVERRIDE, i-signal-type=PRIMITIVE, init-value=0, base-type=BT_FHSG_MST_Architektur, compu {0=Cx0_LIN_Master_TSG (CM_FHSG_MST_Architektur_Cx0_LIN_Master_TSG), 1=Cx1_LIN_Master_BCM (CM_FHSG_MST_Architektur_Cx1_LIN_Master_BCM)}, range raw 0..1, transfer-property=PENDING  # Information für die hinteren FHSG über die Fahrzeugarchitektur. Die FHSG nutzen den Signal für ihre Verbauorterkennung (hinten Fahrerseite/Beifahrerseite).
            signal FHSG_void_7_XIX_FHSGe01_XIX_E3V_SAM_LIN12: start 54, 2 bit, little-endian, data-type-policy=OVERRIDE, i-signal-type=PRIMITIVE, init-value=0, base-type=BT_FHSG_void_7, transfer-property=PENDING  # reserviert
            signal FHSG_MST_Aussentemp_ungefiltert_XIX_FHSGe01_XIX_E3V_SAM_LIN12: start 56, 8 bit, little-endian, data-type-policy=OVERRIDE, i-signal-type=PRIMITIVE, init-value=254, base-type=BT_FHSG_MST_Aussentemp_ungefiltert, invalid-value=Invalid_FHSG_MST_Aussentemp_ungefiltert_XIX_FHSGe01_XIX_E3V_SAM_LIN12:255, compu {phys=raw*0.5-50 for raw 0..252, 253=Cxfd_nicht_verbaut (CM_FHSG_MST_Aussentemp_ungefiltert_Cxfd_nicht_verbaut), 254=Cxfe_Init (CM_FHSG_MST_Aussentemp_ungefiltert_Cxfe_Init), 255=Cxff_Fehler (CM_FHSG_MST_Aussentemp_ungefiltert_Cxff_Fehler); unit Unit_DegreCelsi}, range phys -50..76 Unit_DegreCelsi, raw 0..255, unit=Unit_DegreCelsi, transfer-property=PENDING
        frame MasterReq_XIX_E3V_SAM_LIN12: id 0x3C, from SAM, frame-length=8, lin-checksum=CLASSIC
          n pdu MasterReq_XIX_E3V_SAM_LIN12: length=8
        frame SlaveResp_XIX_E3V_SAM_LIN12: id 0x3D, to SAM, frame-length=8, lin-checksum=CLASSIC
          n pdu SlaveResp_XIX_E3V_SAM_LIN12: length=8
        frame TSG_FHe01_XIX_E3V_SAM_LIN12: id 0x4, from SAM, frame-length=8, lin-checksum=ENHANCED
          pdu TSG_FHe01_XIX_E3V_SAM_LIN12: length=8, unused-bit-pattern=0
            signal TSG_FHe01_void1_XIX_TSG_FHe01_XIX_E3V_SAM_LIN12: start 0, 1 bit, little-endian, data-type-policy=OVERRIDE, i-signal-type=PRIMITIVE, init-value=0, base-type=BT_TSG_FHe01_void1, transfer-property=PENDING  # reserviert
            signal MF_Innenraumbel_Unterdrueck_XIX_TSG_FHe01_XIX_E3V_SAM_LIN12: start 1, 1 bit, little-endian, data-type-policy=OVERRIDE, i-signal-type=PRIMITIVE, init-value=0, base-type=BT_MF_Innenraumbel_Unterdrueck, compu {0=Cx0_inaktiv (CM_MF_Innenraumbel_Unterdrueck_Cx0_inaktiv), 1=Cx1_aktiv (CM_MF_Innenraumbel_Unterdrueck_Cx1_aktiv)}, range raw 0..1, transfer-property=PENDING  # Unterdrückung des Innenlichts/Fussraumbeleuchtung, sowie Schließblinken
            signal BEM_02_Abschaltstufen_XIX_TSG_FHe01_XIX_E3V_SAM_LIN12: start 2, 3 bit, little-endian, data-type-policy=OVERRIDE, i-signal-type=PRIMITIVE, init-value=0, base-type=BT_BEM_02_Abschaltstufen, compu {0=Cx0_Stufe_0_keine_Einschraenkungen (CM_BEM_02_Abschaltstufen_Cx0_Stufe_0_keine_Einschraenkungen) (Stufe 0 (keine Einschraenkungen)), 1=Cx1_Stufe_1 (CM_BEM_02_Abschaltstufen_Cx1_Stufe_1) (Stufe 1), 2=Cx2_Stufe_2 (CM_BEM_02_Abschaltstufen_Cx2_Stufe_2) (Stufe 2), 3=Cx3_Stufe_3 (CM_BEM_02_Abschaltstufen_Cx3_Stufe_3) (Stufe 3), 4=Cx4_Transportmodus (CM_BEM_02_Abschaltstufen_Cx4_Transportmodus), 7=Cx7_Ruhestrommessmodus (CM_BEM_02_Abschaltstufen_Cx7_Ruhestrommessmodus)}, range raw 0..7, transfer-property=PENDING  # Abschaltstufen des Ruhestrommanagements (Initialisierungswert aus EEprom) Stufe 0 (keine Einschraenkungen) Stufe 1 (Abschaltung Hochstromverbraucher) Stufe 2 (Infotainmentabschaltung) Stufe 3 (Wake-Up-Sperre) Für den Transport- und Ruhestrommessmodus sind die Werte aus der Systeminfo-Botschaft zu verwenden. Hier sind diese Werte 4 und 7 nur noch für folgende Fahrzeuge umgesetzt: MLB, C6, Q7
            signal MO_StartStopp_Wiederstart_XIX_TSG_FHe01_XIX_E3V_SAM_LIN12: start 5, 1 bit, little-endian, data-type-policy=OVERRIDE, i-signal-type=PRIMITIVE, init-value=0, base-type=BT_MO_StartStopp_Wiederstart, compu {0=Cx0_Wiederstart_inaktiv (CM_MO_StartStopp_Wiederstart_Cx0_Wiederstart_inaktiv), 1=Cx1_Wiederstart_aktiv (CM_MO_StartStopp_Wiederstart_Cx1_Wiederstart_aktiv)}, range raw 0..1, transfer-property=PENDING  # Motorwiederstart durch Start/Stopp-Koordinator HYBRID: Wenn MO_Hybridfahrzeug =1 gilt: Warnung vor Spannungseinbruch beim Zustart des Verbrennungsmotors. -nicht relevant, da derzeit kein Start über 12V-Starter geplant- Dieses Signal wird nur vom Hybrid-Koordintor gesetzt, wenn durch den Wiederstart ein Spannungseinbruch zu erwarten ist
            signal TSG_FHSG_MST_VSG_H_hoch_XIX_TSG_FHe01_XIX_E3V_SAM_LIN12: start 6, 1 bit, little-endian, data-type-policy=OVERRIDE, i-signal-type=PRIMITIVE, init-value=0, base-type=BT_TSG_FHSG_MST_VSG_H_hoch, compu {0=Cx0_inaktiv (CM_TSG_FHSG_MST_VSG_H_hoch_Cx0_inaktiv), 1=Cx1_aktiv (CM_TSG_FHSG_MST_VSG_H_hoch_Cx1_aktiv)}, range raw 0..1, transfer-property=PENDING
            signal TSG_FHSG_MST_VSG_H_tief_XIX_TSG_FHe01_XIX_E3V_SAM_LIN12: start 7, 1 bit, little-endian, data-type-policy=OVERRIDE, i-signal-type=PRIMITIVE, init-value=0, base-type=BT_TSG_FHSG_MST_VSG_H_tief, compu {0=Cx0_inaktiv (CM_TSG_FHSG_MST_VSG_H_tief_Cx0_inaktiv), 1=Cx1_aktiv (CM_TSG_FHSG_MST_VSG_H_tief_Cx1_aktiv)}, range raw 0..1, transfer-property=PENDING  # Anforderung des VSG alle Fenster nach unten zu bewegen
            signal ESP_v_Signal_XIX_TSG_FHe01_XIX_E3V_SAM_LIN12: start 8, 16 bit, little-endian, data-type-policy=OVERRIDE, i-signal-type=PRIMITIVE, init-value=65534, base-type=BT_ESP_v_Signal, invalid-value=Invalid_ESP_v_Signal_XIX_TSG_FHe01_XIX_E3V_SAM_LIN12:65535, compu {phys=raw*0.01 for raw 0..65532, 65533=Cxfffd_Unterspannung (CM_ESP_v_Signal_Cxfffd_Unterspannung), 65534=Cxfffe_Init (CM_ESP_v_Signal_Cxfffe_Init), 65535=Cxffff_Fehler (CM_ESP_v_Signal_Cxffff_Fehler); unit Unit_KiloMeterPerHour}, range phys 0..655.32 Unit_KiloMeterPerHour, raw 0..65535, unit=Unit_KiloMeterPerHour, transfer-property=PENDING  # Geschwindigkeitssignal vom ABS/ASR oder ESP. Mittelwert der angetriebenen Räder. Bei MSR oder ABS Eingriffen wird die ABS-Referenzgeschwindigkeit für >= 200ms eingespiegelt (Zeit wird mit Aktiv-Flanke der Funktionsbits getriggert) MQB: Bei Frontantrieb und gesteuertem Allrad (Haldex) Mittelwert der Vorderräder.
            signal BCM1_Aussen_Temp_ungef_XIX_TSG_FHe01_XIX_E3V_SAM_LIN12: start 24, 8 bit, little-endian, data-type-policy=OVERRIDE, i-signal-type=PRIMITIVE, init-value=254, base-type=BT_BCM1_Aussen_Temp_ungef, invalid-value=Invalid_BCM1_Aussen_Temp_ungef_XIX_TSG_FHe01_XIX_E3V_SAM_LIN12:255, compu {phys=raw*0.5-50 for raw 0..252, 253=Cxfd_nicht_verbaut (CM_BCM1_Aussen_Temp_ungef_Cxfd_nicht_verbaut), 254=Cxfe_Initwert (CM_BCM1_Aussen_Temp_ungef_Cxfe_Initwert), 255=Cxff_Fehler (CM_BCM1_Aussen_Temp_ungef_Cxff_Fehler); unit Unit_DegreCelsi}, range phys -50..76 Unit_DegreCelsi, raw 0..255, unit=Unit_DegreCelsi, transfer-property=PENDING  # ungefilterter Wert des Aussentemperatursensors
            signal DI_KL_58xd_XIX_TSG_FHe01_XIX_E3V_SAM_LIN12: start 32, 8 bit, little-endian, data-type-policy=OVERRIDE, i-signal-type=PRIMITIVE, init-value=254, base-type=BT_DI_KL_58xd, invalid-value=Invalid_DI_KL_58xd_XIX_TSG_FHe01_XIX_E3V_SAM_LIN12:255, compu {phys=raw for raw 0..253, 254=Cxfe_Init (CM_DI_KL_58xd_Cxfe_Init), 255=Cxff_Fehler (CM_DI_KL_58xd_Cxff_Fehler)}, range phys 0..253, raw 0..255, transfer-property=PENDING  # Klemme 58xd Display- und Funktionsbeleuchtung Mit der Klemme 58xd wird die Helligkeit der Display- und der Funktionsbeleuchtungen der Schalter gesteuert. Im Detail beschrieben im 'Funktionslastenheft Dimmung MQB'.
            signal DI_KL_58xs_XIX_TSG_FHe01_XIX_E3V_SAM_LIN12: start 40, 7 bit, little-endian, data-type-policy=OVERRIDE, i-signal-type=PRIMITIVE, init-value=126, base-type=BT_DI_KL_58xs, invalid-value=Invalid_DI_KL_58xs_XIX_TSG_FHe01_XIX_E3V_SAM_LIN12:127, compu {phys=raw for raw 0..100, 126=Cx7e_Init (CM_DI_KL_58xs_Cx7e_Init), 127=Cx7f_Fehler (CM_DI_KL_58xs_Cx7f_Fehler); unit Unit_PerCent}, range phys 0..100 Unit_PerCent, raw 0..127, unit=Unit_PerCent, transfer-property=PENDING  # Suchbeleuchtung Schalter EIN-AUS-Schaltalgorithmus der allgemeinen Schaltersuchbeleuchtung. Im Detail beschrieben im 'Funktionslastenheft Dimmung MQB'.
            signal FHSG_MST_HFS_gesafet_XIX_TSG_FHe01_XIX_E3V_SAM_LIN12: start 47, 1 bit, little-endian, data-type-policy=OVERRIDE, i-signal-type=PRIMITIVE, init-value=0, base-type=BT_FHSG_MST_HFS_gesafet, compu {0=Cx0_nicht_gesafet (CM_FHSG_MST_HFS_gesafet_Cx0_nicht_gesafet), 1=Cx1_gesafet (CM_FHSG_MST_HFS_gesafet_Cx1_gesafet)}, range raw 0..1, transfer-property=PENDING  # HFS Tuer gesafet. Im Zustand Safe wird auch das Signal HFS_verriegelt = 1 gesendet.
            signal DI_KL_58xt_XIX_TSG_FHe01_XIX_E3V_SAM_LIN12: start 48, 7 bit, little-endian, data-type-policy=OVERRIDE, i-signal-type=PRIMITIVE, init-value=126, base-type=BT_DI_KL_58xt, invalid-value=Invalid_DI_KL_58xt_XIX_TSG_FHe01_XIX_E3V_SAM_LIN12:127, compu {phys=raw for raw 0..100, 126=Cx7e_Init (CM_DI_KL_58xt_Cx7e_Init), 127=Cx7f_Fehler (CM_DI_KL_58xt_Cx7f_Fehler); unit Unit_PerCent}, range phys 0..100 Unit_PerCent, raw 0..127, unit=Unit_PerCent, transfer-property=PENDING  # Timergesteuerte Suchbeleuchtung Der EIN-AUS-Schaltalgorithmus für die vor- und nachlaufende Schaltersuchbeleuchtungen beim Ein- & Aussteigen; z.B.: Start/Stop-Taster. Im Detail beschrieben im 'Funktionslastenheft Dimmung MQB'.
            signal FHSG_MST_HBFS_gesafet_XIX_TSG_FHe01_XIX_E3V_SAM_LIN12: start 55, 1 bit, little-endian, data-type-policy=OVERRIDE, i-signal-type=PRIMITIVE, init-value=0, base-type=BT_FHSG_MST_HBFS_gesafet, compu {0=Cx0_nicht_gesafet (CM_FHSG_MST_HBFS_gesafet_Cx0_nicht_gesafet), 1=Cx1_gesafet (CM_FHSG_MST_HBFS_gesafet_Cx1_gesafet)}, range raw 0..1, transfer-property=PENDING  # HBFS Tuer gesafet. Im Zustand Safe wird auch das Signal HBFS_verriegelt = 1 gesendet.
            signal FHSG_MST_Drehfalle_hinten_FA_XIX_TSG_FHe01_XIX_E3V_SAM_LIN12: start 56, 1 bit, little-endian, data-type-policy=OVERRIDE, i-signal-type=PRIMITIVE, init-value=0, base-type=BT_FHSG_MST_Drehfalle_hinten_FA, compu {0=Cx0_geschlossen (CM_FHSG_MST_Drehfalle_hinten_FA_Cx0_geschlossen), 1=Cx1_offen (CM_FHSG_MST_Drehfalle_hinten_FA_Cx1_offen)}, range raw 0..1, transfer-property=PENDING
            signal FHSG_MST_Drehfalle_hinten_BF_XIX_TSG_FHe01_XIX_E3V_SAM_LIN12: start 57, 1 bit, little-endian, data-type-policy=OVERRIDE, i-signal-type=PRIMITIVE, init-value=0, base-type=BT_FHSG_MST_Drehfalle_hinten_BF, compu {0=Cx0_geschlossen (CM_FHSG_MST_Drehfalle_hinten_BF_Cx0_geschlossen), 1=Cx1_offen (CM_FHSG_MST_Drehfalle_hinten_BF_Cx1_offen)}, range raw 0..1, transfer-property=PENDING
            signal TSG_FHSG_void_1_XIX_TSG_FHe01_XIX_E3V_SAM_LIN12: start 58, 3 bit, little-endian, data-type-policy=OVERRIDE, i-signal-type=PRIMITIVE, init-value=0, base-type=BT_TSG_FHSG_void_1, transfer-property=PENDING  # reserviert
            signal BCM_P_Mode_FH_Kl15_aus_aktiv_XIX_TSG_FHe01_XIX_E3V_SAM_LIN12: start 61, 1 bit, little-endian, data-type-policy=OVERRIDE, i-signal-type=PRIMITIVE, init-value=0, base-type=BT_BCM_P_Mode_FH_Kl15_aus_aktiv, compu {0=Cx0_inaktiv (CM_BCM_P_Mode_FH_Kl15_aus_aktiv_Cx0_inaktiv), 1=Cx1_aktiv (CM_BCM_P_Mode_FH_Kl15_aus_aktiv_Cx1_aktiv)}, range raw 0..1, transfer-property=PENDING  # Aktivierung Fensterheberbetätigung bei Kl. 15 aus unabhängig von Türstellung
            signal BCM_P_Mode_FH_Reversierschwelle_XIX_TSG_FHe01_XIX_E3V_SAM_LIN12: start 62, 1 bit, little-endian, data-type-policy=OVERRIDE, i-signal-type=PRIMITIVE, init-value=0, base-type=BT_BCM_P_Mode_FH_Reversierschwelle, compu {0=Cx0_inaktiv (CM_BCM_P_Mode_FH_Reversierschwelle_Cx0_inaktiv), 1=Cx1_aktiv (CM_BCM_P_Mode_FH_Reversierschwelle_Cx1_aktiv)}, range raw 0..1, transfer-property=PENDING  # Aktivierung der P-Mode-Fensterheber-Reversierschwelle
            signal TSG_FHSG_HI_Ausstieg_XIX_TSG_FHe01_XIX_E3V_SAM_LIN12: start 63, 1 bit, little-endian, data-type-policy=OVERRIDE, i-signal-type=PRIMITIVE, init-value=0, base-type=BT_TSG_FHSG_HI_Ausstieg, compu {0=Cx0_inaktiv (CM_TSG_FHSG_HI_Ausstieg_Cx0_inaktiv), 1=Cx1_aktiv (CM_TSG_FHSG_HI_Ausstieg_Cx1_aktiv)}, range raw 0..1, transfer-property=PENDING  # Einschalten der Ausstiegsleuchten oder Türwarnleuchten in Tür oder im Schweller
        pdu triggering PT_E3V_SAM_LIN12_XIX_TPCHType_LIN_Diagnose_XIX_0x0_XIX_0x52_XIX_Physical: pdu=DCM_E3V_SAM_LIN12_XIX_TPCHType_LIN_Diagnose_XIX_0x0_XIX_0x52_XIX_Physical, from SAM
        pdu triggering PT_E3V_SAM_LIN12_XIX_TPCHType_LIN_Diagnose_XIX_0x0_XIX_0x53_XIX_Physical: pdu=DCM_E3V_SAM_LIN12_XIX_TPCHType_LIN_Diagnose_XIX_0x0_XIX_0x53_XIX_Physical, from SAM
        pdu triggering PT_E3V_SAM_LIN12_XIX_TPCHType_LIN_Diagnose_XIX_0x52_XIX_0x0_XIX_Physical: pdu=DCM_E3V_SAM_LIN12_XIX_TPCHType_LIN_Diagnose_XIX_0x52_XIX_0x0_XIX_Physical, to SAM
        pdu triggering PT_E3V_SAM_LIN12_XIX_TPCHType_LIN_Diagnose_XIX_0x53_XIX_0x0_XIX_Physical: pdu=DCM_E3V_SAM_LIN12_XIX_TPCHType_LIN_Diagnose_XIX_0x53_XIX_0x0_XIX_Physical, to SAM
        lin schedule table DiagRequest: resume-position=CONTINUE-AT-IT-POSITION, run-mode=RUN-ONCE, application-entry{delay=0.01, position-in-table=0, frame-triggering=CHNL/FT_MasterReq}
        lin schedule table DiagResponse: resume-position=CONTINUE-AT-IT-POSITION, run-mode=RUN-ONCE, application-entry{delay=0.01, position-in-table=0, frame-triggering=CHNL/FT_SlaveResp}
        lin schedule table st_main: resume-position=CONTINUE-AT-IT-POSITION, run-mode=RUN-CONTINUOUS
          table-entrys:
            delay=0.02, position-in-table=0, frame-triggering=FT_FHSGe01
            delay=0.01, position-in-table=1, frame-triggering=FT_FHSG_HFSs01
            delay=0.01, position-in-table=2, frame-triggering=FT_FHSG_HBFSs01
            delay=0.02, position-in-table=3, frame-triggering=FT_TSG_FHe01
            delay=0.01, position-in-table=4, frame-triggering=FT_FHSGe01
            delay=0.05, position-in-table=5, frame-triggering=FT_DIAGNOSEe_01
package /NmConfig
  nm config NmConfig: can-nm-cluster-coupling{coupled-cluster=[NmCluster_E3V_CCAN, NmCluster_E3V_K2CANFD], nm-busload-reduction-enabled=false, nm-immediate-restart-enabled=false}
    can nm cluster NmCluster_E3V_CCAN: communication-cluster=E3V_CCAN, nm-channel-sleep-master=false, nm-synchronizing-network=false, nm-busload-reduction-active=false, nm-cbv-position=1, nm-immediate-nm-cycle-time=0.01, nm-immediate-nm-transmissions=10, nm-message-timeout-time=0.1, nm-msg-cycle-time=0.2, nm-network-timeout=1.0, nm-nid-position=0, nm-remote-sleep-indication-time=0, nm-repeat-message-time=4.0, nm-wait-bus-sleep-time=0.75
      can nm node NmNode_SAM_XIX_E3V_CCAN:
        controller=CT_E3V_CCAN
        nm-if-ecu=NmEcu_SAM
        nm-passive-mode-enabled=false
        rx-nm-pdu=[NMH_Gateway_XIX_E3V_CCAN, NMH_Kessy_XIX_E3V_CCAN, NMH_Kessy2_XIX_E3V_CCAN, NMH_NFC_TGS_XIX_E3V_CCAN, NMH_RSAD_HL_XIX_E3V_CCAN, NMH_RSAD_HR_XIX_E3V_CCAN, NMH_RSAD_IN_XIX_E3V_CCAN, NMH_RSAD_VL_XIX_E3V_CCAN, NMH_RSAD_VR_XIX_E3V_CCAN, NMH_eCall_XIX_E3V_CCAN]
        tx-nm-pdu=NMH_BCM1_XIX_E3V_CCAN
        nm-car-wake-up-rx-enabled=false
        nm-msg-cycle-offset=0
    can nm cluster NmCluster_E3V_K2CANFD: communication-cluster=E3V_K2CANFD, nm-channel-sleep-master=false, nm-synchronizing-network=false, nm-busload-reduction-active=false, nm-cbv-position=1, nm-immediate-nm-cycle-time=0.01, nm-immediate-nm-transmissions=10, nm-message-timeout-time=0.1, nm-msg-cycle-time=0.2, nm-network-timeout=1.0, nm-nid-position=0, nm-remote-sleep-indication-time=0, nm-repeat-message-time=4.0, nm-wait-bus-sleep-time=0.75
      can nm node NmNode_SAM_XIX_E3V_K2CANFD: controller=CT_E3V_K2CANFD, nm-if-ecu=NmEcu_SAM, nm-passive-mode-enabled=false, rx-nm-pdu=[NMH_ELV_XIX_E3V_K2CANFD, NMH_Gateway_XIX_E3V_K2CANFD, NMH_MFG_XIX_E3V_K2CANFD, NMH_WLC1_XIX_E3V_K2CANFD], tx-nm-pdu=NMH_BCM1_XIX_E3V_K2CANFD, nm-car-wake-up-rx-enabled=false, nm-msg-cycle-offset=0
    nm-if-ecus:
      nm ecu NmEcu_SAM: ecu-instance=SAM, nm-bus-synchronization-enabled=false, nm-com-control-enabled=false, nm-node-detection-enabled=false, nm-node-id-enabled=false, nm-pdu-rx-indication-enabled=true, nm-remote-sleep-ind-enabled=false, nm-repeat-msg-ind-enabled=false, nm-state-change-ind-enabled=true, nm-user-data-enabled=true
